VERSION ""

NS_ :

BS_:

BU_: PowertrainControlModule AtmosphericSensor SafetyRestraintSystem2 Aftertreatment_2_GasOutlet Aftertreatment_2_GasIntake DieselParticulateFilterControl Turbocharger SafetyRestraintSystem1 CabDisplay2 Aftertreatment_1_GasOutlet Aftertreatment_1_GasIntake OnBoardDataLogger OffBoardDiagnosticTool2 OffBoardDiagnosticTool1 FileServer ParkingBrakeController SeatController2 FanDriveController SteeringColumnUnit CommunicationUnitRadio CommunicationUnitSatellite CommunicationUnitCellular PropulsionBatteryCharger ChassisController2 ChassisController1 EngineValveControl AuxiliaryHeater2 AuxiliaryHeater1 ClutchUnit RampControl InformationSystem1 SuspensionSystemController2 OilSensor VehicleDynamicStability ExhaustEmissionController TransmissionDisplay2 TransmissionDisplay1 ClimateControl2 WaterPumpController RearAxleSteeringController LightingOperatorControl SeatController1 IgnitionController2 IgnitionController1 TirePressureController CabController2 CabController1 PneumaticSystemController SuspensionSystemController1 HydraulicPumpController EnduranceBrakingSystem RetarderExhaustEngine2 OnBoardDiagnosticUnit HeadwayController RetarderExhaustEngine1 CabDisplay1 ManagementComputer VirtualTerminal OffVehicleGateway PowerTakeOffFront HitchControl AuxiliaryValveControl BodyController TractorTrailerBridge1 StarterSystem ElectricalSystem VehicleSecurity VehicleNavigation AerodynamicControl ElectricalChargingSystem ClimateControl1 TripRecorder InstrumentCluster SuspensionDriveAxle2 SuspensionDriveAxle1 SuspensionSteerAxle SteeringController FuelSystem CruiseControl RetarderDriveline RetarderEngine BrakesDriveAxle2 BrakesDriveAxle1 BrakesSystemController BrakesSteerAxle AxleDrive2 AxleDrive1 AxleSteering PowerTakeOff ShiftConsoleSecondary ShiftConsolePrimary Transmission2 Transmission1 Engine2 Engine1

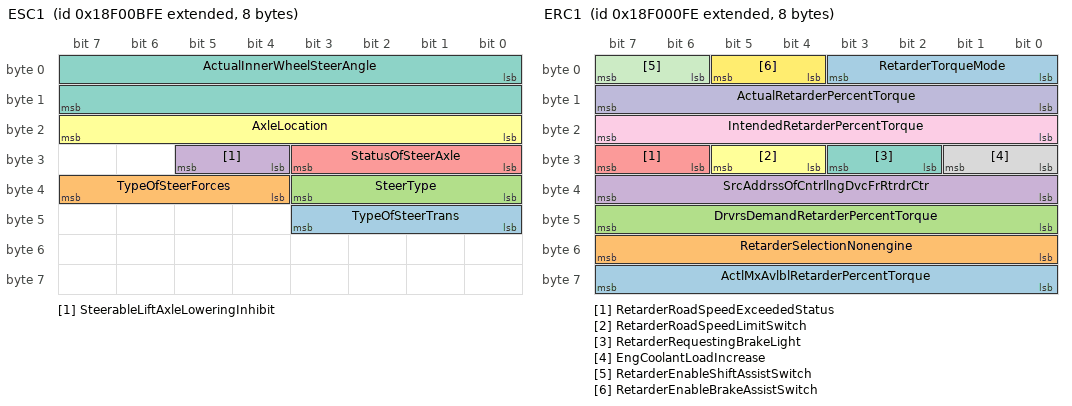
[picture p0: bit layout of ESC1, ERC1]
BO_ 2565868542 ESC1: 8 Vector__XXX
 SG_ TypeOfSteerTrans : 40|4@1+ (1,0) [0|15] "" Vector__XXX
 SG_ TypeOfSteerForces : 36|4@1+ (1,0) [0|15] "" Vector__XXX
 SG_ SteerType : 32|4@1+ (1,0) [0|15] "" Vector__XXX
 SG_ SteerableLiftAxleLoweringInhibit : 28|2@1+ (1,0) [0|3] "" Vector__XXX
 SG_ StatusOfSteerAxle : 24|4@1+ (1,0) [0|15] "" Vector__XXX
 SG_ AxleLocation : 16|8@1+ (1,0) [0|255] "" Vector__XXX
 SG_ ActualInnerWheelSteerAngle : 0|16@1+ (0.00390625,-125) [-125|125] "deg" Vector__XXX

BO_ 2633941758 ERC2: 8 Vector__XXX
 SG_ CrsCtrlRetarderActiveSpeedOffset : 8|16@1+ (0.00390625,-125) [0|125.996] "km/h" Vector__XXX
 SG_ TransOutputRetarder : 0|2@1+ (1,0) [0|3] "" Vector__XXX

BO_ 2565865726 ERC1: 8 Vector__XXX
 SG_ ActlMxAvlblRetarderPercentTorque : 56|8@1+ (1,-125) [-125|0] "%" Vector__XXX
 SG_ RetarderSelectionNonengine : 48|8@1+ (0.4,0) [0|100] "%" Vector__XXX
 SG_ DrvrsDemandRetarderPercentTorque : 40|8@1+ (1,-125) [-125|0] "%" Vector__XXX
 SG_ SrcAddrssOfCntrllngDvcFrRtrdrCtr : 32|8@1+ (1,0) [0|253] "" Vector__XXX
 SG_ RetarderRoadSpeedExceededStatus : 30|2@1+ (1,0) [0|3] "" Vector__XXX
 SG_ RetarderRoadSpeedLimitSwitch : 28|2@1+ (1,0) [0|3] "" Vector__XXX
 SG_ RetarderRequestingBrakeLight : 26|2@1+ (1,0) [0|3] "" Vector__XXX
 SG_ EngCoolantLoadIncrease : 24|2@1+ (1,0) [0|3] "" Vector__XXX
 SG_ IntendedRetarderPercentTorque : 16|8@1+ (1,-125) [-125|0] "%" Vector__XXX
 SG_ ActualRetarderPercentTorque : 8|8@1+ (1,-125) [-125|0] "%" Vector__XXX
 SG_ RetarderEnableShiftAssistSwitch : 6|2@1+ (1,0) [0|3] "" Vector__XXX
 SG_ RetarderEnableBrakeAssistSwitch : 4|2@1+ (1,0) [0|3] "" Vector__XXX
 SG_ RetarderTorqueMode : 0|4@1+ (1,0) [0|15] "" Vector__XXX

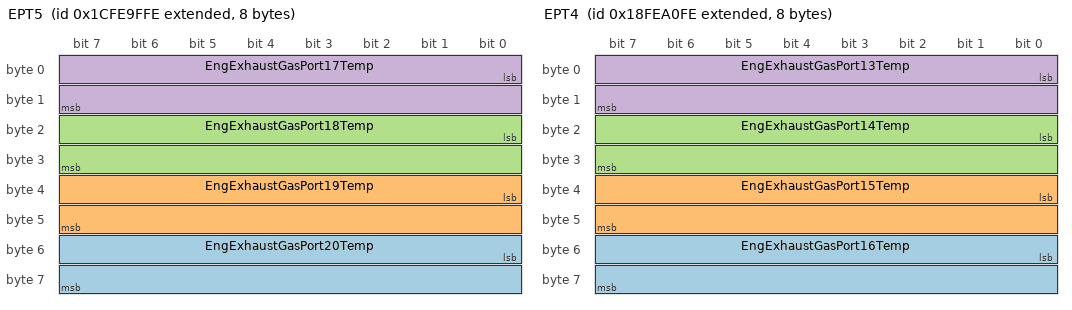
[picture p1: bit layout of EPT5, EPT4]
BO_ 2633932798 EPT5: 8 Vector__XXX
 SG_ EngExhaustGasPort20Temp : 48|16@1+ (0.03125,-273) [-273|1734.96875] "캜" Vector__XXX
 SG_ EngExhaustGasPort19Temp : 32|16@1+ (0.03125,-273) [-273|1734.96875] "캜" Vector__XXX
 SG_ EngExhaustGasPort18Temp : 16|16@1+ (0.03125,-273) [-273|1734.96875] "캜" Vector__XXX
 SG_ EngExhaustGasPort17Temp : 0|16@1+ (0.03125,-273) [-273|1734.96875] "캜" Vector__XXX

BO_ 2566824190 EPT4: 8 Vector__XXX
 SG_ EngExhaustGasPort16Temp : 48|16@1+ (0.03125,-273) [-273|1734.96875] "캜" Vector__XXX
 SG_ EngExhaustGasPort15Temp : 32|16@1+ (0.03125,-273) [-273|1734.96875] "캜" Vector__XXX
 SG_ EngExhaustGasPort14Temp : 16|16@1+ (0.03125,-273) [-273|1734.96875] "캜" Vector__XXX
 SG_ EngExhaustGasPort13Temp : 0|16@1+ (0.03125,-273) [-273|1734.96875] "캜" Vector__XXX

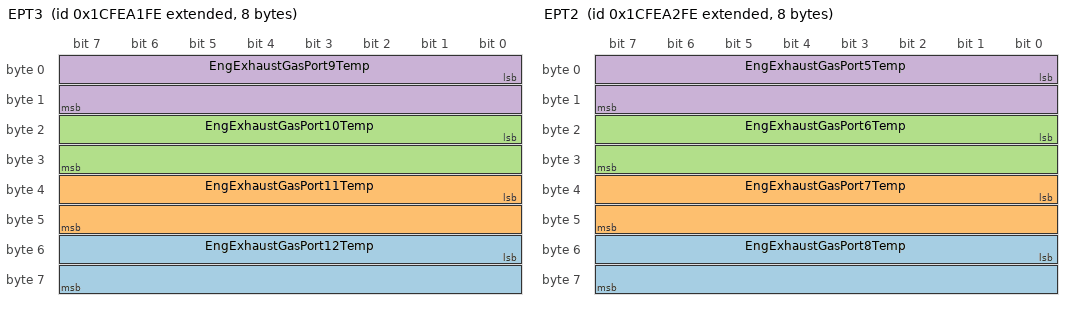
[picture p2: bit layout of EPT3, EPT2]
BO_ 2633933310 EPT3: 8 Vector__XXX
 SG_ EngExhaustGasPort12Temp : 48|16@1+ (0.03125,-273) [-273|1734.96875] "캜" Vector__XXX
 SG_ EngExhaustGasPort11Temp : 32|16@1+ (0.03125,-273) [-273|1734.96875] "캜" Vector__XXX
 SG_ EngExhaustGasPort10Temp : 16|16@1+ (0.03125,-273) [-273|1734.96875] "캜" Vector__XXX
 SG_ EngExhaustGasPort9Temp : 0|16@1+ (0.03125,-273) [-273|1734.96875] "캜" Vector__XXX

BO_ 2633933566 EPT2: 8 Vector__XXX
 SG_ EngExhaustGasPort8Temp : 48|16@1+ (0.03125,-273) [-273|1734.96875] "캜" Vector__XXX
 SG_ EngExhaustGasPort7Temp : 32|16@1+ (0.03125,-273) [-273|1734.96875] "캜" Vector__XXX
 SG_ EngExhaustGasPort6Temp : 16|16@1+ (0.03125,-273) [-273|1734.96875] "캜" Vector__XXX
 SG_ EngExhaustGasPort5Temp : 0|16@1+ (0.03125,-273) [-273|1734.96875] "캜" Vector__XXX

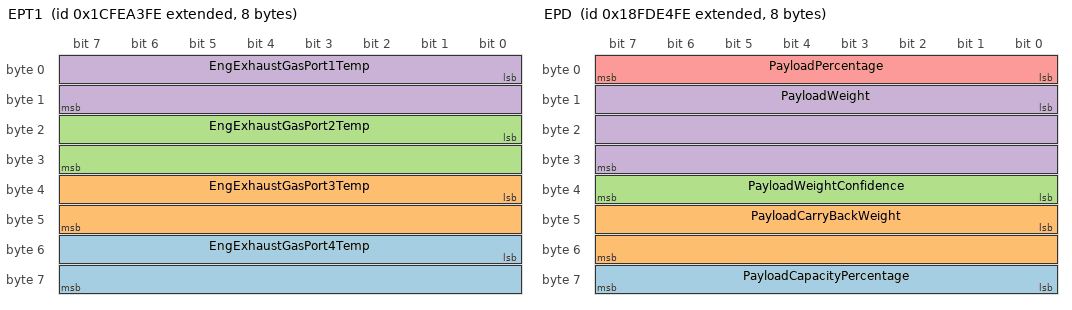
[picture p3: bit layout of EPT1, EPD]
BO_ 2633933822 EPT1: 8 Vector__XXX
 SG_ EngExhaustGasPort4Temp : 48|16@1+ (0.03125,-273) [-273|1734.96875] "캜" Vector__XXX
 SG_ EngExhaustGasPort3Temp : 32|16@1+ (0.03125,-273) [-273|1734.96875] "캜" Vector__XXX
 SG_ EngExhaustGasPort2Temp : 16|16@1+ (0.03125,-273) [-273|1734.96875] "캜" Vector__XXX
 SG_ EngExhaustGasPort1Temp : 0|16@1+ (0.03125,-273) [-273|1734.96875] "캜" Vector__XXX

BO_ 2566776062 EPD: 8 Vector__XXX
 SG_ PayloadCapacityPercentage : 56|8@1+ (1,0) [0|250] "%" Vector__XXX
 SG_ PayloadCarryBackWeight : 40|16@1+ (2,0) [0|128510] "kg" Vector__XXX
 SG_ PayloadWeightConfidence : 32|8@1+ (0.5,0) [0|100] "%" Vector__XXX
 SG_ PayloadWeight : 8|24@1+ (2,0) [0|32899070] "kg" Vector__XXX
 SG_ PayloadPercentage : 0|8@1+ (1,0) [0|250] "%" Vector__XXX

BO_ 2566771454 EP: 8 Vector__XXX
 SG_ DataMemoryUsage : 16|8@1+ (0.4,0) [0|100] "%" Vector__XXX
 SG_ KeepAliveBatteryConsumption : 0|16@1+ (1,0) [0|64255] "mAh" Vector__XXX

BO_ 2566775806 EOAC: 8 Vector__XXX
 SG_ TravelVelocityCtrlPos : 0|8@1+ (1,-125) [-125|125] "%" Vector__XXX

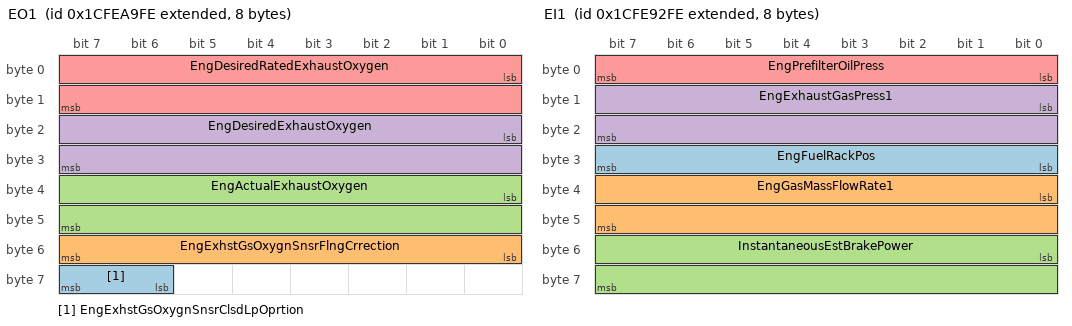
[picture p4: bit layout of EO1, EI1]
BO_ 2633935358 EO1: 8 Vector__XXX
 SG_ EngExhstGsOxygnSnsrClsdLpOprtion : 62|2@1+ (1,0) [0|3] "" Vector__XXX
 SG_ EngExhstGsOxygnSnsrFlngCrrection : 48|8@1+ (1,-125) [-125|125] "%" Vector__XXX
 SG_ EngActualExhaustOxygen : 32|16@1+ (0.0025,0) [0|160.6375] "%" Vector__XXX
 SG_ EngDesiredExhaustOxygen : 16|16@1+ (0.0025,0) [0|160.6375] "%" Vector__XXX
 SG_ EngDesiredRatedExhaustOxygen : 0|16@1+ (0.0025,0) [0|160.6375] "%" Vector__XXX

BO_ 2365447166 EJM3: 8 Vector__XXX
 SG_ Joystick3Button13PressedStatus : 62|2@1+ (1,0) [0|3] "" Vector__XXX
 SG_ Joystick3Button14PressedStatus : 60|2@1+ (1,0) [0|3] "" Vector__XXX
 SG_ Joystick3Button15PressedStatus : 58|2@1+ (1,0) [0|3] "" Vector__XXX
 SG_ Joystick3Button16PressedStatus : 56|2@1+ (1,0) [0|3] "" Vector__XXX
 SG_ Jystick3GripXAxisDetentPosStatus : 54|2@1+ (1,0) [0|3] "" Vector__XXX
 SG_ Jystick3GripYAxisDetentPosStatus : 52|2@1+ (1,0) [0|3] "" Vector__XXX
 SG_ Jystick3ThetaAxisDetentPosStatus : 50|2@1+ (1,0) [0|3] "" Vector__XXX
 SG_ Joystick3ThetaAxisPos : 38|10@1+ (0.1,0) [0|100] "%" Vector__XXX
 SG_ Jystck3ThtAxsClckwsPstvPosStatus : 36|2@1+ (1,0) [0|3] "" Vector__XXX
 SG_ Jystck3ThetaAxisNeutralPosStatus : 32|2@1+ (1,0) [0|3] "" Vector__XXX
 SG_ Joystick3GripYAxisPos : 22|10@1+ (0.1,0) [0|100] "%" Vector__XXX
 SG_ Jystck3GrpYAxsLvrFrwrdPstvPsStts : 20|2@1+ (1,0) [0|3] "" Vector__XXX
 SG_ Jystck3GrpYAxsLvrBckNgtvPsStatus : 18|2@1+ (1,0) [0|3] "" Vector__XXX
 SG_ Jystck3GripYAxisNeutralPosStatus : 16|2@1+ (1,0) [0|3] "" Vector__XXX
 SG_ Joystick3GripXAxisPos : 6|10@1+ (0.1,0) [0|100] "%" Vector__XXX
 SG_ Jystck3GrpXAxsLvrRghtPstvPsSttus : 4|2@1+ (1,0) [0|3] "" Vector__XXX
 SG_ Jystck3GrpXAxsLvrLftNgtvPsStatus : 2|2@1+ (1,0) [0|3] "" Vector__XXX
 SG_ Jystck3GripXAxisNeutralPosStatus : 0|2@1+ (1,0) [0|3] "" Vector__XXX
 SG_ Jystck3ThtAxsCntrClckwsNgtvPsStt : 34|2@1+ (1,0) [0|3] "" Vector__XXX

BO_ 2365446654 EJM2: 8 Vector__XXX
 SG_ Joystick2Button13PressedStatus : 62|2@1+ (1,0) [0|3] "" Vector__XXX
 SG_ Joystick2Button14PressedStatus : 60|2@1+ (1,0) [0|3] "" Vector__XXX
 SG_ Joystick2Button15PressedStatus : 58|2@1+ (1,0) [0|3] "" Vector__XXX
 SG_ Joystick2Button16PressedStatus : 56|2@1+ (1,0) [0|3] "" Vector__XXX
 SG_ Jystick2GripXAxisDetentPosStatus : 54|2@1+ (1,0) [0|3] "" Vector__XXX
 SG_ Jystick2GripYAxisDetentPosStatus : 52|2@1+ (1,0) [0|3] "" Vector__XXX
 SG_ Jystick2ThetaAxisDetentPosStatus : 50|2@1+ (1,0) [0|3] "" Vector__XXX
 SG_ Joystick2ThetaAxisPos : 38|10@1+ (0.1,0) [0|100] "%" Vector__XXX
 SG_ Jystck2ThtAxsClckwsPstvPosStatus : 36|2@1+ (1,0) [0|3] "" Vector__XXX
 SG_ Jystck2ThetaAxisNeutralPosStatus : 32|2@1+ (1,0) [0|3] "" Vector__XXX
 SG_ Joystick2GripYAxisPos : 22|10@1+ (0.1,0) [0|100] "%" Vector__XXX
 SG_ Jystck2GrpYAxsLvrFrwrdPstvPsStts : 20|2@1+ (1,0) [0|3] "" Vector__XXX
 SG_ Jystck2GrpYAxsLvrBckNgtvPsStatus : 18|2@1+ (1,0) [0|3] "" Vector__XXX
 SG_ Jystck2GripYAxisNeutralPosStatus : 16|2@1+ (1,0) [0|3] "" Vector__XXX
 SG_ Joystick2GripXAxisPos : 6|10@1+ (0.1,0) [0|100] "%" Vector__XXX
 SG_ Jystck2GrpXAxsLvrRghtPstvPsSttus : 4|2@1+ (1,0) [0|3] "" Vector__XXX
 SG_ Jystck2GrpXAxsLvrLftNgtvPsStatus : 2|2@1+ (1,0) [0|3] "" Vector__XXX
 SG_ Jystck2GripXAxisNeutralPosStatus : 0|2@1+ (1,0) [0|3] "" Vector__XXX
 SG_ Jystck2ThtAxsCntrClckwsNgtvPsStt : 34|2@1+ (1,0) [0|3] "" Vector__XXX

BO_ 2365446142 EJM1: 8 Vector__XXX
 SG_ Joystick1Button13PressedStatus : 62|2@1+ (1,0) [0|3] "" Vector__XXX
 SG_ Joystick1Button14PressedStatus : 60|2@1+ (1,0) [0|3] "" Vector__XXX
 SG_ Joystick1Button15PressedStatus : 58|2@1+ (1,0) [0|3] "" Vector__XXX
 SG_ Joystick1Button16PressedStatus : 56|2@1+ (1,0) [0|3] "" Vector__XXX
 SG_ Jystick1GripXAxisDetentPosStatus : 54|2@1+ (1,0) [0|3] "" Vector__XXX
 SG_ Jystick1GripYAxisDetentPosStatus : 52|2@1+ (1,0) [0|3] "" Vector__XXX
 SG_ Jystick1ThetaAxisDetentPosStatus : 50|2@1+ (1,0) [0|3] "" Vector__XXX
 SG_ Joystick1ThetaAxisPos : 38|10@1+ (0.1,0) [0|100] "%" Vector__XXX
 SG_ Jystck1ThtAxsClckwsPstvPosStatus : 36|2@1+ (1,0) [0|3] "" Vector__XXX
 SG_ Jystck1ThetaAxisNeutralPosStatus : 32|2@1+ (1,0) [0|3] "" Vector__XXX
 SG_ Joystick1GripYAxisPos : 22|10@1+ (0.1,0) [0|100] "%" Vector__XXX
 SG_ Jystck1GrpYAxsLvrFrwrdPstvPsStts : 20|2@1+ (1,0) [0|3] "" Vector__XXX
 SG_ Jystck1GrpYAxsLvrBckNgtvPsStatus : 18|2@1+ (1,0) [0|3] "" Vector__XXX
 SG_ Aftrtrtmnt1DslExhstFldPrprtsPrlm : 16|2@1+ (1,0) [0|3] "" Vector__XXX
 SG_ Joystick1GripXAxisPos : 6|10@1+ (0.1,0) [0|100] "%" Vector__XXX
 SG_ Jystck1GrpXAxsLvrRghtPstvPsSttus : 4|2@1+ (1,0) [0|3] "" Vector__XXX
 SG_ Jystck1GrpXAxsLvrLftNgtvPsStatus : 2|2@1+ (1,0) [0|3] "" Vector__XXX
 SG_ Jystck1GripXAxisNeutralPosStatus : 0|2@1+ (1,0) [0|3] "" Vector__XXX
 SG_ Jystck1ThtAxsCntrClckwsNgtvPsStt : 34|2@1+ (1,0) [0|3] "" Vector__XXX

BO_ 2633929470 EI1: 8 Vector__XXX
 SG_ EngFuelRackPos : 24|8@1+ (0.4,0) [0|100] "%" Vector__XXX
 SG_ EngGasMassFlowRate1 : 32|16@1+ (0.05,0) [0|3212.75] "kg/h" Vector__XXX
 SG_ InstantaneousEstBrakePower : 48|16@1+ (0.5,0) [0|32127.5] "kW" Vector__XXX
 SG_ EngExhaustGasPress1 : 8|16@1+ (0.0078125,-250) [-250|251.99] "kPa" Vector__XXX
 SG_ EngPrefilterOilPress : 0|8@1+ (4,0) [0|1000] "kPa" Vector__XXX

BO_ 2633937406 EH: 8 Vector__XXX
 SG_ TotalECURunTime : 32|32@1+ (0.05,0) [0|210554060.75] "h" Vector__XXX
 SG_ TotalECUDistance : 0|32@1+ (0.125,0) [0|526385151.875] "km" Vector__XXX

BO_ 2364541694 EGF1: 8 Vector__XXX
 SG_ EngExhstGsRcrcltion2MassFlowRate : 32|16@1+ (0.05,0) [0|3212.75] "kg/h" Vector__XXX
 SG_ EngIntakeAirMassFlowRate : 16|16@1+ (0.05,0) [0|3212.75] "kg/h" Vector__XXX
 SG_ EngExhstGsRcrcltion1MassFlowRate : 0|16@1+ (0.05,0) [0|3212.75] "kg/h" Vector__XXX

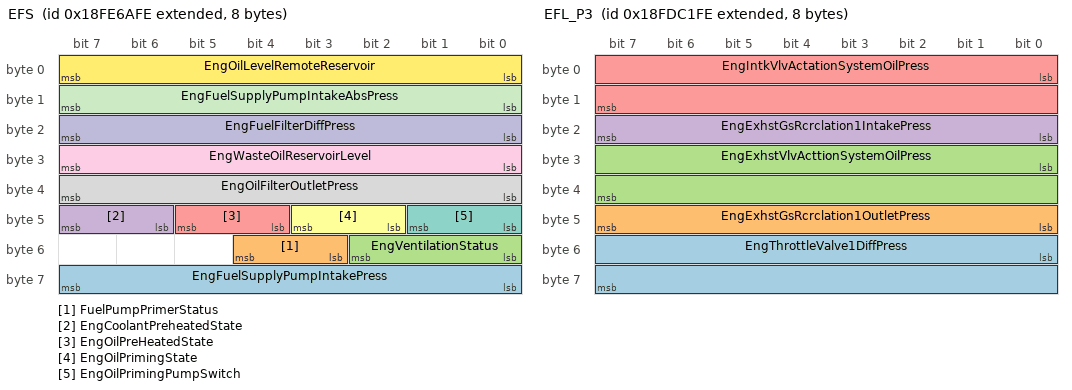
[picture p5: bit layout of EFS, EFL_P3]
BO_ 2566810366 EFS: 8 Vector__XXX
 SG_ EngFuelSupplyPumpIntakePress : 56|8@1+ (2,0) [0|500] "kPa" Vector__XXX
 SG_ FuelPumpPrimerStatus : 51|2@1+ (1,0) [0|3] "" Vector__XXX
 SG_ EngVentilationStatus : 48|3@1+ (1,0) [0|7] "" Vector__XXX
 SG_ EngCoolantPreheatedState : 46|2@1+ (1,0) [0|3] "" Vector__XXX
 SG_ EngOilPreHeatedState : 44|2@1+ (1,0) [0|3] "" Vector__XXX
 SG_ EngOilPrimingState : 42|2@1+ (1,0) [0|3] "" Vector__XXX
 SG_ EngOilPrimingPumpSwitch : 40|2@1+ (1,0) [0|3] "" Vector__XXX
 SG_ EngOilFilterOutletPress : 32|8@1+ (4,0) [0|1000] "kPa" Vector__XXX
 SG_ EngWasteOilReservoirLevel : 24|8@1+ (0.4,0) [0|100] "%" Vector__XXX
 SG_ EngFuelFilterDiffPress : 16|8@1+ (2,0) [0|500] "kPa" Vector__XXX
 SG_ EngFuelSupplyPumpIntakeAbsPress : 8|8@1+ (2,0) [0|500] "kPa" Vector__XXX
 SG_ EngOilLevelRemoteReservoir : 0|8@1+ (0.4,0) [0|100] "%" Vector__XXX

BO_ 2566767102 EFL_P3: 8 Vector__XXX
 SG_ EngThrottleValve1DiffPress : 48|16@1+ (0.1,0) [0|6425.5] "kPa" Vector__XXX
 SG_ EngExhstGsRcrclation1OutletPress : 40|8@1+ (2,0) [0|500] "kPa" Vector__XXX
 SG_ EngExhstVlvActtionSystemOilPress : 24|16@1+ (0.00390625,0) [0|250.996] "MPa" Vector__XXX
 SG_ EngExhstGsRcrclation1IntakePress : 16|8@1+ (2,0) [0|500] "kPa" Vector__XXX
 SG_ EngIntkVlvActationSystemOilPress : 0|16@1+ (0.00390625,0) [0|250.996] "MPa" Vector__XXX

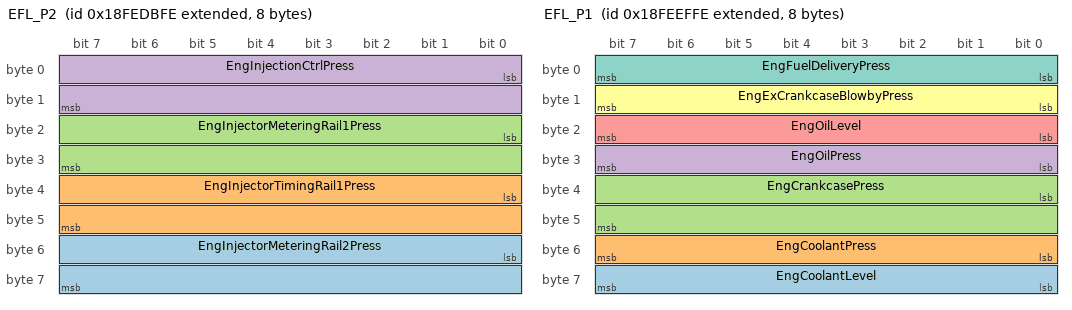
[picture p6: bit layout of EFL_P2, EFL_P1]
BO_ 2566839294 EFL_P2: 8 Vector__XXX
 SG_ EngInjectorMeteringRail2Press : 48|16@1+ (0.00390625,0) [0|250.996] "MPa" Vector__XXX
 SG_ EngInjectorTimingRail1Press : 32|16@1+ (0.00390625,0) [0|250.996] "MPa" Vector__XXX
 SG_ EngInjectorMeteringRail1Press : 16|16@1+ (0.00390625,0) [0|250.996] "MPa" Vector__XXX
 SG_ EngInjectionCtrlPress : 0|16@1+ (0.00390625,0) [0|250.996] "MPa" Vector__XXX

BO_ 2566844414 EFL_P1: 8 Vector__XXX
 SG_ EngCoolantLevel : 56|8@1+ (0.4,0) [0|100] "%" Vector__XXX
 SG_ EngCoolantPress : 48|8@1+ (2,0) [0|500] "kPa" Vector__XXX
 SG_ EngCrankcasePress : 32|16@1+ (0.0078125,-250) [-250|251.99] "kPa" Vector__XXX
 SG_ EngOilPress : 24|8@1+ (4,0) [0|1000] "kPa" Vector__XXX
 SG_ EngOilLevel : 16|8@1+ (0.4,0) [0|100] "%" Vector__XXX
 SG_ EngExCrankcaseBlowbyPress : 8|8@1+ (0.05,0) [0|12.5] "kPa" Vector__XXX
 SG_ EngFuelDeliveryPress : 0|8@1+ (4,0) [0|1000] "kPa" Vector__XXX

BO_ 2633929726 EES: 8 Vector__XXX
 SG_ SafetyWireStatus : 16|2@1+ (1,0) [0|3] "" Vector__XXX
 SG_ ElectricalLoad : 0|16@1+ (0.5,0) [0|32127.5] "kW" Vector__XXX

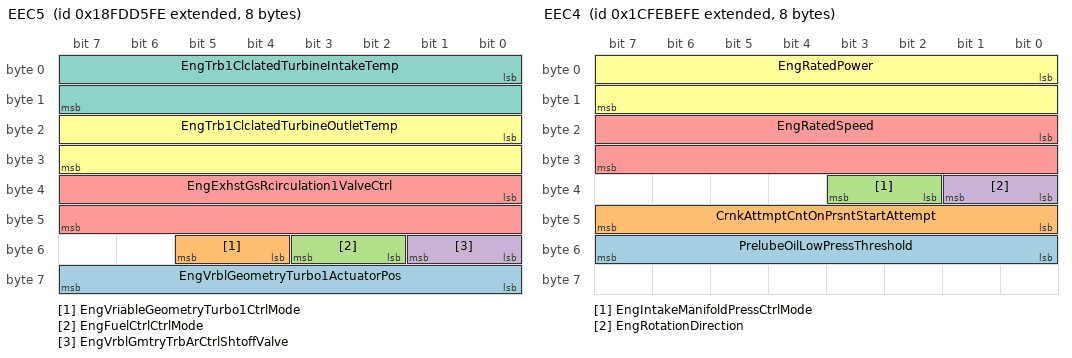
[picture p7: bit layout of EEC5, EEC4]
BO_ 2566772222 EEC5: 8 Vector__XXX
 SG_ EngVrblGeometryTurbo1ActuatorPos : 56|8@1+ (0.4,0) [0|100] "%" Vector__XXX
 SG_ EngVriableGeometryTurbo1CtrlMode : 52|2@1+ (1,0) [0|3] "" Vector__XXX
 SG_ EngFuelCtrlCtrlMode : 50|2@1+ (1,0) [0|3] "" Vector__XXX
 SG_ EngVrblGmtryTrbArCtrlShtoffValve : 48|2@1+ (1,0) [0|3] "" Vector__XXX
 SG_ EngExhstGsRcirculation1ValveCtrl : 32|16@1+ (0.0025,0) [0|100] "%" Vector__XXX
 SG_ EngTrb1ClclatedTurbineOutletTemp : 16|16@1+ (0.03125,-273) [-273|1734.96875] "캜" Vector__XXX
 SG_ EngTrb1ClclatedTurbineIntakeTemp : 0|16@1+ (0.03125,-273) [-273|1734.96875] "캜" Vector__XXX

BO_ 2633940734 EEC4: 8 Vector__XXX
 SG_ PrelubeOilLowPressThreshold : 48|8@1+ (4,0) [0|1000] "kPa" Vector__XXX
 SG_ CrnkAttmptCntOnPrsntStartAttempt : 40|8@1+ (1,0) [0|250] "" Vector__XXX
 SG_ EngIntakeManifoldPressCtrlMode : 34|2@1+ (1,0) [0|3] "" Vector__XXX
 SG_ EngRotationDirection : 32|2@1+ (1,0) [0|3] "" Vector__XXX
 SG_ EngRatedSpeed : 16|16@1+ (0.125,0) [0|8031.875] "rpm" Vector__XXX
 SG_ EngRatedPower : 0|16@1+ (0.5,0) [0|32127.5] "kW" Vector__XXX

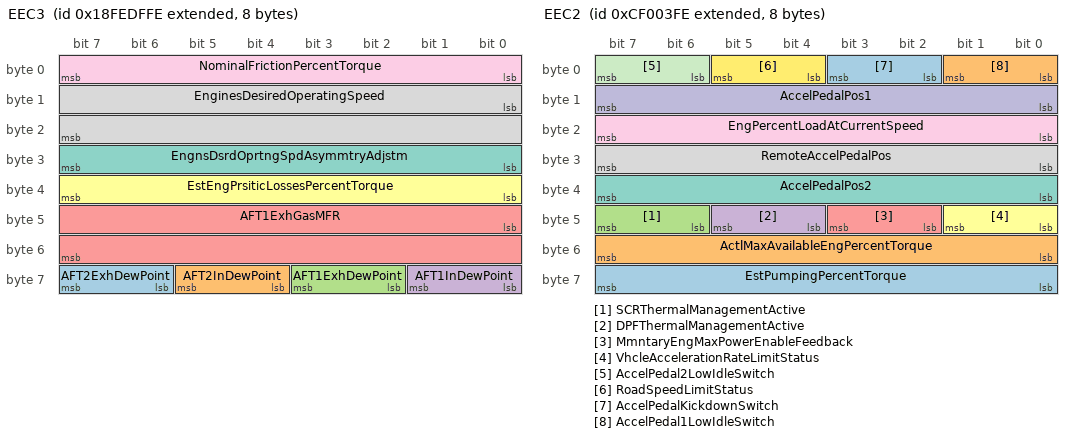
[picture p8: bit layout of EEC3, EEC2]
BO_ 2566840318 EEC3: 8 Vector__XXX
 SG_ AFT2ExhDewPoint : 62|2@1+ (1,0) [0|3] "" Vector__XXX
 SG_ AFT2InDewPoint : 60|2@1+ (1,0) [0|3] "" Vector__XXX
 SG_ AFT1ExhDewPoint : 58|2@1+ (1,0) [0|3] "" Vector__XXX
 SG_ AFT1InDewPoint : 56|2@1+ (1,0) [0|3] "" Vector__XXX
 SG_ AFT1ExhGasMFR : 40|16@1+ (0.2,0) [0|12851] "kg/h" Vector__XXX
 SG_ EstEngPrsiticLossesPercentTorque : 32|8@1+ (1,-125) [0|125] "%" Vector__XXX
 SG_ EngnsDsrdOprtngSpdAsymmtryAdjstm : 24|8@1+ (1,0) [0|250] "" Vector__XXX
 SG_ EnginesDesiredOperatingSpeed : 8|16@1+ (0.125,0) [0|8031.875] "rpm" Vector__XXX
 SG_ NominalFrictionPercentTorque : 0|8@1+ (1,-125) [-125|125] "%" Vector__XXX

BO_ 2364539902 EEC2: 8 Vector__XXX
 SG_ EstPumpingPercentTorque : 56|8@1+ (1,-125) [-125|125] "%" Vector__XXX
 SG_ ActlMaxAvailableEngPercentTorque : 48|8@1+ (0.4,0) [0|100] "%" Vector__XXX
 SG_ SCRThermalManagementActive : 46|2@1+ (1,0) [0|3] "" Vector__XXX
 SG_ DPFThermalManagementActive : 44|2@1+ (1,0) [0|3] "" Vector__XXX
 SG_ MmntaryEngMaxPowerEnableFeedback : 42|2@1+ (1,0) [0|3] "" Vector__XXX
 SG_ VhcleAccelerationRateLimitStatus : 40|2@1+ (1,0) [0|3] "" Vector__XXX
 SG_ AccelPedalPos2 : 32|8@1+ (0.4,0) [0|100] "%" Vector__XXX
 SG_ RemoteAccelPedalPos : 24|8@1+ (0.4,0) [0|100] "%" Vector__XXX
 SG_ EngPercentLoadAtCurrentSpeed : 16|8@1+ (1,0) [0|125] "%" Vector__XXX
 SG_ AccelPedalPos1 : 8|8@1+ (0.4,0) [0|100] "%" Vector__XXX
 SG_ AccelPedal2LowIdleSwitch : 6|2@1+ (1,0) [0|3] "" Vector__XXX
 SG_ RoadSpeedLimitStatus : 4|2@1+ (1,0) [0|3] "" Vector__XXX
 SG_ AccelPedalKickdownSwitch : 2|2@1+ (1,0) [0|3] "" Vector__XXX
 SG_ AccelPedal1LowIdleSwitch : 0|2@1+ (1,0) [0|3] "" Vector__XXX

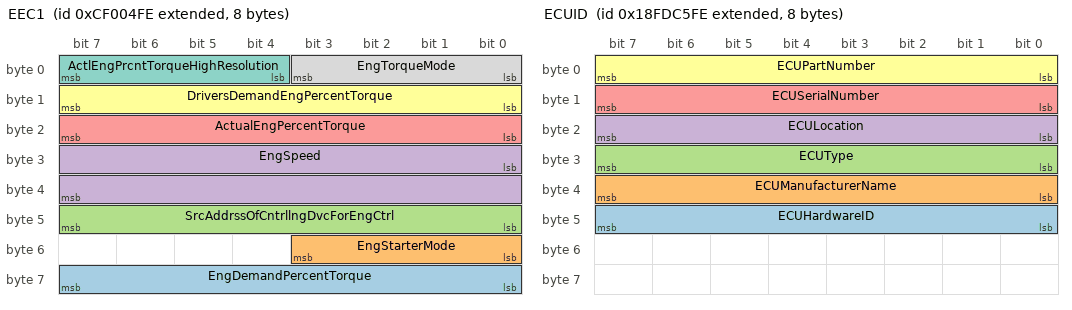
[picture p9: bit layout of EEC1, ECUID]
BO_ 2364540158 EEC1: 8 Vector__XXX
 SG_ EngDemandPercentTorque : 56|8@1+ (1,-125) [-125|125] "%" Vector__XXX
 SG_ EngStarterMode : 48|4@1+ (1,0) [0|15] "" Vector__XXX
 SG_ SrcAddrssOfCntrllngDvcForEngCtrl : 40|8@1+ (1,0) [0|253] "" Vector__XXX
 SG_ EngSpeed : 24|16@1+ (0.125,0) [0|8031.875] "rpm" Vector__XXX
 SG_ ActualEngPercentTorque : 16|8@1+ (1,-125) [0|125] "%" Vector__XXX
 SG_ DriversDemandEngPercentTorque : 8|8@1+ (1,-125) [0|125] "%" Vector__XXX
 SG_ ActlEngPrcntTorqueHighResolution : 4|4@1+ (0.125,0) [0|0.875] "%" Vector__XXX
 SG_ EngTorqueMode : 0|4@1+ (1,0) [0|15] "" Vector__XXX

BO_ 2566768126 ECUID: 8 Vector__XXX
 SG_ ECUHardwareID : 40|8@1+ (1,0) [0|255] "" Vector__XXX
 SG_ ECUManufacturerName : 32|8@1+ (1,0) [0|255] "" Vector__XXX
 SG_ ECUType : 24|8@1+ (1,0) [0|255] "" Vector__XXX
 SG_ ECULocation : 16|8@1+ (1,0) [0|255] "" Vector__XXX
 SG_ ECUSerialNumber : 8|8@1+ (1,0) [0|255] "" Vector__XXX
 SG_ ECUPartNumber : 0|8@1+ (1,0) [0|255] "" Vector__XXX

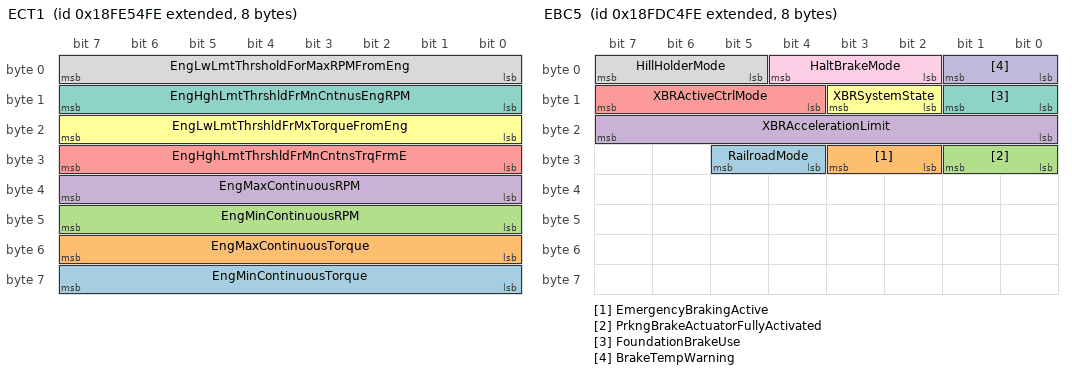
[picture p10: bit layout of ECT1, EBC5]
BO_ 2566804734 ECT1: 8 Vector__XXX
 SG_ EngMinContinuousTorque : 56|8@1+ (1,-125) [-125|125] "%" Vector__XXX
 SG_ EngMaxContinuousTorque : 48|8@1+ (1,-125) [-125|125] "%" Vector__XXX
 SG_ EngMinContinuousRPM : 40|8@1+ (32,0) [0|8000] "rpm" Vector__XXX
 SG_ EngMaxContinuousRPM : 32|8@1+ (32,0) [0|8000] "rpm" Vector__XXX
 SG_ EngHghLmtThrshldFrMnCntnsTrqFrmE : 24|8@1+ (1,-125) [-125|125] "%" Vector__XXX
 SG_ EngLwLmtThrshldFrMxTorqueFromEng : 16|8@1+ (1,-125) [-125|125] "%" Vector__XXX
 SG_ EngHghLmtThrshldFrMnCntnusEngRPM : 8|8@1+ (32,0) [0|8000] "rpm" Vector__XXX
 SG_ EngLwLmtThrsholdForMaxRPMFromEng : 0|8@1+ (32,0) [0|8000] "rpm" Vector__XXX

BO_ 2566841342 EC1: 40 Vector__XXX
 SG_ DefaultIdleTrqLmt : 312|8@1+ (1,-125) [0|125] "%" Vector__XXX
 SG_ SupportTSC1CtrlPurposeGroup4 : 304|8@1+ (1,0) [0|255] "" Vector__XXX
 SG_ SupportTSC1CtrlPurposeGroup3 : 296|8@1+ (1,0) [0|255] "" Vector__XXX
 SG_ SupportTSC1CtrlPurposeGroup2 : 288|8@1+ (1,0) [0|255] "" Vector__XXX
 SG_ SupportTSC1CtrlPurposeGroup1 : 280|8@1+ (1,0) [0|255] "" Vector__XXX
 SG_ SupportVariableRateTSC1Message : 272|8@1+ (1,0) [0|255] "" Vector__XXX
 SG_ EngDefaultTorqueLimit : 256|16@1+ (1,0) [0|64255] "Nm" Vector__XXX
 SG_ EngMomentOfInertia : 240|16@1+ (0.004,0) [0|257.02] "kg븁�" Vector__XXX
 SG_ EngExRngRqstdSpdCtrlRngUpprLimit : 224|16@1+ (0.125,0) [0|8031.875] "rpm" Vector__XXX
 SG_ EngRqstdTrqueCtrlRangeUpperLimit : 216|8@1+ (1,-125) [0|125] "%" Vector__XXX
 SG_ EngRqstdTrqueCtrlRangeLowerLimit : 208|8@1+ (1,-125) [0|125] "%" Vector__XXX
 SG_ EngRqstdSpeedCtrlRangeUpperLimit : 200|8@1+ (10,0) [0|2500] "rpm" Vector__XXX
 SG_ EngRqstdSpeedCtrlRangeLowerLimit : 192|8@1+ (10,0) [0|2500] "rpm" Vector__XXX
 SG_ EngMaxMomentaryOverrideTimeLimit : 184|8@1+ (0.1,0) [0|25] "s" Vector__XXX
 SG_ EngMxMmentaryOverrideSpeedPoint7 : 168|16@1+ (0.125,0) [0|8031.875] "rpm" Vector__XXX
 SG_ EngReferenceTorque : 152|16@1+ (1,0) [0|64255] "Nm" Vector__XXX
 SG_ EngGain : 136|16@1+ (0.00078125,0) [0|50.2] "%/rpm" Vector__XXX
 SG_ EngSpeedAtHighIdlePoint6 : 120|16@1+ (0.125,0) [0|8031.875] "rpm" Vector__XXX
 SG_ EngPercentTorqueAtPoint5 : 112|8@1+ (1,-125) [0|125] "%" Vector__XXX
 SG_ EngSpeedAtPoint5 : 96|16@1+ (0.125,0) [0|8031.875] "rpm" Vector__XXX
 SG_ EngPercentTorqueAtPoint4 : 88|8@1+ (1,-125) [0|125] "%" Vector__XXX
 SG_ EngSpeedAtPoint4 : 72|16@1+ (0.125,0) [0|8031.875] "rpm" Vector__XXX
 SG_ EngPercentTorqueAtPoint3 : 64|8@1+ (1,-125) [0|125] "%" Vector__XXX
 SG_ EngSpeedAtPoint3 : 48|16@1+ (0.125,0) [0|8031.875] "rpm" Vector__XXX
 SG_ EngPercentTorqueAtPoint2 : 40|8@1+ (1,-125) [0|125] "%" Vector__XXX
 SG_ EngSpeedAtPoint2 : 24|16@1+ (0.125,0) [0|8031.875] "rpm" Vector__XXX
 SG_ EngPercentTorqueAtIdlePoint1 : 16|8@1+ (1,-125) [0|125] "%" Vector__XXX
 SG_ EngSpeedAtIdlePoint1 : 0|16@1+ (0.125,0) [0|8031.875] "rpm" Vector__XXX

BO_ 2566767870 EBC5: 8 Vector__XXX
 SG_ RailroadMode : 28|2@1+ (1,0) [0|3] "" Vector__XXX
 SG_ EmergencyBrakingActive : 26|2@1+ (1,0) [0|3] "" Vector__XXX
 SG_ PrkngBrakeActuatorFullyActivated : 24|2@1+ (1,0) [0|3] "" Vector__XXX
 SG_ XBRAccelerationLimit : 16|8@1+ (0.1,-12.5) [-10|10] "m/s�" Vector__XXX
 SG_ XBRActiveCtrlMode : 12|4@1+ (1,0) [0|15] "" Vector__XXX
 SG_ XBRSystemState : 10|2@1+ (1,0) [0|3] "" Vector__XXX
 SG_ FoundationBrakeUse : 8|2@1+ (1,0) [0|3] "" Vector__XXX
 SG_ HillHolderMode : 5|3@1+ (1,0) [0|7] "" Vector__XXX
 SG_ HaltBrakeMode : 2|3@1+ (1,0) [0|7] "" Vector__XXX
 SG_ BrakeTempWarning : 0|2@1+ (1,0) [0|3] "" Vector__XXX

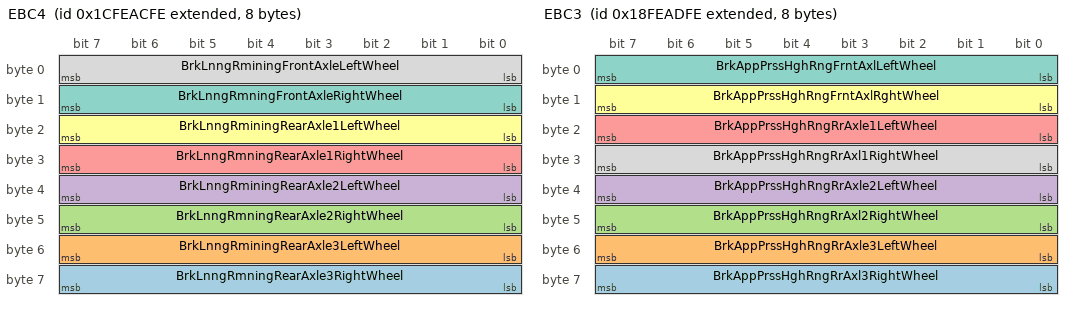
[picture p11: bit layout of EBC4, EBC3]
BO_ 2633936126 EBC4: 8 Vector__XXX
 SG_ BrkLnngRmningRearAxle3RightWheel : 56|8@1+ (0.4,0) [0|100] "%" Vector__XXX
 SG_ BrkLnngRminingRearAxle3LeftWheel : 48|8@1+ (0.4,0) [0|100] "%" Vector__XXX
 SG_ BrkLnngRmningRearAxle2RightWheel : 40|8@1+ (0.4,0) [0|100] "%" Vector__XXX
 SG_ BrkLnngRminingRearAxle2LeftWheel : 32|8@1+ (0.4,0) [0|100] "%" Vector__XXX
 SG_ BrkLnngRmningRearAxle1RightWheel : 24|8@1+ (0.4,0) [0|100] "%" Vector__XXX
 SG_ BrkLnngRminingRearAxle1LeftWheel : 16|8@1+ (0.4,0) [0|100] "%" Vector__XXX
 SG_ BrkLnngRmningFrontAxleRightWheel : 8|8@1+ (0.4,0) [0|100] "%" Vector__XXX
 SG_ BrkLnngRminingFrontAxleLeftWheel : 0|8@1+ (0.4,0) [0|100] "%" Vector__XXX

BO_ 2566827518 EBC3: 8 Vector__XXX
 SG_ BrkAppPrssHghRngRrAxl3RightWheel : 56|8@1+ (5,0) [0|1250] "kPa" Vector__XXX
 SG_ BrkAppPrssHghRngRrAxle3LeftWheel : 48|8@1+ (5,0) [0|1250] "kPa" Vector__XXX
 SG_ BrkAppPrssHghRngRrAxl2RightWheel : 40|8@1+ (5,0) [0|1250] "kPa" Vector__XXX
 SG_ BrkAppPrssHghRngRrAxle2LeftWheel : 32|8@1+ (5,0) [0|1250] "kPa" Vector__XXX
 SG_ BrkAppPrssHghRngRrAxle1LeftWheel : 16|8@1+ (5,0) [0|1250] "kPa" Vector__XXX
 SG_ BrkAppPrssHghRngFrntAxlRghtWheel : 8|8@1+ (5,0) [0|1250] "kPa" Vector__XXX
 SG_ BrkAppPrssHghRngFrntAxlLeftWheel : 0|8@1+ (5,0) [0|1250] "kPa" Vector__XXX
 SG_ BrkAppPrssHghRngRrAxl1RightWheel : 24|8@1+ (5,0) [0|1250] "kPa" Vector__XXX

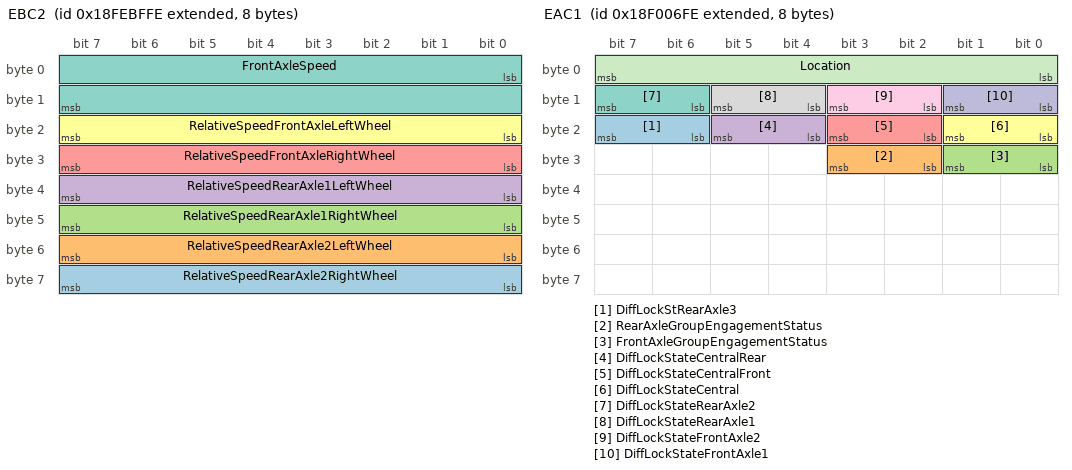
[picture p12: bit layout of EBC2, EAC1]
BO_ 2566832126 EBC2: 8 Vector__XXX
 SG_ RelativeSpeedRearAxle2RightWheel : 56|8@1+ (0.0625,-7.8125) [-7.8125|7.8125] "km/h" Vector__XXX
 SG_ RelativeSpeedRearAxle2LeftWheel : 48|8@1+ (0.0625,-7.8125) [-7.8125|7.8125] "km/h" Vector__XXX
 SG_ RelativeSpeedRearAxle1RightWheel : 40|8@1+ (0.0625,-7.8125) [-7.8125|7.8125] "km/h" Vector__XXX
 SG_ RelativeSpeedRearAxle1LeftWheel : 32|8@1+ (0.0625,-7.8125) [-7.8125|7.8125] "km/h" Vector__XXX
 SG_ RelativeSpeedFrontAxleRightWheel : 24|8@1+ (0.0625,-7.8125) [-7.8125|7.8125] "km/h" Vector__XXX
 SG_ RelativeSpeedFrontAxleLeftWheel : 16|8@1+ (0.0625,-7.8125) [-7.8125|7.8125] "km/h" Vector__XXX
 SG_ FrontAxleSpeed : 0|16@1+ (0.00390625,0) [0|250.996] "km/h" Vector__XXX

BO_ 2565865982 EBC1: 8 Vector__XXX
 SG_ RailroadModeSw : 56|2@1+ (1,0) [0|3] "" Vector__XXX
 SG_ TrctrMntdTrailerABSWarningSignal : 62|2@1+ (1,0) [0|3] "" Vector__XXX
 SG_ TrailerABSStatus : 60|2@1+ (1,0) [0|3] "" Vector__XXX
 SG_ HaltBrakeSwitch : 58|2@1+ (1,0) [0|3] "" Vector__XXX
 SG_ SrcAddrssOfCntrllngDvcFrBrkeCtrl : 48|8@1+ (1,0) [0|253] "" Vector__XXX
 SG_ ATC_ASRInformationSignal : 46|2@1+ (1,0) [0|3] "" Vector__XXX
 SG_ ABS_EBSAmberWarningSignal : 44|2@1+ (1,0) [0|3] "" Vector__XXX
 SG_ EBSRedWarningSignal : 42|2@1+ (1,0) [0|3] "" Vector__XXX
 SG_ ABSFullyOperational : 40|2@1+ (1,0) [0|3] "" Vector__XXX
 SG_ EngRetarderSelection : 32|8@1+ (0.4,0) [0|100] "%" Vector__XXX
 SG_ RemoteAccelEnableSwitch : 30|2@1+ (1,0) [0|3] "" Vector__XXX
 SG_ EngAuxShutdownSwitch : 28|2@1+ (1,0) [0|3] "" Vector__XXX
 SG_ EngDerateSwitch : 26|2@1+ (1,0) [0|3] "" Vector__XXX
 SG_ AccelInterlockSwitch : 24|2@1+ (1,0) [0|3] "" Vector__XXX
 SG_ TractionCtrlOverrideSwitch : 22|2@1+ (1,0) [0|3] "" Vector__XXX
 SG_ ASRHillHolderSwitch : 20|2@1+ (1,0) [0|3] "" Vector__XXX
 SG_ ASROffroadSwitch : 18|2@1+ (1,0) [0|3] "" Vector__XXX
 SG_ ABSOffroadSwitch : 16|2@1+ (1,0) [0|3] "" Vector__XXX
 SG_ BrakePedalPos : 8|8@1+ (0.4,0) [0|100] "%" Vector__XXX
 SG_ EBSBrakeSwitch : 6|2@1+ (1,0) [0|3] "" Vector__XXX
 SG_ AntiLockBrakingActive : 4|2@1+ (1,0) [0|3] "" Vector__XXX
 SG_ ASRBrakeCtrlActive : 2|2@1+ (1,0) [0|3] "" Vector__XXX
 SG_ ASREngCtrlActive : 0|2@1+ (1,0) [0|3] "" Vector__XXX

BO_ 2565867262 EAC1: 8 Vector__XXX
 SG_ DiffLockStRearAxle3 : 22|2@1+ (1,0) [0|3] "" Vector__XXX
 SG_ RearAxleGroupEngagementStatus : 26|2@1+ (1,0) [0|3] "" Vector__XXX
 SG_ FrontAxleGroupEngagementStatus : 24|2@1+ (1,0) [0|3] "" Vector__XXX
 SG_ DiffLockStateCentralRear : 20|2@1+ (1,0) [0|3] "" Vector__XXX
 SG_ DiffLockStateCentralFront : 18|2@1+ (1,0) [0|3] "" Vector__XXX
 SG_ DiffLockStateCentral : 16|2@1+ (1,0) [0|3] "" Vector__XXX
 SG_ DiffLockStateRearAxle2 : 14|2@1+ (1,0) [0|3] "" Vector__XXX
 SG_ DiffLockStateRearAxle1 : 12|2@1+ (1,0) [0|3] "" Vector__XXX
 SG_ DiffLockStateFrontAxle2 : 10|2@1+ (1,0) [0|3] "" Vector__XXX
 SG_ DiffLockStateFrontAxle1 : 8|2@1+ (1,0) [0|3] "" Vector__XXX
 SG_ Location : 0|8@1+ (1,0) [0|255] "" Vector__XXX

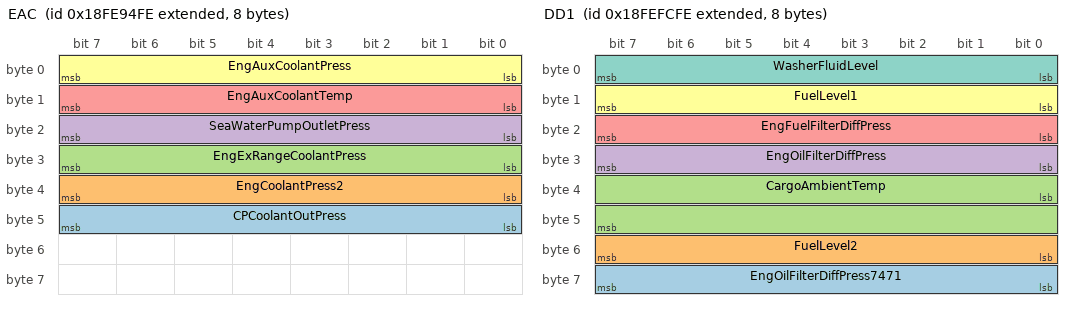
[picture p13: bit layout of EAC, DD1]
BO_ 2566821118 EAC: 8 Vector__XXX
 SG_ CPCoolantOutPress : 40|8@1+ (2,0) [0|500] "kPa" Vector__XXX
 SG_ EngCoolantPress2 : 32|8@1+ (4,0) [0|1000] "kPa" Vector__XXX
 SG_ EngExRangeCoolantPress : 24|8@1+ (4,0) [0|1000] "kPa" Vector__XXX
 SG_ SeaWaterPumpOutletPress : 16|8@1+ (2,0) [0|500] "kPa" Vector__XXX
 SG_ EngAuxCoolantTemp : 8|8@1+ (1,-40) [-40|210] "캜" Vector__XXX
 SG_ EngAuxCoolantPress : 0|8@1+ (4,0) [0|1000] "kPa" Vector__XXX

BO_ 2566810622 DI: 8 Vector__XXX
 SG_ Driver2Identification : 8|8@1+ (1,0) [0|255] "" Vector__XXX
 SG_ Driver1Identification : 0|8@1+ (1,0) [0|255] "" Vector__XXX

BO_ 2566847742 DD1: 8 Vector__XXX
 SG_ EngOilFilterDiffPress7471 : 56|8@1+ (5,0) [0|1250] "kPa" Vector__XXX
 SG_ FuelLevel2 : 48|8@1+ (0.4,0) [0|100] "%" Vector__XXX
 SG_ CargoAmbientTemp : 32|16@1+ (0.03125,-273) [-273|1734.96875] "캜" Vector__XXX
 SG_ EngOilFilterDiffPress : 24|8@1+ (0.5,0) [0|125] "kPa" Vector__XXX
 SG_ EngFuelFilterDiffPress : 16|8@1+ (2,0) [0|500] "kPa" Vector__XXX
 SG_ FuelLevel1 : 8|8@1+ (0.4,0) [0|100] "%" Vector__XXX
 SG_ WasherFluidLevel : 0|8@1+ (0.4,0) [0|100] "%" Vector__XXX

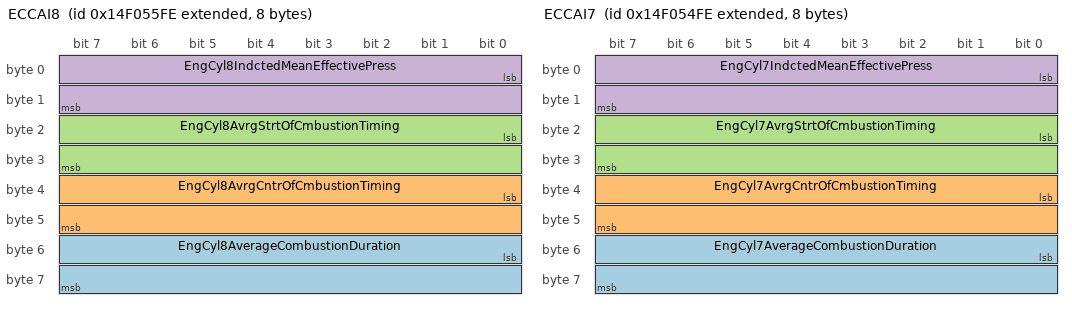
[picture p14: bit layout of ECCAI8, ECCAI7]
BO_ 2498778622 ECCAI8: 8 Vector__XXX
 SG_ EngCyl8AverageCombustionDuration : 48|16@1+ (0.0078125,0) [0|501.99] "deg" Vector__XXX
 SG_ EngCyl8AvrgCntrOfCmbustionTiming : 32|16@1+ (0.0078125,-250) [-250|250.992] "deg" Vector__XXX
 SG_ EngCyl8AvrgStrtOfCmbustionTiming : 16|16@1+ (0.0078125,-250) [-250|250.992] "deg" Vector__XXX
 SG_ EngCyl8IndctedMeanEffectivePress : 0|16@1+ (0.0001220703125,-1) [-1|6.84362793] "MPa" Vector__XXX

BO_ 2498778366 ECCAI7: 8 Vector__XXX
 SG_ EngCyl7AverageCombustionDuration : 48|16@1+ (0.0078125,0) [0|501.99] "deg" Vector__XXX
 SG_ EngCyl7AvrgCntrOfCmbustionTiming : 32|16@1+ (0.0078125,-250) [-250|250.992] "deg" Vector__XXX
 SG_ EngCyl7AvrgStrtOfCmbustionTiming : 16|16@1+ (0.0078125,-250) [-250|250.992] "deg" Vector__XXX
 SG_ EngCyl7IndctedMeanEffectivePress : 0|16@1+ (0.0001220703125,-1) [-1|6.84362793] "MPa" Vector__XXX

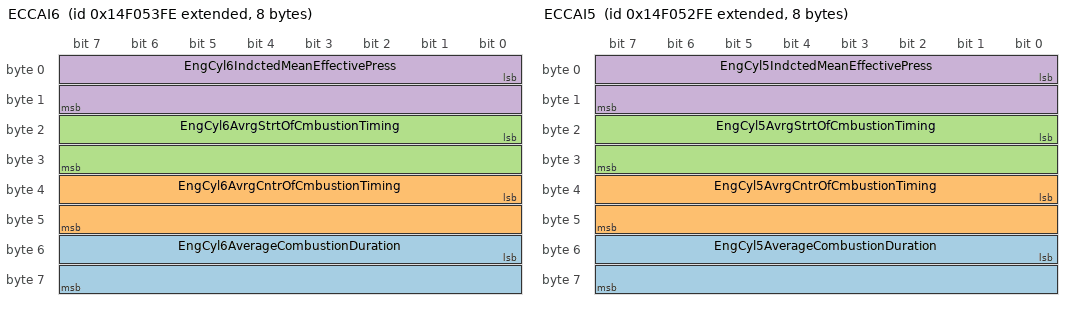
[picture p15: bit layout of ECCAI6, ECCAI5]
BO_ 2498778110 ECCAI6: 8 Vector__XXX
 SG_ EngCyl6AverageCombustionDuration : 48|16@1+ (0.0078125,0) [0|501.99] "deg" Vector__XXX
 SG_ EngCyl6AvrgCntrOfCmbustionTiming : 32|16@1+ (0.0078125,-250) [-250|250.992] "deg" Vector__XXX
 SG_ EngCyl6AvrgStrtOfCmbustionTiming : 16|16@1+ (0.0078125,-250) [-250|250.992] "deg" Vector__XXX
 SG_ EngCyl6IndctedMeanEffectivePress : 0|16@1+ (0.0001220703125,-1) [-1|6.84362793] "MPa" Vector__XXX

BO_ 2498777854 ECCAI5: 8 Vector__XXX
 SG_ EngCyl5AverageCombustionDuration : 48|16@1+ (0.0078125,0) [0|501.99] "deg" Vector__XXX
 SG_ EngCyl5AvrgCntrOfCmbustionTiming : 32|16@1+ (0.0078125,-250) [-250|250.992] "deg" Vector__XXX
 SG_ EngCyl5AvrgStrtOfCmbustionTiming : 16|16@1+ (0.0078125,-250) [-250|250.992] "deg" Vector__XXX
 SG_ EngCyl5IndctedMeanEffectivePress : 0|16@1+ (0.0001220703125,-1) [-1|6.84362793] "MPa" Vector__XXX

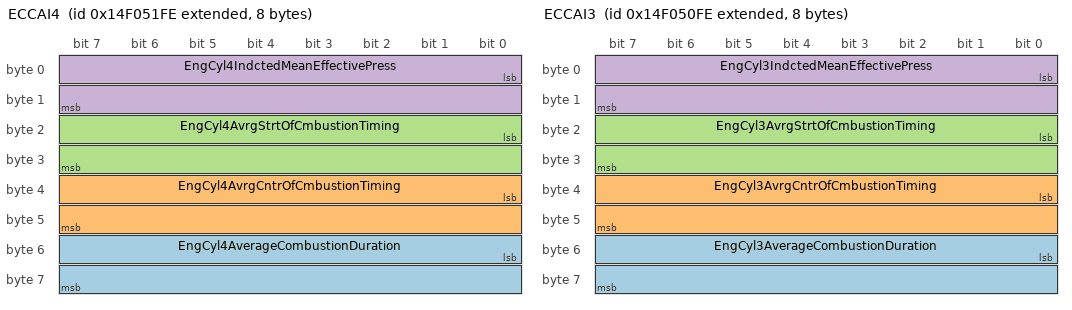
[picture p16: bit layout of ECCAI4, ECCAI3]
BO_ 2498777598 ECCAI4: 8 Vector__XXX
 SG_ EngCyl4AverageCombustionDuration : 48|16@1+ (0.0078125,0) [0|501.99] "deg" Vector__XXX
 SG_ EngCyl4AvrgCntrOfCmbustionTiming : 32|16@1+ (0.0078125,-250) [-250|250.992] "deg" Vector__XXX
 SG_ EngCyl4AvrgStrtOfCmbustionTiming : 16|16@1+ (0.0078125,-250) [-250|250.992] "deg" Vector__XXX
 SG_ EngCyl4IndctedMeanEffectivePress : 0|16@1+ (0.0001220703125,-1) [-1|6.84362793] "MPa" Vector__XXX

BO_ 2498777342 ECCAI3: 8 Vector__XXX
 SG_ EngCyl3AverageCombustionDuration : 48|16@1+ (0.0078125,0) [0|501.99] "deg" Vector__XXX
 SG_ EngCyl3AvrgCntrOfCmbustionTiming : 32|16@1+ (0.0078125,-250) [-250|250.992] "deg" Vector__XXX
 SG_ EngCyl3AvrgStrtOfCmbustionTiming : 16|16@1+ (0.0078125,-250) [-250|250.992] "deg" Vector__XXX
 SG_ EngCyl3IndctedMeanEffectivePress : 0|16@1+ (0.0001220703125,-1) [-1|6.84362793] "MPa" Vector__XXX

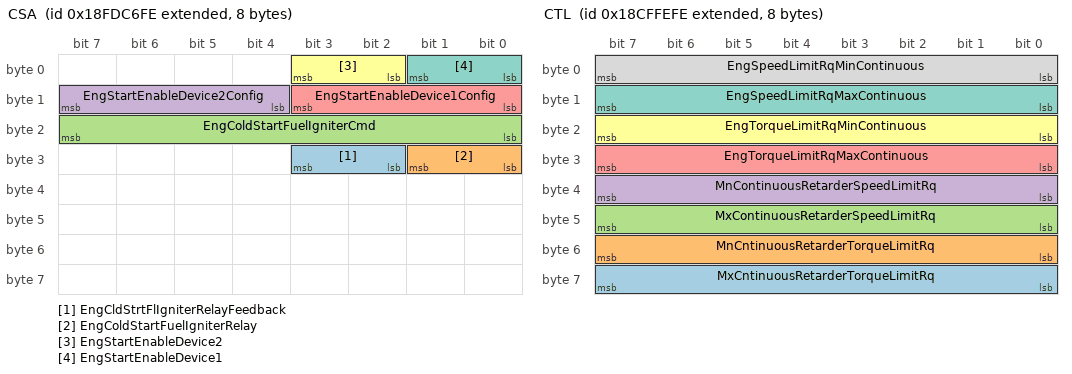
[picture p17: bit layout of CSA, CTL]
BO_ 2566768382 CSA: 8 Vector__XXX
 SG_ EngCldStrtFlIgniterRelayFeedback : 26|2@1+ (1,0) [0|3] "" Vector__XXX
 SG_ EngColdStartFuelIgniterRelay : 24|2@1+ (1,0) [0|3] "" Vector__XXX
 SG_ EngColdStartFuelIgniterCmd : 16|8@1+ (0.4,0) [0|100] "%" Vector__XXX
 SG_ EngStartEnableDevice2Config : 12|4@1+ (1,0) [0|15] "" Vector__XXX
 SG_ EngStartEnableDevice1Config : 8|4@1+ (1,0) [0|15] "" Vector__XXX
 SG_ EngStartEnableDevice2 : 2|2@1+ (1,0) [0|3] "" Vector__XXX
 SG_ EngStartEnableDevice1 : 0|2@1+ (1,0) [0|3] "" Vector__XXX

BO_ 2566811902 CVW: 8 Vector__XXX
 SG_ PoweredVehicleWeight : 0|16@1+ (10,0) [0|642550] "kg" Vector__XXX
 SG_ GrossCombinationVehicleWeight : 16|16@1+ (10,0) [0|642550] "kg" Vector__XXX

BO_ 2563768062 CTL: 8 Vector__XXX
 SG_ MxCntinuousRetarderTorqueLimitRq : 56|8@1+ (1,-125) [-125|0] "%" Vector__XXX
 SG_ MnCntinuousRetarderTorqueLimitRq : 48|8@1+ (1,-125) [-125|0] "%" Vector__XXX
 SG_ MxContinuousRetarderSpeedLimitRq : 40|8@1+ (32,0) [0|8000] "rpm" Vector__XXX
 SG_ MnContinuousRetarderSpeedLimitRq : 32|8@1+ (32,0) [0|8000] "rpm" Vector__XXX
 SG_ EngTorqueLimitRqMaxContinuous : 24|8@1+ (1,-125) [0|125] "%" Vector__XXX
 SG_ EngTorqueLimitRqMinContinuous : 16|8@1+ (1,-125) [0|125] "%" Vector__XXX
 SG_ EngSpeedLimitRqMaxContinuous : 8|8@1+ (32,0) [0|8000] "rpm" Vector__XXX
 SG_ EngSpeedLimitRqMinContinuous : 0|8@1+ (32,0) [0|8000] "rpm" Vector__XXX

BO_ 2633924862 CT6: 8 Vector__XXX
 SG_ EngAverageCombustionTime : 16|16@1+ (0.01,0) [0|642.55] "ms" Vector__XXX
 SG_ EngDesiredCombustionTime : 0|16@1+ (0.01,0) [0|642.55] "ms" Vector__XXX

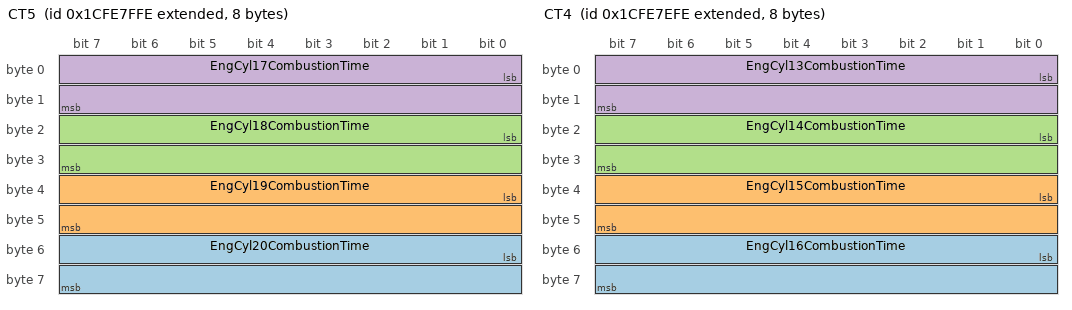
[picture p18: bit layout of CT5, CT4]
BO_ 2633924606 CT5: 8 Vector__XXX
 SG_ EngCyl20CombustionTime : 48|16@1+ (0.01,0) [0|642.55] "ms" Vector__XXX
 SG_ EngCyl19CombustionTime : 32|16@1+ (0.01,0) [0|642.55] "ms" Vector__XXX
 SG_ EngCyl18CombustionTime : 16|16@1+ (0.01,0) [0|642.55] "ms" Vector__XXX
 SG_ EngCyl17CombustionTime : 0|16@1+ (0.01,0) [0|642.55] "ms" Vector__XXX

BO_ 2633924350 CT4: 8 Vector__XXX
 SG_ EngCyl16CombustionTime : 48|16@1+ (0.01,0) [0|642.55] "ms" Vector__XXX
 SG_ EngCyl15CombustionTime : 32|16@1+ (0.01,0) [0|642.55] "ms" Vector__XXX
 SG_ EngCyl14CombustionTime : 16|16@1+ (0.01,0) [0|642.55] "ms" Vector__XXX
 SG_ EngCyl13CombustionTime : 0|16@1+ (0.01,0) [0|642.55] "ms" Vector__XXX

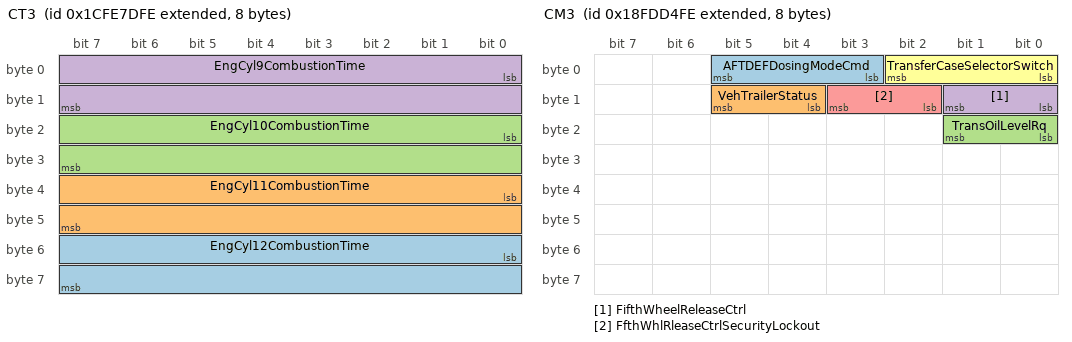
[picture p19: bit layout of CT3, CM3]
BO_ 2633924094 CT3: 8 Vector__XXX
 SG_ EngCyl12CombustionTime : 48|16@1+ (0.01,0) [0|642.55] "ms" Vector__XXX
 SG_ EngCyl11CombustionTime : 32|16@1+ (0.01,0) [0|642.55] "ms" Vector__XXX
 SG_ EngCyl10CombustionTime : 16|16@1+ (0.01,0) [0|642.55] "ms" Vector__XXX
 SG_ EngCyl9CombustionTime : 0|16@1+ (0.01,0) [0|642.55] "ms" Vector__XXX

BO_ 2633923838 CT2: 8 Vector__XXX
 SG_ EngCyl8CombustionTime : 48|16@1+ (0.01,0) [0|642.55] "ms" Vector__XXX
 SG_ EngCyl7CombustionTime : 32|16@1+ (0.01,0) [0|642.55] "ms" Vector__XXX
 SG_ EngCyl6CombustionTime : 16|16@1+ (0.01,0) [0|642.55] "ms" Vector__XXX
 SG_ EngCyl5CombustionTime : 0|16@1+ (0.01,0) [0|642.55] "ms" Vector__XXX

BO_ 2633923582 CT1: 8 Vector__XXX
 SG_ EngCyl4CombustionTime : 48|16@1+ (0.01,0) [0|642.55] "ms" Vector__XXX
 SG_ EngCyl3CombustionTime : 32|16@1+ (0.01,0) [0|642.55] "ms" Vector__XXX
 SG_ EngCyl2CombustionTime : 16|16@1+ (0.01,0) [0|642.55] "ms" Vector__XXX
 SG_ EngCyl1CombustionTime : 0|16@1+ (0.01,0) [0|642.55] "ms" Vector__XXX

BO_ 2633878014 CMI: 8 Vector__XXX
 SG_ TotalCountOfConfigChangesMade : 0|16@1+ (1,0) [0|64255] "" Vector__XXX

BO_ 2566771966 CM3: 8 Vector__XXX
 SG_ AFTDEFDosingModeCmd : 3|3@1+ (1,0) [0|7] "" Vector__XXX
 SG_ VehTrailerStatus : 12|2@1+ (1,0) [0|3] "" Vector__XXX
 SG_ TransOilLevelRq : 16|2@1+ (1,0) [0|3] "" Vector__XXX
 SG_ FifthWheelReleaseCtrl : 8|2@1+ (1,0) [0|3] "" Vector__XXX
 SG_ FfthWhlRleaseCtrlSecurityLockout : 10|2@1+ (1,0) [0|3] "" Vector__XXX
 SG_ TransferCaseSelectorSwitch : 0|3@1+ (1,0) [0|7] "" Vector__XXX

CM_ BO_ 2565868542 "Electronic Steering Control
PGN which indicates the actual angle and the status of a steerable axle";
CM_ SG_ 2565868542 TypeOfSteerTrans "Type of Steering Transmission (Ref. ECE Regulation 79 paragraph 2.6)
0000             Purely mechanical steering transmission
0001             Purely hydraulic steering transmission
0010             Purely electric steering transmission
0011 ...";
CM_ SG_ 2565868542 TypeOfSteerForces "Type of Steering Forces (Ref. ECE Regulation 79 paragraph 2.5)
0000             Manual steering equipment
0001             Power assisted steering equipment
0010             Full power steering equipment
0011             Self tracking steering ...";
CM_ SG_ 2565868542 SteerType "Indicates the different types of steering systems (ref. ECE Regulation 79 paragraph 2.5)
0000             Main steering system
0001             Auxiliary steering equipment
0010-1110   Reserved for Assignment by SAE
1111             Not ...";
CM_ SG_ 2565868542 SteerableLiftAxleLoweringInhibit "A signal which indicates if lowering of lifted axle is allowed or inhibited.

00      Lowering allowed
01      Lowering inhibited
10      Reserved
11      Not available";
CM_ SG_ 2565868542 StatusOfSteerAxle "A signal which indicates different states of the steering axle
0000               Axle steering not active (adhesion steering)
0001               Axle steering active
0010               Axle centered
0011               Axle centered, because of ...";
CM_ SG_ 2565868542 AxleLocation "To identify to which of several similar devices (such as tires or fuel tanks) the information applies.
The low order 4 bits represent a position number, counting left to right when facing in the direction of normal vehicle travel (forward).
The ...";
CM_ SG_ 2565868542 ActualInnerWheelSteerAngle "Signal which indicates the actual inner wheel steering angle.  The steering angle is the angle of wheel turn relative to the vehicle x-axis (yaw angle of inner wheel). See Figure SPN2927_A for explanation of positive and negative angles.  This ...";
CM_ BO_ 2633941758 "Electronic Retarder Controller 2
This message will be transmitted by several types of retarding devices such as engine compression release brakes, exhaust system restriction brakes, and driveline retarders using hydraulic, electric, or mechanical ...";
CM_ SG_ 2633941758 CrsCtrlRetarderActiveSpeedOffset "The additional speed above the operator selected cruise control set speed at which the retarder will activate when cruise control is active.";
CM_ SG_ 2633941758 TransOutputRetarder "Identifies the status of the transmission output retarder.

00 - Off
01 - On
10 - Error
11 - Not available";
CM_ BO_ 2565865726 "Electronic Retarder Controller 1
NOTE- This message will be transmitted by several types of retarding devices such as engine compression release brakes, exhaust system restriction brakes, and driveline retarders using hydraulic, electric, or ...";
CM_ SG_ 2565865726 ActlMxAvlblRetarderPercentTorque "This is the maximum amount of torque that the retarder can immediately deliver.   It is the same as the maximum torque shown in the Retarder뭩 Configuration message, but allows for a much faster rate of change than could be communicated by reissuing ...";
CM_ SG_ 2565865726 RetarderSelectionNonengine "The 밨etarder Selection, non-engine� is the position of the driver뭩 selector for retarders that are not part of the engine system, expressed as percent and determined by the ratio of current position to the maximum possible position. The physical ...";
CM_ SG_ 2565865726 DrvrsDemandRetarderPercentTorque "The Drivers demand retarder - percent torque is the maximum torque selected by the driver when one or more modes  are selected by the driver, such as hand lever, switch, constant torque, constant velocity, etc.";
CM_ SG_ 2565865726 SrcAddrssOfCntrllngDvcFrRtrdrCtr "The source address of the SAE J1939 device currently controlling the retarder.  It is used to expand the torque mode parameter (see SPN 899) in cases where control is in response to an ECU that is not listed in Table SPN899_A.  Its value may be the ...";
CM_ SG_ 2565865726 RetarderRoadSpeedExceededStatus "Retarder Road Speed Exceeded Status:

00   Road speed is below threshold 
01   Road speed is above threshold and retarder is allowed to be activated
10   Reserved
11   Don't care/Take no action";
CM_ SG_ 2565865726 RetarderRoadSpeedLimitSwitch "Retarder road speed limit switch states:
00   Road speed limiting by retarder is disabled
01   Road speed limiting by retarder is enabled. When the speed limit is not set by a network device, the road speed that the retarder will limit to may be ...";
CM_ SG_ 2565865726 RetarderRequestingBrakeLight "Indicates that whether the retarder is requesting that the brake lights are illuminated.
00 - Retarder is not requesting that the brake lights are illuminated
01 - Retarder is requesting that the brake lights are illuminated
10 - Reserved
11 - ...";
CM_ SG_ 2565865726 EngCoolantLoadIncrease "Status of an event, external to the engine, that may increase the nominal temperature of the engine coolant liquid.

00 - No coolant load increase
01 - Coolant load increase possible
10 - Error
11 - Not available";
CM_ SG_ 2565865726 IntendedRetarderPercentTorque "Braking torque of retarder that the retarder is currently trying to achieve.  This value takes into account all static limitations, but not the limitations due to the dynamic behavior of the retarder.  This value, if unchanged over a certain time, ...";
CM_ SG_ 2565865726 ActualRetarderPercentTorque "Actual braking torque of the retarder as a percent of retarder configuration reference torque SPN 556.

Note:  Refer to section 5.2.1 in SAE J1939-71.";
CM_ SG_ 2565865726 RetarderEnableShiftAssistSwitch "Switch signal which indicates whether the operator wishes the retarder to be enabled for transmission shift assist.  The retarder does not check this switch, nor does the enabling of this switch engage the retarder.  When this switch is 밻nabled,� ...";
CM_ SG_ 2565865726 RetarderEnableBrakeAssistSwitch "Switch signal which indicates whether the operator wishes the retarder to be enabled for vehicle braking assist. The retarder does not check this switch, nor does the enabling of this switch engage the retarder. When this switch is 밻nabled,� the ...";
CM_ SG_ 2565865726 RetarderTorqueMode "State signal which indicates which retarder torque mode is currently generating, limiting, or controlling the torque.  Note that the modes are not in prioritized order. Not all modes may be relevant for a given device.  Some devices may not ...";
CM_ BO_ 2633932798 "Exhaust Port Temperature 5";
CM_ SG_ 2633932798 EngExhaustGasPort20Temp "Temperature at the cylinder exhaust port of the engine.";
CM_ SG_ 2633932798 EngExhaustGasPort19Temp "Temperature at the cylinder exhaust port of the engine.";
CM_ SG_ 2633932798 EngExhaustGasPort18Temp "Temperature at the cylinder exhaust port of the engine.";
CM_ SG_ 2633932798 EngExhaustGasPort17Temp "Temperature at the cylinder exhaust port of the engine.";
CM_ BO_ 2566824190 "Exhaust Port Temperature 4";
CM_ SG_ 2566824190 EngExhaustGasPort16Temp "Temperature at the cylinder exhaust port of the engine.";
CM_ SG_ 2566824190 EngExhaustGasPort15Temp "Temperature at the cylinder exhaust port of the engine.";
CM_ SG_ 2566824190 EngExhaustGasPort14Temp "Temperature at the cylinder exhaust port of the engine.";
CM_ SG_ 2566824190 EngExhaustGasPort13Temp "Temperature at the cylinder exhaust port of the engine.";
CM_ BO_ 2633933310 "Exhaust Port Temperature 3";
CM_ SG_ 2633933310 EngExhaustGasPort12Temp "Temperature at the cylinder exhaust port of the engine.";
CM_ SG_ 2633933310 EngExhaustGasPort11Temp "Temperature at the cylinder exhaust port of the engine.";
CM_ SG_ 2633933310 EngExhaustGasPort10Temp "Temperature at the cylinder exhaust port of the engine.";
CM_ SG_ 2633933310 EngExhaustGasPort9Temp "Temperature at the cylinder exhaust port of the engine.";
CM_ BO_ 2633933566 "Exhaust Port Temperature 2";
CM_ SG_ 2633933566 EngExhaustGasPort8Temp "Temperature at the cylinder exhaust port of the engine.";
CM_ SG_ 2633933566 EngExhaustGasPort7Temp "Temperature at the cylinder exhaust port of the engine.";
CM_ SG_ 2633933566 EngExhaustGasPort6Temp "Temperature at the cylinder exhaust port of the engine.";
CM_ SG_ 2633933566 EngExhaustGasPort5Temp "Temperature at the cylinder exhaust port of the engine.";
CM_ BO_ 2633933822 "Exhaust Port Temperature 1";
CM_ SG_ 2633933822 EngExhaustGasPort4Temp "Temperature at the cylinder exhaust port of the engine.";
CM_ SG_ 2633933822 EngExhaustGasPort3Temp "Temperature at the cylinder exhaust port of the engine.";
CM_ SG_ 2633933822 EngExhaustGasPort2Temp "Temperature at the cylinder exhaust port of the engine.";
CM_ SG_ 2633933822 EngExhaustGasPort1Temp "Temperature at the cylinder exhaust port of the engine.";
CM_ BO_ 2566776062 "Equipment Performance Data
Parameters related to the performance characteristics of equipment";
CM_ SG_ 2566776062 PayloadCapacityPercentage "The current equipment payload plus the weight of any after-factory modifications reported as a percentage of the equipment's maximum payload capacity. The equipment's maximum payload capacity is the maximum capacity of the equipment before the added ...";
CM_ SG_ 2566776062 PayloadCarryBackWeight "The payload weight left on the machine after the last payload dump event.";
CM_ SG_ 2566776062 PayloadWeightConfidence "The level of confidence of the real time payload weight measurement (SPN 6851). Higher confidence values indicate greater probability the real time payload weight is the actual weight and providing feedback on the potential for improving system ...";
CM_ SG_ 2566776062 PayloadWeight "The current payload weight carried by the machine.";
CM_ SG_ 2566776062 PayloadPercentage "The current payload of the equipment, reported as a percentage of the equipment's rated payload limit.";
CM_ BO_ 2566771454 "ECU Performance
Message used to transfer ECU performance parameters.";
CM_ SG_ 2566771454 DataMemoryUsage "The used storage capacity of the data buffer memory internal to an ECU, such as a data logger.";
CM_ SG_ 2566771454 KeepAliveBatteryConsumption "The capacity consumed from the direct battery connection since the key was last turned off.  This value is maintained and does not accumulate while the key switch is on.  The value is reset to 0 when the key switch is turned to the off position.";
CM_ BO_ 2566775806 "Equipment Operation and Control
Parameters related to the operation and controls for equipment";
CM_ SG_ 2566775806 TravelVelocityCtrlPos "The position of the travel velocity control component reported as a percentage of the control's full displacement in each direction respectively.  Positive position values indicate forward travel direction;  negative position values indicate ...";
CM_ BO_ 2633935358 "Exhaust Oxygen 1";
CM_ SG_ 2633935358 EngExhstGsOxygnSnsrClsdLpOprtion "Indicates whether the engine is using the exhaust oxygen sensor to control the air/fuel ratio.
00 Engine not using the exhaust oxygen sensor (open loop)
01 Engine using the exhaust oxygen sensor for a closed loop operation
10 Reserved
11 Don't ...";
CM_ SG_ 2633935358 EngExhstGsOxygnSnsrFlngCrrection "The amount of fueling change required by the system based on the measured exhaust oxygen value compared to the maximum fueling change permitted by the system, expressed as percentages.";
CM_ SG_ 2633935358 EngActualExhaustOxygen "The actual amount of oxygen in the exhaust represented as a percentage by volume with respect to the total volume of exhaust gases leaving the engine.";
CM_ SG_ 2633935358 EngDesiredExhaustOxygen "The desired amount of oxygen in the exhaust represented as a percentage by volume with respect to the total volume of exhaust gases leaving the engine.";
CM_ SG_ 2633935358 EngDesiredRatedExhaustOxygen "The desired amount of oxygen in the exhaust at rated conditions represented as a percentage by volume with respect to the total volume of exhaust gases leaving the engine.";
CM_ BO_ 2365447166 "Extended Joystick Message 3
Used to transfer information about the measured status of three additional axes of a joystick and switches of the joystick grip or handle.  The joystick axial motion information is available in the Basic Joystick ...";
CM_ SG_ 2365447166 Joystick3Button13PressedStatus "Reports when the joystick button has been pressed.

00 Button not pressed
01 Button pressed
10 Error Indicator
11 Not Available";
CM_ SG_ 2365447166 Joystick3Button14PressedStatus "Reports when the joystick button has been pressed.

00 Button not pressed
01 Button pressed
10 Error Indicator
11 Not Available";
CM_ SG_ 2365447166 Joystick3Button15PressedStatus "Reports when the joystick button has been pressed.

00 Button not pressed
01 Button pressed
10 Error Indicator
11 Not Available";
CM_ SG_ 2365447166 Joystick3Button16PressedStatus "Reports when the joystick button has been pressed.

00 Button not pressed
01 Button pressed
10 Error Indicator
11 Not Available";
CM_ SG_ 2365447166 Jystick3GripXAxisDetentPosStatus "Reports when the current joystick grip position is in the detent position for that axis of travel.

00 Not in the Detent Position
01 In the Detent Position
10 Error Indicator
11 Not Available";
CM_ SG_ 2365447166 Jystick3GripYAxisDetentPosStatus "Reports when the current joystick grip position is in the detent position for that axis of travel.

00 Not in the Detent Position
01 In the Detent Position
10 Error Indicator
11 Not Available";
CM_ SG_ 2365447166 Jystick3ThetaAxisDetentPosStatus "Reports when the current joystick position is in the detent position for that axis of travel.

00 Not in the Detent Position
01 In the Detent Position
10 Error Indicator
11 Not Available";
CM_ SG_ 2365447166 Joystick3ThetaAxisPos "The position of the joystick in the relative motion of travel from the neutral position.  Position value of 0 is Neutral and position value 1000 (100%) is the end of linear zone.  Value of 1022 indicates an error has occurred.";
CM_ SG_ 2365447166 Jystck3ThtAxsClckwsPstvPosStatus "Reports when the current joystick position is on the positive travel side (forward, right, clockwise, up) relative to the neutral position for that axis of travel.
00 Not on Positive side of Neutral
01 On positive side of Neutral
10 Error ...";
CM_ SG_ 2365447166 Jystck3ThetaAxisNeutralPosStatus "Reports when the current joystick position is in the neutral position for that axis of travel.  The neutral position measurement must be determined from some mechanism other than the axis position measurement device.
00 Not in Neutral Position
01 ...";
CM_ SG_ 2365447166 Joystick3GripYAxisPos "The position of the joystick grip in the relative motion of travel from the neutral position.  Position value of 0 is Neutral and position value 1000 (100%) is the end of linear zone.  Value of 1022 indicates an error has occurred.";
CM_ SG_ 2365447166 Jystck3GrpYAxsLvrFrwrdPstvPsStts "Reports when the current joystick grip position is on the positive travel side (forward, right, clockwise, up) relative to the neutral position for that axis of travel.
00 Not on Positive side of Neutral
01 On positive side of Neutral
10 Error ...";
CM_ SG_ 2365447166 Jystck3GrpYAxsLvrBckNgtvPsStatus "Reports when the current joystick grip position is on the negative travel side (back, left, counterclockwise, down) relative to the neutral position for that axis of travel.
00 Not on negative side of Neutral
01 On negative side of Neutral
10 ...";
CM_ SG_ 2365447166 Jystck3GripYAxisNeutralPosStatus "Reports when the current joystick grip position is in the neutral position for that axis of travel.  The neutral position measurement must be determined from some mechanism other than the axis position measurement device.
00 Not in Neutral Position
 ...";
CM_ SG_ 2365447166 Joystick3GripXAxisPos "The position of the joystick grip in the relative motion of travel from the neutral position.  Position value of 0 is Neutral and position value 1000 (100%) is the end of linear zone.  Value of 1022 indicates an error has occurred.";
CM_ SG_ 2365447166 Jystck3GrpXAxsLvrRghtPstvPsSttus "Reports when the current joystick grip position is on the positive travel side (forward, right, clockwise, up) relative to the neutral position for that axis of travel.
00 Not on Positive side of Neutral
01 On positive side of Neutral
10 Error ...";
CM_ SG_ 2365447166 Jystck3GrpXAxsLvrLftNgtvPsStatus "Reports when the current joystick grip position is on the negative travel side (back, left, counterclockwise, down) relative to the neutral position for that axis of travel.
00 Not on negative side of Neutral
01 On negative side of Neutral
10 ...";
CM_ SG_ 2365447166 Jystck3GripXAxisNeutralPosStatus "Reports when the current joystick grip position is in the neutral position for that axis of travel.  The neutral position measurement must be determined from some mechanism other than the axis position measurement device.
00 Not on negative side of ...";
CM_ SG_ 2365447166 Jystck3ThtAxsCntrClckwsNgtvPsStt "Reports when the current joystick position is on the negative travel side (back, left, counterclockwise, down) relative to the neutral position for that axis of travel.
00 Not on negative side of Neutral
01 On negative side of Neutral
10 Error ...";
CM_ BO_ 2365446654 "Extended Joystick Message 2
Used to transfer information about the measured status of three additional axes of a joystick and switches of the joystick grip or handle.  The joystick axial motion information is available in the Basic Joystick ...";
CM_ SG_ 2365446654 Joystick2Button13PressedStatus "Reports when the joystick button has been pressed.

00 Button not pressed
01 Button pressed
10 Error Indicator
11 Not Available";
CM_ SG_ 2365446654 Joystick2Button14PressedStatus "Reports when the joystick button has been pressed.

00 Button not pressed
01 Button pressed
10 Error Indicator
11 Not Available";
CM_ SG_ 2365446654 Joystick2Button15PressedStatus "Reports when the joystick button has been pressed.

00 Button not pressed
01 Button pressed
10 Error Indicator
11 Not Available";
CM_ SG_ 2365446654 Joystick2Button16PressedStatus "Reports when the joystick button has been pressed.

00 Button not pressed
01 Button pressed
10 Error Indicator
11 Not Available";
CM_ SG_ 2365446654 Jystick2GripXAxisDetentPosStatus "Reports when the current joystick grip position is in the detent position for that axis of travel.

00 Not in the Detent Position
01 In the Detent Position
10 Error Indicator
11 Not Available";
CM_ SG_ 2365446654 Jystick2GripYAxisDetentPosStatus "Reports when the current joystick grip position is in the detent position for that axis of travel.

00 Not in the Detent Position
01 In the Detent Position
10 Error Indicator
11 Not Available";
CM_ SG_ 2365446654 Jystick2ThetaAxisDetentPosStatus "Reports when the current joystick position is in the detent position for that axis of travel.

00 Not in the Detent Position
01 In the Detent Position
10 Error Indicator
11 Not Available";
CM_ SG_ 2365446654 Joystick2ThetaAxisPos "The position of the joystick in the relative motion of travel from the neutral position.  Position value of 0 is Neutral and position value 1000 (100%) is the end of linear zone.  Value of 1022 indicates an error has occurred.";
CM_ SG_ 2365446654 Jystck2ThtAxsClckwsPstvPosStatus "Reports when the current joystick position is on the positive travel side (forward, right, clockwise, up) relative to the neutral position for that axis of travel.
00 Not on Positive side of Neutral
01 On positive side of Neutral
10 Error ...";
CM_ SG_ 2365446654 Jystck2ThetaAxisNeutralPosStatus "Reports when the current joystick position is in the neutral position for that axis of travel.  The neutral position measurement must be determined from some mechanism other than the axis position measurement device.
00 Not in Neutral Position
01 ...";
CM_ SG_ 2365446654 Joystick2GripYAxisPos "The position of the joystick grip in the relative motion of travel from the neutral position.  Position value of 0 is Neutral and position value 1000 (100%) is the end of linear zone.  Value of 1022 indicates an error has occurred.";
CM_ SG_ 2365446654 Jystck2GrpYAxsLvrFrwrdPstvPsStts "Reports when the current joystick grip position is on the positive travel side (forward, right, clockwise, up) relative to the neutral position for that axis of travel.
00 Not on Positive side of Neutral
01 On positive side of Neutral
10 Error ...";
CM_ SG_ 2365446654 Jystck2GrpYAxsLvrBckNgtvPsStatus "Reports when the current joystick grip position is on the negative travel side (back, left, counterclockwise, down) relative to the neutral position for that axis of travel.
00 Not on negative side of Neutral
01 On negative side of Neutral
10 ...";
CM_ SG_ 2365446654 Jystck2GripYAxisNeutralPosStatus "Reports when the current joystick grip position is in the neutral position for that axis of travel.  The neutral position measurement must be determined from some mechanism other than the axis position measurement device.
00 Not in Neutral Position
 ...";
CM_ SG_ 2365446654 Joystick2GripXAxisPos "The position of the joystick grip in the relative motion of travel from the neutral position.  Position value of 0 is Neutral and position value 1000 (100%) is the end of linear zone.  Value of 1022 indicates an error has occurred.";
CM_ SG_ 2365446654 Jystck2GrpXAxsLvrRghtPstvPsSttus "Reports when the current joystick grip position is on the positive travel side (forward, right, clockwise, up) relative to the neutral position for that axis of travel.
00 Not on Positive side of Neutral
01 On positive side of Neutral
10 Error ...";
CM_ SG_ 2365446654 Jystck2GrpXAxsLvrLftNgtvPsStatus "Reports when the current joystick grip position is on the negative travel side (back, left, counterclockwise, down) relative to the neutral position for that axis of travel.
00 Not on negative side of Neutral
01 On negative side of Neutral
10 ...";
CM_ SG_ 2365446654 Jystck2GripXAxisNeutralPosStatus "Reports when the current joystick grip position is in the neutral position for that axis of travel.  The neutral position measurement must be determined from some mechanism other than the axis position measurement device.
00 Not on negative side of ...";
CM_ SG_ 2365446654 Jystck2ThtAxsCntrClckwsNgtvPsStt "Reports when the current joystick position is on the negative travel side (back, left, counterclockwise, down) relative to the neutral position for that axis of travel.
00 Not on negative side of Neutral
01 On negative side of Neutral
10 Error ...";
CM_ BO_ 2365446142 "Extended Joystick Message 1
Used to transfer information about the measured status of three additional axes of a joystick and switches of the joystick grip or handle.  The joystick axial motion information is available in the Basic Joystick ...";
CM_ SG_ 2365446142 Joystick1Button13PressedStatus "Reports when the joystick button has been pressed.

00 Button not pressed
01 Button pressed
10 Error Indicator
11 Not Available";
CM_ SG_ 2365446142 Joystick1Button14PressedStatus "Reports when the joystick button has been pressed.

00 Button not pressed
01 Button pressed
10 Error Indicator
11 Not Available";
CM_ SG_ 2365446142 Joystick1Button15PressedStatus "Reports when the joystick button has been pressed.

00 Button not pressed
01 Button pressed
10 Error Indicator
11 Not Available";
CM_ SG_ 2365446142 Joystick1Button16PressedStatus "Reports when the joystick button has been pressed.

00 Button not pressed
01 Button pressed
10 Error Indicator
11 Not Available";
CM_ SG_ 2365446142 Jystick1GripXAxisDetentPosStatus "Reports when the current joystick grip position is in the detent position for that axis of travel.

00 Not in the Detent Position
01 In the Detent Position
10 Error Indicator
11 Not Available";
CM_ SG_ 2365446142 Jystick1GripYAxisDetentPosStatus "Reports when the current joystick grip position is in the detent position for that axis of travel.

00 Not in the Detent Position
01 In the Detent Position
10 Error Indicator
11 Not Available";
CM_ SG_ 2365446142 Jystick1ThetaAxisDetentPosStatus "Reports when the current joystick position is in the detent position for that axis of travel.

00 Not in the Detent Position
01 In the Detent Position
10 Error Indicator
11 Not Available";
CM_ SG_ 2365446142 Joystick1ThetaAxisPos "The position of the joystick in the relative motion of travel from the neutral position.  Position value of 0 is Neutral and position value 1000 (100%) is the end of linear zone.  Value of 1022 indicates an error has occurred.";
CM_ SG_ 2365446142 Jystck1ThtAxsClckwsPstvPosStatus "Reports when the current joystick position is on the positive travel side (forward, right, clockwise, up) relative to the neutral position for that axis of travel.
00 Not on Positive side of Neutral
01 On positive side of Neutral
10 Error ...";
CM_ SG_ 2365446142 Jystck1ThetaAxisNeutralPosStatus "Reports when the current joystick position is in the neutral position for that axis of travel.  The neutral position measurement must be determined from some mechanism other than the axis position measurement device.
00 Not in Neutral Position
01 ...";
CM_ SG_ 2365446142 Joystick1GripYAxisPos "The position of the joystick grip in the relative motion of travel from the neutral position.  Position value of 0 is Neutral and position value 1000 (100%) is the end of linear zone.  Value of 1022 indicates an error has occurred.";
CM_ SG_ 2365446142 Jystck1GrpYAxsLvrFrwrdPstvPsStts "Reports when the current joystick grip position is on the positive travel side (forward, right, clockwise, up) relative to the neutral position for that axis of travel.
00 Not on Positive side of Neutral
01 On positive side of Neutral
10 Error ...";
CM_ SG_ 2365446142 Jystck1GrpYAxsLvrBckNgtvPsStatus "Reports when the current joystick grip position is on the negative travel side (back, left, counterclockwise, down) relative to the neutral position for that axis of travel.
00 Not on negative side of Neutral
01 On negative side of Neutral
10 ...";
CM_ SG_ 2365446142 Aftrtrtmnt1DslExhstFldPrprtsPrlm "Reports when the current joystick grip position is in the neutral position for that axis of travel.  The neutral position measurement must be determined from some mechanism other than the axis position measurement device.
00 Not in Neutral Position
 ...";
CM_ SG_ 2365446142 Joystick1GripXAxisPos "The position of the joystick grip in the relative motion of travel from the neutral position.  Position value of 0 is Neutral and position value 1000 (100%) is the end of linear zone.  Value of 1022 indicates an error has occurred.";
CM_ SG_ 2365446142 Jystck1GrpXAxsLvrRghtPstvPsSttus "Reports when the current joystick grip position is on the positive travel side (forward, right, clockwise, up) relative to the neutral position for that axis of travel.
00 Not on Positive side of Neutral
01 On positive side of Neutral
10 Error ...";
CM_ SG_ 2365446142 Jystck1GrpXAxsLvrLftNgtvPsStatus "Reports when the current joystick grip position is on the negative travel side (back, left, counterclockwise, down) relative to the neutral position for that axis of travel.
00 Not on negative side of Neutral
01 On negative side of Neutral
10 ...";
CM_ SG_ 2365446142 Jystck1GripXAxisNeutralPosStatus "Reports when the current joystick grip position is in the neutral position for that axis of travel.  The neutral position measurement must be determined from some mechanism other than the axis position measurement device.
00 Not in Neutral Position
 ...";
CM_ SG_ 2365446142 Jystck1ThtAxsCntrClckwsNgtvPsStt "Reports when the current joystick position is on the negative travel side (back, left, counterclockwise, down) relative to the neutral position for that axis of travel.
00 Not on negative side of Neutral
01 On negative side of Neutral
10 Error ...";
CM_ BO_ 2633929470 "Engine Information 1";
CM_ SG_ 2633929470 EngFuelRackPos "Measured position of the engine fuel rack.  A value of 0% rack represents no fueling and a value of 100% rack represents maximum fueling.";
CM_ SG_ 2633929470 EngGasMassFlowRate1 "Gas mass flow rate delivered to an engine through its first fuel control system.  See SPN 3467 for the second fuel control system.";
CM_ SG_ 2633929470 InstantaneousEstBrakePower "Estimate of the power developed by the engine.";
CM_ SG_ 2633929470 EngExhaustGasPress1 "Gage pressure of the exhaust gases as measured at the turbine intake of the turbocharger. This SPN to be used for inline engines or exhaust bank 1 of multiple bank engines.  See SPN 5749 for exhaust bank 2 and See SPN 6384 for alternate range and ...";
CM_ SG_ 2633929470 EngPrefilterOilPress "Gage pressure of the engine oil before the oil reaches the oil filter.   See SPN 7470 for alternate resolution.";
CM_ BO_ 2633937406 "ECU History";
CM_ SG_ 2633937406 TotalECURunTime "Total time accumulated over the life of the ECU, from ignition switch ON to ignition switch OFF.  When the ECU is replaced this value shall be reset.";
CM_ SG_ 2633937406 TotalECUDistance "Total distance accumulated over the life of the ECU.  When the ECU is replaced this value shall be reset.";
CM_ BO_ 2364541694 "Engine Gas Flow Rate
Flow rates of Air and mixed gasses into the engine cylinders.";
CM_ SG_ 2364541694 EngExhstGsRcrcltion2MassFlowRate "Flow rate of gas through the second EGR system. Flow rate of the exhaust gas being recirculated from the 2nd EGR system into combustion air.";
CM_ SG_ 2364541694 EngIntakeAirMassFlowRate "Mass flow rate of fresh air entering the engine air intake, before any EGR mixer, if used.  Flow rate of fresh air conducted to the engine cylinders to support combustion.";
CM_ SG_ 2364541694 EngExhstGsRcrcltion1MassFlowRate "Flow rate of gas through the EGR system. Flow rate of the exhaust gas being recirculated into the combustion air.";
CM_ BO_ 2566810366 "Engine Fuel/Lube Systems";
CM_ SG_ 2566810366 EngFuelSupplyPumpIntakePress "Gage pressure of fuel at the fuel supply pump intake.  See Figures SPN16_A & SPN16_B.

See also SPN 1381.";
CM_ SG_ 2566810366 FuelPumpPrimerStatus "Parameter used to transmit the actual status of the fuel priming system.  The fuel priming system is a system that purges air in the fuel lines and may assist fuel delivery to a second pump at lower speeds.
00 - Off
01 - On
10 - Error
11 - ...";
CM_ SG_ 2566810366 EngVentilationStatus "Engine ventilation control states.
000 = Sufficiently vented (all combustible gases have been evacuated from intake and exhaust systems)
001 = Ventilation needed (combustible gases may be present in intake and exhaust systems)
010 = Ventilation ...";
CM_ SG_ 2566810366 EngCoolantPreheatedState "Indicates whether the engine coolant is pre-heated sufficiently for starting purposes.
00 = Not sufficiently pre-heated
01 = Sufficiently pre-heated
10 = Unable to determine  engine coolant pre-heated sufficiently
11 = Not available or not ...";
CM_ SG_ 2566810366 EngOilPreHeatedState "Indicates whether the engine oil pre-heated sufficiently for starting purposes.

00 = Not sufficiently pre-heated
01 = Sufficiently pre-heated
10 = Unable to determine if engine oil is pre-heated sufficiently
11 = Not available or not installed";
CM_ SG_ 2566810366 EngOilPrimingState "Determination of whether or not the engine is (or has recently been) sufficiently lubricated for starting purposes.
00 = Not sufficiently lubricated
01 = Sufficiently lubricated
10 = Unable to determine if sufficiently lubricated
11 = Not ...";
CM_ SG_ 2566810366 EngOilPrimingPumpSwitch "Switch input for activating the engine oil priming pump.

00 = Off
01 = On
10 = Error
11 = Not available or not installed";
CM_ SG_ 2566810366 EngOilFilterOutletPress "Oil pressure (gage) measured just downstream of oil filter.Used in conjunction with SPN1208 (pre-filter oil pressure) to determine oil filter health.";
CM_ SG_ 2566810366 EngWasteOilReservoirLevel "Level of crankcase blowby emulsion collected by a container.  Normalized to percent, 0% represents completely empty and 100% represents completely full.";
CM_ SG_ 2566810366 EngFuelFilterDiffPress "Differential pressure measured across the fuel filter located between the fuel tank and the supply pump.  See Figures SPN16_A and SPN16_B.";
CM_ SG_ 2566810366 EngFuelSupplyPumpIntakeAbsPress "Absolute pressure of fuel at the fuel supply pump intake.  See Figures SPN16_A & SPN16_B.  See SPN 7472 for alternate resolution.";
CM_ SG_ 2566810366 EngOilLevelRemoteReservoir "Ratio of current volume of engine oil in a remote reservoir to the maximum required volume.  If a single switch (on/off) is used, 20% and 100% respectively will be used where 100% means no oil needs to be added and 20% means oil needs to be added ...";
CM_ BO_ 2566767102 "Engine Fluid Level/Pressure 3
3rd PGN which identifies parameters that are either measuring various pressures within the engine or identifying engine fluid levels";
CM_ SG_ 2566767102 EngThrottleValve1DiffPress "The differential pressure between the intake and outlet of the throttle valve 1 (SPN 51).  The differential pressure is measured from the intake with respect to the outlet of the throttle valve.";
CM_ SG_ 2566767102 EngExhstGsRcrclation1OutletPress "EGR outlet pressure is measured immediately after the EGR valve.";
CM_ SG_ 2566767102 EngExhstVlvActtionSystemOilPress "The absolute pressure of the oil in the hydraulic system that powers the engine exhaust valve actuation system";
CM_ SG_ 2566767102 EngExhstGsRcrclation1IntakePress "EGR intake gage pressure is measured after the EGR cooler and before the EGR valve.";
CM_ SG_ 2566767102 EngIntkVlvActationSystemOilPress "The gage pressure of the oil in the hydraulic system that powers the engine intake valve actuation system";
CM_ BO_ 2566839294 "Engine Fluid Level/Pressure 2
2nd PGN which identifies parameters that are either measuring various pressures within the engine or identifying engine fluid levels";
CM_ SG_ 2566839294 EngInjectorMeteringRail2Press "The gage pressure of fuel in the metering rail #2 as delivered from the supply pump to the injector metering intake.  See Figure SPN16_A for fuel system related parameters.  Although the figure does not show rail #2 it does show the relationship of ...";
CM_ SG_ 2566839294 EngInjectorTimingRail1Press "The gage pressure of fuel in the timing rail delivered from the supply pump to the injector timing intake.";
CM_ SG_ 2566839294 EngInjectorMeteringRail1Press "The gage pressure of fuel in the primary, or first, metering rail as delivered from the supply pump to the injector metering intake.";
CM_ SG_ 2566839294 EngInjectionCtrlPress "The gage pressure of the engine oil in the hydraulic accumulator that powers an intensifier used for fuel injection.";
CM_ BO_ 2566844414 "Engine Fluid Level/Pressure 1
PGN which identifies parameters that are either measuring various pressures within the engine or identifying engine fluid levels";
CM_ SG_ 2566844414 EngCoolantLevel "Ratio of volume of liquid found in engine cooling system to total cooling system volume.  Typical monitoring location is in the coolant expansion tank.";
CM_ SG_ 2566844414 EngCoolantPress "Gage pressure of liquid found in engine cooling system.

See SPN 20 for alternate range and resolution.";
CM_ SG_ 2566844414 EngCrankcasePress "First instance of the gage pressure inside engine crankcase.";
CM_ SG_ 2566844414 EngOilPress "Gage pressure of oil in engine lubrication system as provided by oil pump.  See SPN 7468 for alternate resolution.";
CM_ SG_ 2566844414 EngOilLevel "Ratio of current volume of engine sump oil to maximum required volume.";
CM_ SG_ 2566844414 EngExCrankcaseBlowbyPress "Differential crankcase blow-by pressure as measured through a tube with a venturi. 

(SPN 1264 is not to be used - obsolete)";
CM_ SG_ 2566844414 EngFuelDeliveryPress "Gage pressure of fuel in system as delivered from supply pump to the injection pump.  See SPN 7469 for alternate resolution.

See also SPN 5578 for Fuel Delivery Absolute Pressure.";
CM_ BO_ 2633929726 "Engine Electrical System/Module Information";
CM_ SG_ 2633929726 SafetyWireStatus "Status signal which indicates that the safety wire has been activated.  When the safety wire is activated, the engine will not operate.  This is used for maintenance purposes.
00 - Safety wire has not been activated
01 - Safety wire has been ...";
CM_ SG_ 2633929726 ElectricalLoad "Electrical power delivered by the engine to the electrical system connected to the generator.";
CM_ BO_ 2566772222 "Electronic Engine Controller 5
Engine related parameters";
CM_ SG_ 2566772222 EngVrblGeometryTurbo1ActuatorPos "Sensor that measures the position of the variable geometry turbocharger actuator.  A  position of 0% indicates the actuator is in the position creating the smallest geometry turbocharger. A position of 100% represents the largest geometry ...";
CM_ SG_ 2566772222 EngVriableGeometryTurbo1CtrlMode "Indicates if the variable geometry turbocharger control status is either open loop or closed loop.

00 open loop
01 closed loop
10 SAE reserved
11 not available";
CM_ SG_ 2566772222 EngFuelCtrlCtrlMode "Indicates whether the Engine Fuel Control System is in open loop or closed loop.

00     Open loop
01     Closed loop
10     SAE reserved
11     Not available";
CM_ SG_ 2566772222 EngVrblGmtryTrbArCtrlShtoffValve "Isolates vehicle brake air from the Variable Geometry Turbocharger (VGT) system when engine is not running.  This valve prevents vehicle air from bleeding off through the VGT Control Valve when engine is not in use.  Primary vehicle air system from ...";
CM_ SG_ 2566772222 EngExhstGsRcirculation1ValveCtrl "Desired percentage of maximum Exhaust Gas Recirculation (EGR) valve 1 opening.  0% means valve is closed. 100% means maximum valve opening (full gas flow).";
CM_ SG_ 2566772222 EngTrb1ClclatedTurbineOutletTemp "Calculated value of turbocharger compressor outlet air temperature.  Temperature of air exiting the turbocharger compressor and before entering charge air cooler.  The estimate is based on turbo speed and measured turbocharger compressor intake ...";
CM_ SG_ 2566772222 EngTrb1ClclatedTurbineIntakeTemp "Calculated value of turbine intake temperature based on engine operating conditions, such as intake manifold temperature, charge fuel ratio, injection timing, and engine speed.  Use SPN 1180 for actual measured intake temperature.";
CM_ BO_ 2633940734 "Electronic Engine Controller 4";
CM_ SG_ 2633940734 PrelubeOilLowPressThreshold "The minimum value that the engine oil pressure (SPN 100 and SPN 7468) must exceed in order to start the engine.

This parameter is intended for applications that have an external means of lubricating the engine before starting the engine.";
CM_ SG_ 2633940734 CrnkAttmptCntOnPrsntStartAttempt "Reports the number of cranking cycles undergone during the present start attempt.
Note:  This is intended to be used in conjunction with Maximum Crank Attempts per Start Attempt, in order to give a FMI 0 diagnostic on this parameter when the count ...";
CM_ SG_ 2633940734 EngIntakeManifoldPressCtrlMode "Indicates that the Boost Pressure Closed Loop Control status either open loop or closed loop.

00  Open loop 
01  Closed loop 
10  SAE reserved
11  Not available";
CM_ SG_ 2633940734 EngRotationDirection "Direction of engine rotation, as reported by the engine.  Direction convention as viewed by an observer standing at the rear of the engine, viewing the flywheel.
00 - CounterClockWise (CCW)
01 - ClockWise (CW)
10 - Unknown  (Rotation Direction ...";
CM_ SG_ 2633940734 EngRatedSpeed "The maximum governed rotational velocity of the engine crankshaft under full load conditions.  Note that the engine speed at point 2 (SPN 528) is equal to rated engine speed only in the case when the engine has not been derated.  Please also ...";
CM_ SG_ 2633940734 EngRatedPower "Net brake power that the engine will deliver continuously, specified for a given application at a rated speed.";
CM_ BO_ 2566840318 "Electronic Engine Controller 3";
CM_ SG_ 2566840318 AFT2ExhDewPoint "Indicates that the temperature on the exhaust side of the aftertreatment has exceeded the dew point, as estimated by the ECU in exhaust bank 2.

00 - Not exceeded the dew point
01 - Exceeded the dew point
10 - Error
11 - Not available";
CM_ SG_ 2566840318 AFT2InDewPoint "Indicates that the temperature on the intake side of the aftertreatment system has exceeded the dew point, as estimated by the ECU in exhaust bank 2.

00 - Not exceeded the dew point
01 - Exceeded the dew point
10 - Error
11 - Not available";
CM_ SG_ 2566840318 AFT1ExhDewPoint "Indicates that the temperature on the exhaust side of the aftertreatment has exceeded the dew point, as estimated by the ECU in exhaust bank 1.

00 - Not exceeded the dew point
01 - Exceeded the dew point
10 - Error
11 - Not available";
CM_ SG_ 2566840318 AFT1InDewPoint "Indicates that the temperature on the intake side of the aftertreatment system has exceeded the dew point, as estimated by the ECU in exhaust bank 1.

00 - Not exceeded the dew point
01 - Exceeded the dew point
10 - Error
11 - Not available";
CM_ SG_ 2566840318 AFT1ExhGasMFR "Measured/calculated exhaust gas mass upstream of the aftertreatment쟳ystem in exhaust bank 1 and 2.";
CM_ SG_ 2566840318 EstEngPrsiticLossesPercentTorque "The calculated torque that indicates the estimated amount of torque loss due to engine parasitics, such as cooling fan, air compressor, air conditioning, etc. It is expressed as a percent of Engine Reference Torque.
If there are multiple devices on ...";
CM_ SG_ 2566840318 EngnsDsrdOprtngSpdAsymmtryAdjstm "This byte is utilized in transmission gear selection routines and indicates the engine's preference of lower versus higher engine speeds should its desired speed not be achievable.  This is a scaled ratio such that 125 represents an equal preference ...";
CM_ SG_ 2566840318 EnginesDesiredOperatingSpeed "An indication by the engine of the optimal operating speed of the engine for the current existing conditions.  These conditions may include the torque generated to accommodate powertrain demands from the operator (via the accelerator pedal), cruise ...";
CM_ SG_ 2566840318 NominalFrictionPercentTorque "The calculated torque that indicates the amount of torque required by the basic engine itself added by the loss torque of accessories.  It contains the frictional and thermodynamic loss of the engine itself, pumping torque loss (SPN 5398), and the ...";
CM_ BO_ 2364539902 "Electronic Engine Controller 2
Identifies electronic engine control related parameters.";
CM_ SG_ 2364539902 EstPumpingPercentTorque "The calculated torque that indicates the estimated amount of torque loss due to the engine air handling system. The value transmitted in this parameter is included in SPN 514 (Nominal Friction - Percent Torque).  The data is transmitted as a percent ...";
CM_ SG_ 2364539902 ActlMaxAvailableEngPercentTorque "This is the maximum amount of torque that the engine can immediately deliver as a percentage of the reference engine torque (SPN 544).  The Actual Maximum Available Engine - Percent Torque shall take into consideration all engine torque derates ...";
CM_ SG_ 2364539902 SCRThermalManagementActive "Indicates that the exhaust temperatures have been elevated for regeneration of the SCR aftertreatment system or in preparation of regeneration of the SCR aftertreatment system.
00 - SCR Thermal Management is not active
01 - SCR Thermal Management ...";
CM_ SG_ 2364539902 DPFThermalManagementActive "Indicates that the exhaust temperatures have been elevated for regeneration of the diesel particulate filter aftertreatment system or in preparation of regeneration of the diesel particulate aftertreatment system.
00 - DPF Thermal Management is not ...";
CM_ SG_ 2364539902 MmntaryEngMaxPowerEnableFeedback "Momentarily requesting Engine Maximum Power Enable - feature support feedback

00 disabled
01 supported 
10 reserved
11 don't care";
CM_ SG_ 2364539902 VhcleAccelerationRateLimitStatus "Status (active or not active) of the system used to limit maximum forward vehicle acceleration.
00     Limit not active
01     Limit active
10     Reserved
11     Not available
NOTE:  The effects of emission control limits, such as engine ...";
CM_ SG_ 2364539902 AccelPedalPos2 "The ratio of actual position of the second analog engine speed/torque request input device (such as an accelerator pedal or throttle lever) to the maximum position of the input device.  This parameter is intended for secondary accelerator control in ...";
CM_ SG_ 2364539902 RemoteAccelPedalPos "The ratio of actual position of the remote analog engine speed/torque request input device (such as an accelerator pedal or throttle lever) to the maximum position of the input device.
For example, in on-highway vehicles this could be an ...";
CM_ SG_ 2364539902 EngPercentLoadAtCurrentSpeed "The ratio of actual engine percent torque (indicated) to maximum indicated torque available at the current engine speed, clipped to zero torque during engine braking.";
CM_ SG_ 2364539902 AccelPedalPos1 "The ratio of actual position of the analog engine speed/torque request input device (such as an accelerator pedal or throttle lever) to the maximum position of the input device.  This parameter is intended for the primary accelerator control in an ...";
CM_ SG_ 2364539902 AccelPedal2LowIdleSwitch "Switch signal which indicates the state of the accelerator pedal 2 low idle switch.  The low idle switch is defined in SAE J1843.
00    Accelerator pedal 2 not in low idle condition
01    Accelerator pedal 2 in low idle condition
10    Error
11 ...";
CM_ SG_ 2364539902 RoadSpeedLimitStatus "Status (active or not active) of the system used to limit maximum vehicle velocity.
00 - Active
01 - Not Active
10 - Error
11 - Not available
NOTE - While somewhat inconsistent with other J1939 status parameters, the states defining 00 = active ...";
CM_ SG_ 2364539902 AccelPedalKickdownSwitch "Switch signal which indicates whether the accelerator pedal kickdown switch is opened or closed.  The kickdown switch is defined in SAE J1843.

00 - Kickdown passive
01 - Kickdown active
10 - Error
11 - Not available";
CM_ SG_ 2364539902 AccelPedal1LowIdleSwitch "Switch signal which indicates the state of the accelerator pedal 1 low idle switch.  The low idle switch is defined in SAE Recommended Practice J1843.
00 - Accelerator pedal 1 not in low idle condition
01 - Accelerator pedal 1 in low idle ...";
CM_ BO_ 2364540158 "Electronic Engine Controller 1
Engine related parameters";
CM_ SG_ 2364540158 EngDemandPercentTorque "The requested torque output of the engine by all dynamic internal inputs, including smoke control, noise control and low and high speed governing.";
CM_ SG_ 2364540158 EngStarterMode "There are several phases in a starting action and different reasons why a start cannot take place.
0000b - start not requested
0001b - starter active but not engaged
0010b - starter active and engaged
0011b - start finished; starter not active ...";
CM_ SG_ 2364540158 SrcAddrssOfCntrllngDvcForEngCtrl "The source address of the SAE J1939 device currently controlling the engine.  It is used to expand the torque mode parameter (see SPN 899) in cases where control is in response to an ECU that is not listed in Table SPN899_A.  Its value may be the ...";
CM_ SG_ 2364540158 EngSpeed "Actual engine speed which is calculated over a minimum crankshaft angle of 720 degrees divided by the number of cylinders.";
CM_ SG_ 2364540158 ActualEngPercentTorque "The calculated output torque of the engine.  The data is transmitted in indicated torque as a percent of reference engine torque (see the engine configuration message, PGN 65251).  The engine percent torque value will not be less than zero and it ...";
CM_ SG_ 2364540158 DriversDemandEngPercentTorque "The requested torque output of the engine by the driver. It is based on input from the following requestors external to the powertrain: operator (via the accelerator pedal), cruise control and/or road speed limit governor. Dynamic commands from ...";
CM_ SG_ 2364540158 ActlEngPrcntTorqueHighResolution "This parameter displays an additional torque in percent of the reference engine torque.
When the MSB is set to 1, this parameter is not available.  When the MSB is set to 0, bits 1 to 3 indicate the desired torque with resolution of 0.125%/bit  ...";
CM_ SG_ 2364540158 EngTorqueMode "State signal which indicates which engine torque mode is currently generating, limiting, or controlling the torque.  Note that the modes are not in prioritized order. Not all modes may be relevant for a given device.  Some devices may not implement ...";
CM_ BO_ 2566768126 "ECU Identification Information
Message for reporting identification and information about the physical ECU and its hardware, such as the ECU's part number, serial number, build date, etc.  Information about the software within the ECU should be ...";
CM_ SG_ 2566768126 ECUHardwareID "The ECU Hardware ID provides information to identify a specific ECU hardware version.
As an example, on a CAN network, this parameter can be used to uniquely identify the hardware version that is relevant for the interface of the ECU to the CAN ...";
CM_ SG_ 2566768126 ECUManufacturerName "The name of the manufacturer of the physical ECU.

This name may be different than the manufacturer identified by the Manufacturer Code (SPN 2838) and listed in table B10 of J1939.";
CM_ SG_ 2566768126 ECUType "The type of ECU.  One example of a use of the ECU type could be for classifying ECU capabilities, such as I/O.";
CM_ SG_ 2566768126 ECULocation "The location of the ECU within a network.";
CM_ SG_ 2566768126 ECUSerialNumber "The serial number of the physical ECU.";
CM_ SG_ 2566768126 ECUPartNumber "The part number of the physical ECU.";
CM_ BO_ 2566804734 "Engine Continuous Torque & Speed Limit";
CM_ SG_ 2566804734 EngMinContinuousTorque "Applied limit for minimum continuous engine torque";
CM_ SG_ 2566804734 EngMaxContinuousTorque "Applied limit for maximum continuous engine torque.";
CM_ SG_ 2566804734 EngMinContinuousRPM "Applied limit for minimum continuous engine RPM";
CM_ SG_ 2566804734 EngMaxContinuousRPM "Applied limit for maximum continuous engine RPM";
CM_ SG_ 2566804734 EngHghLmtThrshldFrMnCntnsTrqFrmE "Maximum allowable value for minimum continuous torque from engine";
CM_ SG_ 2566804734 EngLwLmtThrshldFrMxTorqueFromEng "Minimum allowable value for maximum continuous torque from engine";
CM_ SG_ 2566804734 EngHghLmtThrshldFrMnCntnusEngRPM "Maximum allowable value for minimum continuous RPM from engine";
CM_ SG_ 2566804734 EngLwLmtThrsholdForMaxRPMFromEng "Minimum allowable value for maximum continuous RPM from engine";
CM_ BO_ 2566841342 "Engine Configuration 1
This map describes the stationary behavior of the engine and the speed dependent available indicated torque.  This map should reflect the effect of changes due to barometric pressure, engine temperature, and any other ...";
CM_ SG_ 2566841342 DefaultIdleTrqLmt "Companion parameter to 밫ransmission Communications Failure Idle Torque Limit� (SPN 7827).  This 밻cho� parameter provides confirmation to the transmission that the engine has received and will invoke the requested SPN 7827 밫ransmission ...";
CM_ SG_ 2566841342 SupportTSC1CtrlPurposeGroup4 "This parameter indicates which TSC1 control purposes are supported in group 4 of 4. One bit is used to convey the support of each Control Purpose. A value of 0 equals supported and a value of 1 equals not supported. This bit logic is used to allow ...";
CM_ SG_ 2566841342 SupportTSC1CtrlPurposeGroup3 "This parameter indicates which TSC1 control purposes are supported in group 3 of 4. One bit is used to convey the support of each Control Purpose. A value of 0 equals supported and a value of 1 equals not supported. This bit logic is used to allow ...";
CM_ SG_ 2566841342 SupportTSC1CtrlPurposeGroup2 "This parameter indicates which TSC1 control purposes are supported in group 2 of 4. One bit is used to convey the support of each Control Purpose. A value of 0 equals supported and a value of 1 equals not supported. This bit logic is used to allow ...";
CM_ SG_ 2566841342 SupportTSC1CtrlPurposeGroup1 "This parameter indicates which TSC1 control purposes are supported in group 1 of 4. One bit is used to convey the support of each Control Purpose. A value of 0 equals supported and a value of 1 equals not supported. This bit logic is used to allow ...";
CM_ SG_ 2566841342 SupportVariableRateTSC1Message "This parameter indicates which TSC1 transmission rates are supported by the engine ECU in addition to the required 10ms transmission rate for temporary powertrain control purposes.
Bit Position      Transmission Rate
1                      1000 ms ...";
CM_ SG_ 2566841342 EngDefaultTorqueLimit "Companion parameter to Transmission Torque Limit (SPN 1845).  This 밻cho� parameter provides confirmation to the transmission that the engine has received and will invoke the requested Transmission Torque Limit in the event that J1939 communication ...";
CM_ SG_ 2566841342 EngMomentOfInertia "Moment of inertia for the engine, including items driven full-time by the engine such as fuel, oil and cooling pumps.  The inertia from the following items are not included: flywheel, alternator, compressor, fan, and other engine-driven accessories.";
CM_ SG_ 2566841342 EngExRngRqstdSpdCtrlRngUpprLimit "The maximum engine speed regardless of load that the engine will allow when operating in a speed control/limit mode, excluding any maximum momentary engine override speed, if supported.
When the limit is higher than 2500 RPM the 'Requested Speed ...";
CM_ SG_ 2566841342 EngRqstdTrqueCtrlRangeUpperLimit "The maximum engine torque that the engine will allow when operating in a torque control/limit mode.";
CM_ SG_ 2566841342 EngRqstdTrqueCtrlRangeLowerLimit "The minimum engine torque that the engine will allow when operating in a torque control/limit mode.";
CM_ SG_ 2566841342 EngRqstdSpeedCtrlRangeUpperLimit "The maximum engine speed regardless of load that the engine will allow when operating in a speed control/limit mode, excluding any maximum momentary engine override speed, if supported.";
CM_ SG_ 2566841342 EngRqstdSpeedCtrlRangeLowerLimit "The minimum engine speed that the engine will allow when operating in a speed control/limit mode.";
CM_ SG_ 2566841342 EngMaxMomentaryOverrideTimeLimit "The maximum time limit allowed to override the engine's high idle speed.";
CM_ SG_ 2566841342 EngMxMmentaryOverrideSpeedPoint7 "The maximum engine speed above high idle allowed by the engine control during a momentary high idle override.  This duration of the override is limited by the maximum momentary override time limit, SPN 534.";
CM_ SG_ 2566841342 EngReferenceTorque "This parameter is the 100% reference value for all defined indicated engine torque parameters.  It is only defined once and doesn't change if a different engine torque map becomes valid.";
CM_ SG_ 2566841342 EngGain "The endspeed governor is defined as a linear line with the following equations (Capital letters mean physical values, small letters mean normalized values).  Refer to Figures PGN65251_A and PGN65251_B.
The gain KP/kp is defined as a positive value ...";
CM_ SG_ 2566841342 EngSpeedAtHighIdlePoint6 "Engine speed of high idle (point 6) of the engine torque map (see PGN 65251 and supporting document).  In engine configuration mode 3 (see Figure PGN65251_C), point 6 is not defined by the engine torque map but by the governor characteristic and the ...";
CM_ SG_ 2566841342 EngPercentTorqueAtPoint5 "The torque limit that indicates the available engine torque which can be provided by the engine at point 3, 4, and 5 of the engine map (see PGN 65251 and supporting documents).  It is required that one of these points indicate the peak torque point ...";
CM_ SG_ 2566841342 EngSpeedAtPoint5 "Engine speed of point 3, 4, and 5 of the engine torque map (see PGN 65251 and supporting document).  It is recommended that one of these points indicate the peak torque point for the current engine torque map.  Points 3, 4, and 5 are optional and ...";
CM_ SG_ 2566841342 EngPercentTorqueAtPoint4 "The torque limit that indicates the available engine torque which can be provided by the engine at point 3, 4, and 5 of the engine map (see PGN 65251 and supporting documents).  It is required that one of these points indicate the peak torque point ...";
CM_ SG_ 2566841342 EngSpeedAtPoint4 "Engine speed of point 3, 4, and 5 of the engine torque map (see PGN 65251 and supporting document).  It is recommended that one of these points indicate the peak torque point for the current engine torque map.  Points 3, 4, and 5 are optional and ...";
CM_ SG_ 2566841342 EngPercentTorqueAtPoint3 "The torque limit that indicates the available engine torque which can be provided by the engine at point 3, 4, and 5 of the engine map (see PGN 65251 and supporting documents)..  It is required that one of these points indicate the peak torque point ...";
CM_ SG_ 2566841342 EngSpeedAtPoint3 "Engine speed of point 3, 4, and 5 of the engine torque map (see PGN 65251 and supporting document).  It is recommended that one of these points indicate the peak torque point for the current engine torque map.  Points 3, 4, and 5 are optional and ...";
CM_ SG_ 2566841342 EngPercentTorqueAtPoint2 "The torque limit that indicates the available engine torque which can be provided by the engine at point 2 of the engine map (see PGN 65251 and supporting documents).  In engine configuration mode 1 and 3 (see Table PGN65251_A see PGN 65251), point ...";
CM_ SG_ 2566841342 EngSpeedAtPoint2 "Engine speed of point 2 of the engine torque map (see PGN 65251 and supporting document).  In engine configuration mode 1 and 3, point 2 is defined as the kick-in point from which torque is reduced to zero.  In mode 2 (see Table PGN65251_A), there ...";
CM_ SG_ 2566841342 EngPercentTorqueAtIdlePoint1 "The torque limit that indicates the available engine torque which can be provided by the engine at idle speed.  This parameter may be influenced by engine temperature (after power up) and other stationary changes (calibration offsets, sensor ...";
CM_ SG_ 2566841342 EngSpeedAtIdlePoint1 "Stationary low idle speed of engine which includes influences due to engine temperature (after power up) and other stationary changes (calibration offsets, sensor failures, etc).  This parameter is point 1 of the engine configuration map (see PGN ...";
CM_ BO_ 2566767870 "Electronic Brake Controller 5
Used for information on brake control.";
CM_ SG_ 2566767870 RailroadMode "Signal which indicates the current state of the Railroad Mode / Function.
00 - Inactive (Driving mode: Steer Axle on ground)
01 - Active (Railroad mode: Steer Axle lifted off ground)
10 - Error
11 - Not available
Note: This status signal may be ...";
CM_ SG_ 2566767870 EmergencyBrakingActive "Signal which indicates an emergency braking situation (ref. ECE Regulation 13 paragraph 5.2.1.31) with high  deceleration values.  This signal can be used to activate the hazard lights (ref ECE Regulation 48 paragraph 6.23) to
indicate other road ...";
CM_ SG_ 2566767870 PrkngBrakeActuatorFullyActivated "Signal which indicates when the parking brake actuator is fully activated.  (see also SPN 70 and 619).

00 - Parking Brake Actuator not fully activated
01 - Parking Brake Actuator fully activated
10 - Error
11 - Not available";
CM_ SG_ 2566767870 XBRAccelerationLimit "The brake system may temporarily or generally limit the maximum brake performance available for external systems. A temporary limit may be nessary due to high brake temperature; a general limit may be defined by the vehicle manufacturer, e.g. a ...";
CM_ SG_ 2566767870 XBRActiveCtrlMode "This parameter indicates which XBR Control Mode is executed by the brake system.
0000                No brake demand being executed (default mode)
0001                Driver's brake demand being executed, no external brake demand
0010 ...";
CM_ SG_ 2566767870 XBRSystemState "This parameter indicates which external brake control is allowed.
00 - Any external brake demand will be accepted (brake system fully operational)
01 - Only external brake demand of highest XBR Priority (00) will be accepted  (e.g. because the ...";
CM_ SG_ 2566767870 FoundationBrakeUse "This parameter indicates if the brake system presently uses the foundation brakes.

00   Foundation brakes not in use
01   Foundation brakes in use
10   Reserved
11   Not available";
CM_ SG_ 2566767870 HillHolderMode "Signal which indicates the current mode of the hill holder function.
000            Inactive
001            Active
010            Active, but will change to inactive in a short time.  (This mode may be used to warn the driver)
011 ...";
CM_ SG_ 2566767870 HaltBrakeMode "Signal which indicates the current mode of the halt brake function.
000            Inactive
001            Active
010            Active, but not functioning properly.  (This mode may be used to warn the driver)
011 - 101  Not defined
110 ...";
CM_ SG_ 2566767870 BrakeTempWarning "This parameter indicates if the temperature in the service brakes exceeds a certain value. It can be used for a warning information for the driver. The temperature warning value is vehicle manufacturer specific.
00 Not Active
01 Active
10 ...";
CM_ BO_ 2633936126 "Wheel Brake Lining Remaining Information";
CM_ SG_ 2633936126 BrkLnngRmningRearAxle3RightWheel "The percentage of brake lining which can still be measured for the right wheel on the rear axle #3.  100% represents new brake linings, 0% represents totally worn brake linings.";
CM_ SG_ 2633936126 BrkLnngRminingRearAxle3LeftWheel "The percentage of brake lining which can still be measured for the left wheel on the rear axle #3.  100% represents new brake linings, 0% represents totally worn brake linings.";
CM_ SG_ 2633936126 BrkLnngRmningRearAxle2RightWheel "The percentage of brake lining which can still be measured for the right wheel on the rear axle #2.  100% represents new brake linings, 0% represents totally worn brake linings.";
CM_ SG_ 2633936126 BrkLnngRminingRearAxle2LeftWheel "The percentage of brake lining which can still be measured for the left wheel on the rear axle #2.  100% represents new brake linings, 0% represents totally worn brake linings.";
CM_ SG_ 2633936126 BrkLnngRmningRearAxle1RightWheel "The percentage of brake lining which can still be measured for the right wheel on the rear axle #1.  100% represents new brake linings, 0% represents totally worn brake linings.";
CM_ SG_ 2633936126 BrkLnngRminingRearAxle1LeftWheel "The percentage of brake lining which can still be measured for the left wheel on the rear axle #1.  100% represents new brake linings, 0% represents totally worn brake linings.";
CM_ SG_ 2633936126 BrkLnngRmningFrontAxleRightWheel "The percentage of brake lining which can still be measured for the right wheel on the front axle.  100% represents new brake linings, 0% represents totally worn brake linings.";
CM_ SG_ 2633936126 BrkLnngRminingFrontAxleLeftWheel "The percentage of brake lining which can still be measured for the left wheel on the front axle.  100% represents new brake linings, 0% represents totally worn brake linings.";
CM_ BO_ 2566827518 "Wheel Application Pressure High Range Information";
CM_ SG_ 2566827518 BrkAppPrssHghRngRrAxl3RightWheel "The brake application pressure for the right wheel on the rear axle #3.";
CM_ SG_ 2566827518 BrkAppPrssHghRngRrAxle3LeftWheel "The brake application pressure for the left wheel on the rear axle #3.";
CM_ SG_ 2566827518 BrkAppPrssHghRngRrAxl2RightWheel "The brake application pressure for the right wheel on the rear axle #2.";
CM_ SG_ 2566827518 BrkAppPrssHghRngRrAxle2LeftWheel "The brake application pressure for the left wheel on the rear axle #2.";
CM_ SG_ 2566827518 BrkAppPrssHghRngRrAxle1LeftWheel "The brake application pressure for the left wheel on the rear axle #1.";
CM_ SG_ 2566827518 BrkAppPrssHghRngFrntAxlRghtWheel "The brake application pressure for the right wheel on the front axle.";
CM_ SG_ 2566827518 BrkAppPrssHghRngFrntAxlLeftWheel "The brake application pressure for the left wheel on the front axle.";
CM_ SG_ 2566827518 BrkAppPrssHghRngRrAxl1RightWheel "The brake application pressure for the right wheel on the rear axle #1.";
CM_ BO_ 2566832126 "Wheel Speed Information";
CM_ SG_ 2566832126 RelativeSpeedRearAxle2RightWheel "The speed of the rear axle #2, right wheel relative to the front axle speed, SPN 904.";
CM_ SG_ 2566832126 RelativeSpeedRearAxle2LeftWheel "The speed of the rear axle #2, left wheel relative to the front axle speed, SPN 904.";
CM_ SG_ 2566832126 RelativeSpeedRearAxle1RightWheel "The speed of the rear axle #1, right wheel relative to the front axle speed, SPN 904.";
CM_ SG_ 2566832126 RelativeSpeedRearAxle1LeftWheel "The speed of the rear axle #1, left wheel relative to the front axle speed, SPN 904.";
CM_ SG_ 2566832126 RelativeSpeedFrontAxleRightWheel "The speed of the front axle, right wheel relative to the front axle speed, SPN 904.";
CM_ SG_ 2566832126 RelativeSpeedFrontAxleLeftWheel "The speed of the front axle, left wheel relative to the front axle speed, SPN 904.";
CM_ SG_ 2566832126 FrontAxleSpeed "The average speed of the two front wheels.";
CM_ BO_ 2565865982 "Electronic Brake Controller 1
Used for brake control information";
CM_ SG_ 2565865982 RailroadModeSw "Switch signal which indicates the position of the Railroad mode switch.
00 - Railroad mode switch passive (City/Highway mode)
01 - Railroad mode switch active (Railroad mode)
10 - Error
11 - Not available
Note:  This switch signal to be used to ...";
CM_ SG_ 2565865982 TrctrMntdTrailerABSWarningSignal "This parameter commands the tractor-mounted trailer ABS optical warning signal.

00 Off
01 On 
10 Reserved
11 Take no action";
CM_ SG_ 2565865982 TrailerABSStatus "State signal which indicates that ABS in the trailer is actively controlling the brakes.  A message is sent to the tractor from the trailer (i.e. by PLC). The receiving device in the tractor transfers this information to the J1939 network.  At the ...";
CM_ SG_ 2565865982 HaltBrakeSwitch "Switch signal which indicates the position of the halt brake switch.

00    Halt brake switch passive
01    Halt brake switch active
10    Error
11    Not available";
CM_ SG_ 2565865982 SrcAddrssOfCntrllngDvcFrBrkeCtrl "The source address of the SAE J1939 device currently controlling the brake system. Its value may be the source address of the ECU transmitting the message (which means that no external SAE J1939 message is providing the active command) or the source ...";
CM_ SG_ 2565865982 ATC_ASRInformationSignal "This parameter commands the ATC/ASR driver information signal, for example a dash lamp.

00 Off
01 On 
10 Reserved
11 Take no action";
CM_ SG_ 2565865982 ABS_EBSAmberWarningSignal "This parameter commands the ABS/EBS amber/yellow optical warning signal

00 Off
01 On
10 Reserved
11 Take no action";
CM_ SG_ 2565865982 EBSRedWarningSignal "This parameter commands the EBS red optical warning signal

00 Off
01 On
10 Reserved
11 Take no action";
CM_ SG_ 2565865982 ABSFullyOperational "Signal which indicates whether an ABS system is fully operational or whether its functionality is reduced by a defect or by an intended action (e.g., by activation of an ABS-off-road switch or during special diagnostic procedures).  There are cases ...";
CM_ SG_ 2565865982 EngRetarderSelection "The position of the operator controlled selector, expressed as a percentage and determined by the ratio of the current position of the selector to its maximum possible position. Zero percent means no braking torque is requested by the operator from ...";
CM_ SG_ 2565865982 RemoteAccelEnableSwitch "Switch signal which indicates that the remote accelerator has been enabled and controls the engine.
00 - Off
01 - On
10 - Error
11 - Not available
NOTE뾗he accelerator interlock switch (see SPN 972) must be disabled in order for the remote ...";
CM_ SG_ 2565865982 EngAuxShutdownSwitch "Switch signal which requests that all engine fueling stop.

00 - Off
01 - On
10 - Error
11 - Not available";
CM_ SG_ 2565865982 EngDerateSwitch "Switch signal used to activate the torque limiting feature of the engine.  The specific nature of torque limiting should be verified with the manufacturer.

00 - Off
01 - On
10 - Error
11 - Not available";
CM_ SG_ 2565865982 AccelInterlockSwitch "Switch signal used to disable the accelerator and remote accelerator inputs, causing the engine to return to idle.

00 - Off
01 - On
10 - Error
11 - Not available";
CM_ SG_ 2565865982 TractionCtrlOverrideSwitch "Switch signal which indicates the position of the traction control override switch.  The traction control override signal disables the automatic traction control function allowing the wheels to spin.
00 - Off
01 - On
10 - Error
11 - Not ...";
CM_ SG_ 2565865982 ASRHillHolderSwitch "Switch signal which indicates the position of the ASR 밾ill holder� switch.

00 - ASR 밾ill holder� switch passive
01 - ASR 밾ill holder� switch active
10 - Error
11 - Not available";
CM_ SG_ 2565865982 ASROffroadSwitch "Switch signal which indicates the position of the ASR off-road switch.

00 - ASR off-road switch passive
01 - ASR off-road switch active
10 - Error
11 - Not available";
CM_ SG_ 2565865982 ABSOffroadSwitch "Switch signal which indicates the position of the ABS off-road switch.

00 - ABS off-road switch passive
01 - ABS off-road switch active
10 - Error
11 - Not available";
CM_ SG_ 2565865982 BrakePedalPos "Ratio of brake pedal position to maximum pedal position.  Used for electric brake applications. 0% means no braking. Also when there are two brake pedals on the machine (Left Brake Pedal Position SPN 3033 and Right Brake Pedal Position SPN 3032) the ...";
CM_ SG_ 2565865982 EBSBrakeSwitch "Switch signal which indicates that the brake pedal is being pressed.  The EBS brake switch is independent of the brake light switch and has no provisions for external connections.
00 - Brake pedal is not being pressed
01 - Brake pedal is being ...";
CM_ SG_ 2565865982 AntiLockBrakingActive "State signal which indicates that the ABS is active.  The signal is set active when wheel brake pressure actually starts to be modulated by ABS and is reset to passive when all wheels are in a stable condition for a certain time.  The signal can ...";
CM_ SG_ 2565865982 ASRBrakeCtrlActive "State signal which indicates that ASR brake control is active. Active means that ASR actually controls wheel brake pressure at one or more wheels of the driven axle(s).
00 - ASR brake control passive but installed
01 - ASR brake control active
10 ...";
CM_ SG_ 2565865982 ASREngCtrlActive "State signal which indicates that ASR engine control has been commanded to be active. Active means that ASR actually tries to control the engine. This state signal is independent of other control commands to the engine (e.g., from the transmission) ...";
CM_ BO_ 2565867262 "Electronic Axle Controller 1
NOTE - Request has to be responded to with as many messages as necessary to transmit all available information.";
CM_ SG_ 2565867262 DiffLockStRearAxle3 "State used which indicates the condition of the rear axle 3 differential lock. The differential locks are located as defined in figure SPN 564_A.

00 - Differential lock disengaged
01 - Differential lock engaged
10 - Error
11 - Not available";
CM_ SG_ 2565867262 RearAxleGroupEngagementStatus "Rear axle group engagement status

00 rear axle group disengaged 
01 rear axle group engaged
10 error
11 not available";
CM_ SG_ 2565867262 FrontAxleGroupEngagementStatus "Front axle group engagement status 

00 front axle group disengaged 
01 front axle group engaged
10 error
11 not available";
CM_ SG_ 2565867262 DiffLockStateCentralRear "State used which indicates the condition of the central rear differential lock.  The differential locks are located as defined in figure SPN564_A.

00 Differential lock disengaged
01 Differential lock engaged
10 Error
11 Not available";
CM_ SG_ 2565867262 DiffLockStateCentralFront "State used which indicates the condition of the central front differential lock.  The differential locks are located as defined in figure SPN564_A.

00 Differential lock disengaged
01 Differential lock engaged
10 Error
11 Not available";
CM_ SG_ 2565867262 DiffLockStateCentral "State used which indicates the condition of the central differential lock.  The differential locks are located as defined in attached figure SPN564_A.

00 Differential lock disengaged
01 Differential lock engaged
10 Error
11 Not available";
CM_ SG_ 2565867262 DiffLockStateRearAxle2 "State used which indicates the condition of the rear axle 2 differential lock.  The differential locks are located as defined in figure SPN 564_A.

00 Differential lock disengaged
01 Differential lock engaged
10 Error
11 Not available";
CM_ SG_ 2565867262 DiffLockStateRearAxle1 "State used which indicates the condition of the rear axle 1 differential lock.  The differential locks are located as defined in figure SPN 564_A.

00 Differential lock disengaged
01 Differential lock engaged
10 Error
11 Not available";
CM_ SG_ 2565867262 DiffLockStateFrontAxle2 "State used which indicates the condition of the front axle 2 differential lock. The differential locks are located as defined in figure SPN 564_A.

00 Differential lock disengaged
01 Differential lock engaged
10 Error
11 Not available";
CM_ SG_ 2565867262 DiffLockStateFrontAxle1 "State used which indicates the condition of the front axle 1 differential lock.  The differential locks are located as defined in figure SPN564_A.

00 Differential lock disengaged
01 Differential lock engaged
10 Error
11 Not available";
CM_ SG_ 2565867262 Location "To identify to which of several similar devices (such as tires or fuel tanks) the information applies.
The low order 4 bits represent a position number, counting left to right when facing in the direction of normal vehicle travel (forward).
The ...";
CM_ BO_ 2566821118 "Engine Auxiliary Coolant";
CM_ SG_ 2566821118 CPCoolantOutPress "Engine coolant pressure at the coolant pump outlet.";
CM_ SG_ 2566821118 EngCoolantPress2 "Gage pressure of liquid found in engine coolant system - second instance.

See also SPN 5708 for alternate range and resolution.";
CM_ SG_ 2566821118 EngExRangeCoolantPress "Gage pressure of liquid found in engine cooling system.

See also SPN 109 for alternate range and resolution.";
CM_ SG_ 2566821118 SeaWaterPumpOutletPress "Gauge pressure of liquid found at outlet of sea water pump in sea water cooling system.";
CM_ SG_ 2566821118 EngAuxCoolantTemp "Temperature of coolant found in the intercooler which is located after the turbocharger.";
CM_ SG_ 2566821118 EngAuxCoolantPress "Gage pressure of coolant found in the intercooler which is located after the turbocharger.";
CM_ BO_ 2566810622 "Driver's Identification
Field:
a Driver 1 Identification
Delimiter (ASCII �*�)
b Driver 2 Identification
Delimiter (ASCII �*�)
NOTE - If only driver card 1 is present, only the parameter driver 1 identification and two delimiters shall be ...";
CM_ SG_ 2566810622 Driver2Identification "Used to obtain the driver identity.";
CM_ SG_ 2566810622 Driver1Identification "Used to obtain the driver identity.";
CM_ BO_ 2566847742 "Dash Display 1";
CM_ SG_ 2566847742 EngOilFilterDiffPress7471 "Change in engine oil pressure, measured across the filter, due to the filter and any accumulation of solid or semisolid material on or in the filter. See SPN 99 for alternate resolution.";
CM_ SG_ 2566847742 FuelLevel2 "Ratio of volume of fuel to the total volume of fuel in the second or right-side storage container.  When Fuel Level 2 is not used, Fuel Level 1 (SPN 96) represents the total fuel in all fuel storage containers.";
CM_ SG_ 2566847742 CargoAmbientTemp "Temperature of air inside vehicle container used to accommodate cargo.";
CM_ SG_ 2566847742 EngOilFilterDiffPress "Change in engine oil pressure, measured across the filter, due to the filter and any accumulation of solid or semisolid material on or in the filter.  See SPN 7471 for alternate resolution.";
CM_ SG_ 2566847742 EngFuelFilterDiffPress "Change in fuel delivery pressure, measured across the filter, due to accumulation of solid or semisolid matter on the filter element.";
CM_ SG_ 2566847742 FuelLevel1 "Ratio of volume of fuel to the total volume of fuel storage container.
When Fuel Level 2 (SPN 38) is not used, Fuel Level 1 represents the total fuel in all fuel storage containers.  When Fuel Level 2 is used, Fuel Level 1 represents the fuel level ...";
CM_ SG_ 2566847742 WasherFluidLevel "Ratio of volume of liquid to total container volume of fluid reservoir in windshield wash system.";
CM_ BO_ 2498778622 "Engine Cylinder 8 Combustion Average Information
Used to transmit the average of combustion parameters of Engine Cylinder 8.
This PGN is transmitted at a defined ratio of the engine speed. The transmission rate is dependent on
SPN 6394 - Number ...";
CM_ SG_ 2498778622 EngCyl8AverageCombustionDuration "Average duration of combustion calculated over defined number of combustion cycles for engine cylinder 8 with reference to the crank angle.  Combustion duration is the difference between end of combustion and start of combustion expressed, in this ...";
CM_ SG_ 2498778622 EngCyl8AvrgCntrOfCmbustionTiming "Average timing calculated over defined number of combustion cycles for the center of combustion in engine cylinder 8 with reference to the crank angle.  Center of Combustion is used to indicate the combustion efficiency.  When the combustion happens ...";
CM_ SG_ 2498778622 EngCyl8AvrgStrtOfCmbustionTiming "Average start of combustion timing calculated over defined number of combustion cycles for engine cylinder 8 with reference to the crank angle.  When the combustion happens after the TDC (Top Dead Center) of this cylinder, the timing is referred in ...";
CM_ SG_ 2498778622 EngCyl8IndctedMeanEffectivePress "Average cylinder pressure calculated over defined number of combustion cycles for engine cylinder 8.  Negative range is to cover thermodynamic behavior during misfire.";
CM_ BO_ 2498778366 "Engine Cylinder 7 Combustion Average Information
Used to transmit the average of combustion parameters of Engine Cylinder 7.
This PGN is transmitted at a defined ratio of the engine speed. The transmission rate is dependent on
SPN 6394 - Number ...";
CM_ SG_ 2498778366 EngCyl7AverageCombustionDuration "Average duration of combustion calculated over defined number of combustion cycles for engine cylinder 7 with reference to the crank angle.  Combustion duration is the difference between end of combustion and start of combustion expressed, in this ...";
CM_ SG_ 2498778366 EngCyl7AvrgCntrOfCmbustionTiming "Average timing calculated over defined number of combustion cycles for the center of combustion in engine cylinder 7 with reference to the crank angle.  Center of Combustion is used to indicate the combustion efficiency.  When the combustion happens ...";
CM_ SG_ 2498778366 EngCyl7AvrgStrtOfCmbustionTiming "Average start of combustion timing calculated over defined number of combustion cycles for engine cylinder 7 with reference to the crank angle.  When the combustion happens after the TDC (Top Dead Center) of this cylinder, the timing is referred in ...";
CM_ SG_ 2498778366 EngCyl7IndctedMeanEffectivePress "Average cylinder pressure calculated over defined number of combustion cycles for engine cylinder 7.  Negative range is to cover thermodynamic behavior during misfire.";
CM_ BO_ 2498778110 "Engine Cylinder 6 Combustion Average Information
Used to transmit the average of combustion parameters of Engine Cylinder 6.
This PGN is transmitted at a defined ratio of the engine speed. The transmission rate is dependent on
SPN 6394 - Number ...";
CM_ SG_ 2498778110 EngCyl6AverageCombustionDuration "Average duration of combustion calculated over defined number of combustion cycles for engine cylinder 6 with reference to the crank angle.  Combustion duration is the difference between end of combustion and start of combustion expressed, in this ...";
CM_ SG_ 2498778110 EngCyl6AvrgCntrOfCmbustionTiming "Average timing calculated over defined number of combustion cycles for the center of combustion in engine cylinder 6 with reference to the crank angle.  Center of Combustion is used to indicate the combustion efficiency.  When the combustion happens ...";
CM_ SG_ 2498778110 EngCyl6AvrgStrtOfCmbustionTiming "Average start of combustion timing calculated over defined number of combustion cycles for engine cylinder 6 with reference to the crank angle.  When the combustion happens after the TDC (Top Dead Center) of this cylinder, the timing is referred in ...";
CM_ SG_ 2498778110 EngCyl6IndctedMeanEffectivePress "Average cylinder pressure calculated over defined number of combustion cycles for engine cylinder 6.  Negative range is to cover thermodynamic behavior during misfire.";
CM_ BO_ 2498777854 "Engine Cylinder 5 Combustion Average Information
Used to transmit the average of combustion parameters of Engine Cylinder 5.
This PGN is transmitted at a defined ratio of the engine speed. The transmission rate is dependent on
SPN 6394 - Number ...";
CM_ SG_ 2498777854 EngCyl5AverageCombustionDuration "Average duration of combustion calculated over defined number of combustion cycles for engine cylinder 5 with reference to the crank angle.  Combustion duration is the difference between end of combustion and start of combustion expressed, in this ...";
CM_ SG_ 2498777854 EngCyl5AvrgCntrOfCmbustionTiming "Average timing calculated over defined number of combustion cycles for the center of combustion in engine cylinder 5 with reference to the crank angle.  Center of Combustion is used to indicate the combustion efficiency.  When the combustion happens ...";
CM_ SG_ 2498777854 EngCyl5AvrgStrtOfCmbustionTiming "Average start of combustion timing calculated over defined number of combustion cycles for engine cylinder 5 with reference to the crank angle.  When the combustion happens after the TDC (Top Dead Center) of this cylinder, the timing is referred in ...";
CM_ SG_ 2498777854 EngCyl5IndctedMeanEffectivePress "Average cylinder pressure calculated over defined number of combustion cycles for engine cylinder 5.  Negative range is to cover thermodynamic behavior during misfire.";
CM_ BO_ 2498777598 "Engine Cylinder 4 Combustion Average Information
Used to transmit the average of combustion parameters of Engine Cylinder 4.
This PGN is transmitted at a defined ratio of the engine speed. The transmission rate is dependent on
SPN 6394 - Number ...";
CM_ SG_ 2498777598 EngCyl4AverageCombustionDuration "Average duration of combustion calculated over defined number of combustion cycles for engine cylinder 4 with reference to the crank angle.  Combustion duration is the difference between end of combustion and start of combustion expressed, in this ...";
CM_ SG_ 2498777598 EngCyl4AvrgCntrOfCmbustionTiming "Average timing calculated over defined number of combustion cycles for the center of combustion in engine cylinder 4 with reference to the crank angle.  Center of Combustion is used to indicate the combustion efficiency.  When the combustion happens ...";
CM_ SG_ 2498777598 EngCyl4AvrgStrtOfCmbustionTiming "Average start of combustion timing calculated over defined number of combustion cycles for engine cylinder 4 with reference to the crank angle.  When the combustion happens after the TDC (Top Dead Center) of this cylinder, the timing is referred in ...";
CM_ SG_ 2498777598 EngCyl4IndctedMeanEffectivePress "Average cylinder pressure calculated over defined number of combustion cycles for engine cylinder 4.  Negative range is to cover thermodynamic behavior during misfire.";
CM_ BO_ 2498777342 "Engine Cylinder 3 Combustion Average Information
Used to transmit the average of combustion parameters of Engine Cylinder 3.
This PGN is transmitted at a defined ratio of the engine speed. The transmission rate is dependent on
SPN 6394 - Number ...";
CM_ SG_ 2498777342 EngCyl3AverageCombustionDuration "Average duration of combustion calculated over defined number of combustion cycles for engine cylinder 3 with reference to the crank angle.  Combustion duration is the difference between end of combustion and start of combustion expressed, in this ...";
CM_ SG_ 2498777342 EngCyl3AvrgCntrOfCmbustionTiming "Average timing calculated over defined number of combustion cycles for the center of combustion in engine cylinder 3 with reference to the crank angle.  Center of Combustion is used to indicate the combustion efficiency.  When the combustion happens ...";
CM_ SG_ 2498777342 EngCyl3AvrgStrtOfCmbustionTiming "Average start of combustion timing calculated over defined number of combustion cycles for engine cylinder 3 with reference to the crank angle.  When the combustion happens after the TDC (Top Dead Center) of this cylinder, the timing is referred in ...";
CM_ SG_ 2498777342 EngCyl3IndctedMeanEffectivePress "Average cylinder pressure calculated over defined number of combustion cycles for engine cylinder 3.  Negative range is to cover thermodynamic behavior during misfire.";
CM_ BO_ 2566768382 "Cold Start Aids
Cold start aid information and settings.";
CM_ SG_ 2566768382 EngCldStrtFlIgniterRelayFeedback "Feedback state of the engine cold start fuel igniter relay which indicates the status of the relay output.

00  Off
01  On
10  Error
11  Not available";
CM_ SG_ 2566768382 EngColdStartFuelIgniterRelay "The engine cold start fuel igniter relay control command.  This command controls the relay, not the igniter.

00  Off
01  On
10  Reserved
11  Don't care/take no action";
CM_ SG_ 2566768382 EngColdStartFuelIgniterCmd "The engine cold start fuel igniter control command, normalized to %, where 0% represents fully off and 100% represents fully on.";
CM_ SG_ 2566768382 EngStartEnableDevice2Config "The start enable device installed for start enable device 2.
0000 - no start enable device 2 installed
0001 - glow plugs installed
0010 - fuelled start installed
0011 - ether injection installed
0100 - electric intake air heater installed
0101 ...";
CM_ SG_ 2566768382 EngStartEnableDevice1Config "The start enable device installed for start enable device 1.
0000 - no start enable device 1 installed
0001 - glow plugs installed
0010 - fuelled start installed
0011 - ether injection installed
0100 - electric intake air heater installed
0101 ...";
CM_ SG_ 2566768382 EngStartEnableDevice2 "Devices that assist an engine in starting, e.g. intake heaters, ether, or an alternate/secondary starting aid.  May be of the same type or different than Start Enable Device 1 (SPN 626). Parameter indicating whether the start enable device 2 is ON ...";
CM_ SG_ 2566768382 EngStartEnableDevice1 "Devices that assist an Engine in starting, e.g. intake heaters and ether.  Primary starting aid.
Parameter indicating whether the start enable device 1 is ON or OFF

00 - start enable OFF
01 - start enable ON
10 - reserved
11 - not available";
CM_ BO_ 2566811902 "Combination Vehicle Weight";
CM_ SG_ 2566811902 PoweredVehicleWeight "Total mass imposed by the tires of the powered vehicle on the road surface.  Does not include the trailer.";
CM_ SG_ 2566811902 GrossCombinationVehicleWeight "The total weight of the truck and all attached trailers.";
CM_ BO_ 2563768062 "Continuous Torque & Speed Limit Request";
CM_ SG_ 2563768062 MxCntinuousRetarderTorqueLimitRq "Requested maximum continuous retarder torque (operating range: -125 to 0%)";
CM_ SG_ 2563768062 MnCntinuousRetarderTorqueLimitRq "Requested minimum continuous retarder torque (operating range: -125 to 0%)";
CM_ SG_ 2563768062 MxContinuousRetarderSpeedLimitRq "Requested maximum continuous retarder speed";
CM_ SG_ 2563768062 MnContinuousRetarderSpeedLimitRq "Requested minimum continuous retarder speed";
CM_ SG_ 2563768062 EngTorqueLimitRqMaxContinuous "Requested maximum continuous engine torque (operating range: 0 to 125%)";
CM_ SG_ 2563768062 EngTorqueLimitRqMinContinuous "Requested minimum continuous engine torque (operating range: 0 to 125%)";
CM_ SG_ 2563768062 EngSpeedLimitRqMaxContinuous "Requested maximum continuous engine speed";
CM_ SG_ 2563768062 EngSpeedLimitRqMinContinuous "Requested minimum continuous engine speed";
CM_ BO_ 2633924862 "Combustion Time 6";
CM_ SG_ 2633924862 EngAverageCombustionTime "The average combustion time of all cylinders of an engine.";
CM_ SG_ 2633924862 EngDesiredCombustionTime "The desired combustion time based upon engine load and speed lookup maps.";
CM_ BO_ 2633924606 "Combustion Time 5";
CM_ SG_ 2633924606 EngCyl20CombustionTime "The amount of time from when the ignition of the fuel is initiated to when the fuel is completely ignited (i.e., the flame front has propagated across the cylinder).";
CM_ SG_ 2633924606 EngCyl19CombustionTime "The amount of time from when the ignition of the fuel is initiated to when the fuel is completely ignited (i.e., the flame front has propagated across the cylinder).";
CM_ SG_ 2633924606 EngCyl18CombustionTime "The amount of time from when the ignition of the fuel is initiated to when the fuel is completely ignited (i.e., the flame front has propagated across the cylinder).";
CM_ SG_ 2633924606 EngCyl17CombustionTime "The amount of time from when the ignition of the fuel is initiated to when the fuel is completely ignited (i.e., the flame front has propagated across the cylinder).";
CM_ BO_ 2633924350 "Combustion Time 4";
CM_ SG_ 2633924350 EngCyl16CombustionTime "The amount of time from when the ignition of the fuel is initiated to when the fuel is completely ignited (i.e., the flame front has propagated across the cylinder).";
CM_ SG_ 2633924350 EngCyl15CombustionTime "The amount of time from when the ignition of the fuel is initiated to when the fuel is completely ignited (i.e., the flame front has propagated across the cylinder).";
CM_ SG_ 2633924350 EngCyl14CombustionTime "The amount of time from when the ignition of the fuel is initiated to when the fuel is completely ignited (i.e., the flame front has propagated across the cylinder).";
CM_ SG_ 2633924350 EngCyl13CombustionTime "The amount of time from when the ignition of the fuel is initiated to when the fuel is completely ignited (i.e., the flame front has propagated across the cylinder).";
CM_ BO_ 2633924094 "Combustion Time 3";
CM_ SG_ 2633924094 EngCyl12CombustionTime "The amount of time from when the ignition of the fuel is initiated to when the fuel is completely ignited (i.e., the flame front has propagated across the cylinder).";
CM_ SG_ 2633924094 EngCyl11CombustionTime "The amount of time from when the ignition of the fuel is initiated to when the fuel is completely ignited (i.e., the flame front has propagated across the cylinder).";
CM_ SG_ 2633924094 EngCyl10CombustionTime "The amount of time from when the ignition of the fuel is initiated to when the fuel is completely ignited (i.e., the flame front has propagated across the cylinder).";
CM_ SG_ 2633924094 EngCyl9CombustionTime "The amount of time from when the ignition of the fuel is initiated to when the fuel is completely ignited (i.e., the flame front has propagated across the cylinder).";
CM_ BO_ 2633923838 "Combustion Time 2";
CM_ SG_ 2633923838 EngCyl8CombustionTime "The amount of time from when the ignition of the fuel is initiated to when the fuel is completely ignited (i.e., the flame front has propagated across the cylinder).";
CM_ SG_ 2633923838 EngCyl7CombustionTime "The amount of time from when the ignition of the fuel is initiated to when the fuel is completely ignited (i.e., the flame front has propagated across the cylinder).";
CM_ SG_ 2633923838 EngCyl6CombustionTime "The amount of time from when the ignition of the fuel is initiated to when the fuel is completely ignited (i.e., the flame front has propagated across the cylinder).";
CM_ SG_ 2633923838 EngCyl5CombustionTime "The amount of time from when the ignition of the fuel is initiated to when the fuel is completely ignited (i.e., the flame front has propagated across the cylinder).";
CM_ BO_ 2633923582 "Combustion Time 1";
CM_ SG_ 2633923582 EngCyl4CombustionTime "The amount of time from when the ignition of the fuel is initiated to when the fuel is completely ignited (i.e., the flame front has propagated across the cylinder).";
CM_ SG_ 2633923582 EngCyl3CombustionTime "The amount of time from when the ignition of the fuel is initiated to when the fuel is completely ignited (i.e., the flame front has propagated across the cylinder).";
CM_ SG_ 2633923582 EngCyl2CombustionTime "The amount of time from when the ignition of the fuel is initiated to when the fuel is completely ignited (i.e., the flame front has propagated across the cylinder).";
CM_ SG_ 2633923582 EngCyl1CombustionTime "The amount of time from when the ignition of the fuel is initiated to when the fuel is completely ignited (i.e., the flame front has propagated across the cylinder).";
CM_ BO_ 2633878014 "Electronic Control Module Information
Information relating to electronic control modules";
CM_ SG_ 2633878014 TotalCountOfConfigChangesMade "Total number of times changes have been made to any of the configurable parameters.";
CM_ BO_ 2566771966 "Cab Message 3
Provides information from Cab mounted operator inputs.";
CM_ SG_ 2566771966 AFTDEFDosingModeCmd "Request the aftertreatment system to run in standard or reduced mode.
Standard indicates that the system will dose at higher capacity where the reduced mode will dose at a lower capacity.  (e.g., IMO 3 to IMO 2 in Marine Applications)
000 = ...";
CM_ SG_ 2566771966 VehTrailerStatus "Indicates a trailer is connected to the towing mechanism.  This is not intended to indicate that the trailer is latched.

00 - Trailer is not detected
01 - Trailer is detected
10 - Error
11 - Not available";
CM_ SG_ 2566771966 TransOilLevelRq "Conveys operator or vehicle system desire for a transmission oil level reading to be taken. 

00 - No transmission oil level reading desired
01 - Transmission oil level reading desired
10 - Reserved
11 - Don't care / take no action";
CM_ SG_ 2566771966 FifthWheelReleaseCtrl "Operator input used to release the fifth wheel. Fifth Wheel Release Control Security Lockout and other conditions must be properly enabled before this will function.
00   Coupler Locked
01   Coupler Unlocked, trailer can be unhitched or hitched
 ...";
CM_ SG_ 2566771966 FfthWhlRleaseCtrlSecurityLockout "Operator's fifth wheel release control interlock. This operator input must be enabled prior to activating the fifth wheel release control (SPN 3314).
00    Fifth wheel release Disabled
01    Fifth wheel release Enabled
10    Error
11    Not ...";
CM_ SG_ 2566771966 TransferCaseSelectorSwitch "Operator switch to select the condition of the transfer case.  States 000 and 001 should be used if the transfer case only functions to switch between 2-wheel and 4-wheel drive.  If the transfer case includes a High / Low Range function, states 011 ...";
BA_DEF_ SG_  "SigType" ENUM  "Default","Range","RangeSigned","ASCII","Discrete","Control","ReferencePGN","DTC","StringDelimiter","StringLength","StringLengthControl","MessageCounter","MessageChecksum";
BA_DEF_ SG_  "GenSigStartValue" INT 0 2147483647;
BA_DEF_ SG_  "GenSigSendType" ENUM  "Cyclic","OnWrite","OnWriteWithRepetition","OnChange","OnChangeWithRepetition","IfActive","IfActiveWithRepetition","NoSigSendType";
BA_DEF_ SG_  "GenSigILSupport" ENUM  "No","Yes";
BA_DEF_ SG_  "GenSigEVName" STRING ;
BA_DEF_ SG_  "SPN" INT 0 524287;
BA_DEF_ BO_  "TpJ1939VarDlc" ENUM  "No","Yes";
BA_DEF_ BO_  "GenMsgStartDelayTime" INT 0 100000;
BA_DEF_ BO_  "GenMsgILSupport" ENUM  "No","Yes";
BA_DEF_ BO_  "GenMsgDelayTime" INT 0 1000;
BA_DEF_ BO_  "GenMsgRequestable" INT 0 1;
BA_DEF_ BO_  "GenMsgSendType" ENUM  "cyclic","NotUsed","NotUsed","NotUsed","NotUsed","NotUsed","NotUsed","IfActive","noMsgSendType";
BA_DEF_ BO_  "VFrameFormat" ENUM  "StandardCAN","ExtendedCAN","reserved","J1939PG";
BA_DEF_ BO_  "GenMsgCycleTime" INT 0 3600000;
BA_DEF_ SG_  "SystemSignalLongSymbol" STRING ;
BA_DEF_DEF_  "SigType" "Default";
BA_DEF_DEF_  "GenSigStartValue" 0;
BA_DEF_DEF_  "GenSigSendType" "NoSigSendType";
BA_DEF_DEF_  "GenSigILSupport" "Yes";
BA_DEF_DEF_  "GenSigEVName" "Env@Nodename_@Signame";
BA_DEF_DEF_  "SPN" 0;
BA_DEF_DEF_  "TpJ1939VarDlc" "No";
BA_DEF_DEF_  "GenMsgStartDelayTime" 0;
BA_DEF_DEF_  "GenMsgILSupport" "Yes";
BA_DEF_DEF_  "GenMsgDelayTime" 0;
BA_DEF_DEF_  "GenMsgRequestable" 1;
BA_DEF_DEF_  "GenMsgSendType" "noMsgSendType";
BA_DEF_DEF_  "VFrameFormat" "J1939PG";
BA_DEF_DEF_  "GenMsgCycleTime" 0;
BA_DEF_DEF_  "SystemSignalLongSymbol" "";
BA_ "GenMsgCycleTime" BO_ 2565868542 20;
BA_ "GenMsgSendType" BO_ 2565868542 0;
BA_ "GenMsgCycleTime" BO_ 2633941758 1000;
BA_ "GenMsgSendType" BO_ 2633941758 0;
BA_ "GenMsgDelayTime" BO_ 2633941758 100;
BA_ "GenMsgCycleTime" BO_ 2565865726 100;
BA_ "GenMsgSendType" BO_ 2565865726 0;
BA_ "GenMsgCycleTime" BO_ 2633932798 1000;
BA_ "GenMsgSendType" BO_ 2633932798 0;
BA_ "GenMsgCycleTime" BO_ 2566824190 1000;
BA_ "GenMsgSendType" BO_ 2566824190 0;
BA_ "GenMsgCycleTime" BO_ 2633933310 1000;
BA_ "GenMsgSendType" BO_ 2633933310 0;
BA_ "GenMsgCycleTime" BO_ 2633933566 1000;
BA_ "GenMsgSendType" BO_ 2633933566 0;
BA_ "GenMsgCycleTime" BO_ 2633933822 1000;
BA_ "GenMsgSendType" BO_ 2633933822 0;
BA_ "GenMsgCycleTime" BO_ 2566776062 500;
BA_ "GenMsgSendType" BO_ 2566776062 0;
BA_ "GenMsgCycleTime" BO_ 2566775806 250;
BA_ "GenMsgSendType" BO_ 2566775806 0;
BA_ "GenMsgCycleTime" BO_ 2365447166 100;
BA_ "GenMsgSendType" BO_ 2365447166 0;
BA_ "GenMsgDelayTime" BO_ 2365447166 20;
BA_ "GenMsgCycleTime" BO_ 2365446654 100;
BA_ "GenMsgSendType" BO_ 2365446654 0;
BA_ "GenMsgDelayTime" BO_ 2365446654 20;
BA_ "GenMsgCycleTime" BO_ 2365446142 100;
BA_ "GenMsgSendType" BO_ 2365446142 0;
BA_ "GenMsgDelayTime" BO_ 2365446142 20;
BA_ "GenMsgCycleTime" BO_ 2633929470 100;
BA_ "GenMsgSendType" BO_ 2633929470 0;
BA_ "GenMsgCycleTime" BO_ 2364541694 50;
BA_ "GenMsgSendType" BO_ 2364541694 0;
BA_ "GenMsgCycleTime" BO_ 2566810366 5000;
BA_ "GenMsgSendType" BO_ 2566810366 0;
BA_ "GenMsgCycleTime" BO_ 2566767102 500;
BA_ "GenMsgSendType" BO_ 2566767102 0;
BA_ "GenMsgCycleTime" BO_ 2566839294 5000;
BA_ "GenMsgSendType" BO_ 2566839294 0;
BA_ "GenMsgCycleTime" BO_ 2566844414 5000;
BA_ "GenMsgSendType" BO_ 2566844414 0;
BA_ "GenMsgCycleTime" BO_ 2633929726 100;
BA_ "GenMsgSendType" BO_ 2633929726 0;
BA_ "GenMsgCycleTime" BO_ 2566840318 250;
BA_ "GenMsgSendType" BO_ 2566840318 0;
BA_ "GenMsgCycleTime" BO_ 2364539902 50;
BA_ "GenMsgSendType" BO_ 2364539902 0;
BA_ "GenMsgCycleTime" BO_ 2364540158 50;
BA_ "GenMsgSendType" BO_ 2364540158 0;
BA_ "TpJ1939VarDlc" BO_ 2566768126 1;
BA_ "GenMsgCycleTime" BO_ 2566804734 5000;
BA_ "GenMsgSendType" BO_ 2566804734 0;
BA_ "GenMsgCycleTime" BO_ 2566841342 5000;
BA_ "GenMsgSendType" BO_ 2566841342 0;
BA_ "GenMsgDelayTime" BO_ 2566841342 500;
BA_ "GenMsgCycleTime" BO_ 2566767870 100;
BA_ "GenMsgSendType" BO_ 2566767870 0;
BA_ "GenMsgCycleTime" BO_ 2566827518 100;
BA_ "GenMsgSendType" BO_ 2566827518 0;
BA_ "GenMsgCycleTime" BO_ 2566832126 100;
BA_ "GenMsgSendType" BO_ 2566832126 0;
BA_ "GenMsgCycleTime" BO_ 2565865982 100;
BA_ "GenMsgSendType" BO_ 2565865982 0;
BA_ "GenMsgCycleTime" BO_ 2565867262 500;
BA_ "GenMsgSendType" BO_ 2565867262 0;
BA_ "GenMsgCycleTime" BO_ 2566821118 5000;
BA_ "GenMsgSendType" BO_ 2566821118 0;
BA_ "TpJ1939VarDlc" BO_ 2566810622 1;
BA_ "GenMsgCycleTime" BO_ 2566847742 1000;
BA_ "GenMsgSendType" BO_ 2566847742 0;
BA_ "GenMsgCycleTime" BO_ 2563768062 5000;
BA_ "GenMsgSendType" BO_ 2563768062 0;
BA_ "GenMsgCycleTime" BO_ 2566771966 10000;
BA_ "GenMsgSendType" BO_ 2566771966 0;
BA_ "GenMsgDelayTime" BO_ 2566771966 100;
BA_ "SPN" SG_ 2565868542 TypeOfSteerTrans 2926;
BA_ "SPN" SG_ 2565868542 TypeOfSteerForces 2925;
BA_ "SPN" SG_ 2565868542 SteerType 2924;
BA_ "SPN" SG_ 2565868542 SteerableLiftAxleLoweringInhibit 2922;
BA_ "SigType" SG_ 2565868542 SteerableLiftAxleLoweringInhibit 5;
BA_ "SPN" SG_ 2565868542 StatusOfSteerAxle 2923;
BA_ "SPN" SG_ 2565868542 AxleLocation 2928;
BA_ "SPN" SG_ 2565868542 ActualInnerWheelSteerAngle 2927;
BA_ "SigType" SG_ 2565868542 ActualInnerWheelSteerAngle 1;
BA_ "SPN" SG_ 2633941758 CrsCtrlRetarderActiveSpeedOffset 7496;
BA_ "GenSigStartValue" SG_ 2633941758 CrsCtrlRetarderActiveSpeedOffset 32000;
BA_ "SigType" SG_ 2633941758 CrsCtrlRetarderActiveSpeedOffset 1;
BA_ "SPN" SG_ 2633941758 TransOutputRetarder 748;
BA_ "SigType" SG_ 2633941758 TransOutputRetarder 5;
BA_ "SPN" SG_ 2565865726 ActlMxAvlblRetarderPercentTorque 1717;
BA_ "SigType" SG_ 2565865726 ActlMxAvlblRetarderPercentTorque 1;
BA_ "SPN" SG_ 2565865726 RetarderSelectionNonengine 1716;
BA_ "SigType" SG_ 2565865726 RetarderSelectionNonengine 1;
BA_ "SPN" SG_ 2565865726 DrvrsDemandRetarderPercentTorque 1715;
BA_ "SigType" SG_ 2565865726 DrvrsDemandRetarderPercentTorque 1;
BA_ "SPN" SG_ 2565865726 SrcAddrssOfCntrllngDvcFrRtrdrCtr 1480;
BA_ "SPN" SG_ 2565865726 RetarderRoadSpeedExceededStatus 4234;
BA_ "SigType" SG_ 2565865726 RetarderRoadSpeedExceededStatus 5;
BA_ "SPN" SG_ 2565865726 RetarderRoadSpeedLimitSwitch 4233;
BA_ "SigType" SG_ 2565865726 RetarderRoadSpeedLimitSwitch 4;
BA_ "SPN" SG_ 2565865726 RetarderRequestingBrakeLight 1667;
BA_ "SigType" SG_ 2565865726 RetarderRequestingBrakeLight 5;
BA_ "SPN" SG_ 2565865726 EngCoolantLoadIncrease 1082;
BA_ "SigType" SG_ 2565865726 EngCoolantLoadIncrease 5;
BA_ "SPN" SG_ 2565865726 IntendedRetarderPercentTorque 1085;
BA_ "SigType" SG_ 2565865726 IntendedRetarderPercentTorque 1;
BA_ "SPN" SG_ 2565865726 ActualRetarderPercentTorque 520;
BA_ "SigType" SG_ 2565865726 ActualRetarderPercentTorque 1;
BA_ "SPN" SG_ 2565865726 RetarderEnableShiftAssistSwitch 572;
BA_ "SigType" SG_ 2565865726 RetarderEnableShiftAssistSwitch 4;
BA_ "SPN" SG_ 2565865726 RetarderEnableBrakeAssistSwitch 571;
BA_ "SigType" SG_ 2565865726 RetarderEnableBrakeAssistSwitch 4;
BA_ "SPN" SG_ 2565865726 RetarderTorqueMode 900;
BA_ "SPN" SG_ 2633932798 EngExhaustGasPort20Temp 1156;
BA_ "SigType" SG_ 2633932798 EngExhaustGasPort20Temp 1;
BA_ "SPN" SG_ 2633932798 EngExhaustGasPort19Temp 1155;
BA_ "SigType" SG_ 2633932798 EngExhaustGasPort19Temp 1;
BA_ "SPN" SG_ 2633932798 EngExhaustGasPort18Temp 1154;
BA_ "SigType" SG_ 2633932798 EngExhaustGasPort18Temp 1;
BA_ "SPN" SG_ 2633932798 EngExhaustGasPort17Temp 1153;
BA_ "SigType" SG_ 2633932798 EngExhaustGasPort17Temp 1;
BA_ "SPN" SG_ 2566824190 EngExhaustGasPort16Temp 1152;
BA_ "SigType" SG_ 2566824190 EngExhaustGasPort16Temp 1;
BA_ "SPN" SG_ 2566824190 EngExhaustGasPort15Temp 1151;
BA_ "SigType" SG_ 2566824190 EngExhaustGasPort15Temp 1;
BA_ "SPN" SG_ 2566824190 EngExhaustGasPort14Temp 1150;
BA_ "SigType" SG_ 2566824190 EngExhaustGasPort14Temp 1;
BA_ "SPN" SG_ 2566824190 EngExhaustGasPort13Temp 1149;
BA_ "SigType" SG_ 2566824190 EngExhaustGasPort13Temp 1;
BA_ "SPN" SG_ 2633933310 EngExhaustGasPort12Temp 1148;
BA_ "SigType" SG_ 2633933310 EngExhaustGasPort12Temp 1;
BA_ "SPN" SG_ 2633933310 EngExhaustGasPort11Temp 1147;
BA_ "SigType" SG_ 2633933310 EngExhaustGasPort11Temp 1;
BA_ "SPN" SG_ 2633933310 EngExhaustGasPort10Temp 1146;
BA_ "SigType" SG_ 2633933310 EngExhaustGasPort10Temp 1;
BA_ "SPN" SG_ 2633933310 EngExhaustGasPort9Temp 1145;
BA_ "SigType" SG_ 2633933310 EngExhaustGasPort9Temp 1;
BA_ "SPN" SG_ 2633933566 EngExhaustGasPort8Temp 1144;
BA_ "SigType" SG_ 2633933566 EngExhaustGasPort8Temp 1;
BA_ "SPN" SG_ 2633933566 EngExhaustGasPort7Temp 1143;
BA_ "SigType" SG_ 2633933566 EngExhaustGasPort7Temp 1;
BA_ "SPN" SG_ 2633933566 EngExhaustGasPort6Temp 1142;
BA_ "SigType" SG_ 2633933566 EngExhaustGasPort6Temp 1;
BA_ "SPN" SG_ 2633933566 EngExhaustGasPort5Temp 1141;
BA_ "SigType" SG_ 2633933566 EngExhaustGasPort5Temp 1;
BA_ "SPN" SG_ 2633933822 EngExhaustGasPort4Temp 1140;
BA_ "SigType" SG_ 2633933822 EngExhaustGasPort4Temp 1;
BA_ "SPN" SG_ 2633933822 EngExhaustGasPort3Temp 1139;
BA_ "SigType" SG_ 2633933822 EngExhaustGasPort3Temp 1;
BA_ "SPN" SG_ 2633933822 EngExhaustGasPort2Temp 1138;
BA_ "SigType" SG_ 2633933822 EngExhaustGasPort2Temp 1;
BA_ "SPN" SG_ 2633933822 EngExhaustGasPort1Temp 1137;
BA_ "SigType" SG_ 2633933822 EngExhaustGasPort1Temp 1;
BA_ "SPN" SG_ 2566776062 PayloadCapacityPercentage 6854;
BA_ "SigType" SG_ 2566776062 PayloadCapacityPercentage 1;
BA_ "SPN" SG_ 2566776062 PayloadCarryBackWeight 6853;
BA_ "SigType" SG_ 2566776062 PayloadCarryBackWeight 1;
BA_ "SPN" SG_ 2566776062 PayloadWeightConfidence 6852;
BA_ "SigType" SG_ 2566776062 PayloadWeightConfidence 1;
BA_ "SPN" SG_ 2566776062 PayloadWeight 6851;
BA_ "SPN" SG_ 2566776062 PayloadPercentage 2600;
BA_ "SigType" SG_ 2566776062 PayloadPercentage 1;
BA_ "SPN" SG_ 2566771454 DataMemoryUsage 2802;
BA_ "SigType" SG_ 2566771454 DataMemoryUsage 1;
BA_ "SPN" SG_ 2566771454 KeepAliveBatteryConsumption 2803;
BA_ "SigType" SG_ 2566771454 KeepAliveBatteryConsumption 1;
BA_ "SPN" SG_ 2566775806 TravelVelocityCtrlPos 2601;
BA_ "SigType" SG_ 2566775806 TravelVelocityCtrlPos 1;
BA_ "SPN" SG_ 2633935358 EngExhstGsOxygnSnsrClsdLpOprtion 1696;
BA_ "SigType" SG_ 2633935358 EngExhstGsOxygnSnsrClsdLpOprtion 5;
BA_ "SPN" SG_ 2633935358 EngExhstGsOxygnSnsrFlngCrrection 1695;
BA_ "SigType" SG_ 2633935358 EngExhstGsOxygnSnsrFlngCrrection 1;
BA_ "SPN" SG_ 2633935358 EngActualExhaustOxygen 1119;
BA_ "SigType" SG_ 2633935358 EngActualExhaustOxygen 1;
BA_ "SPN" SG_ 2633935358 EngDesiredExhaustOxygen 1118;
BA_ "SigType" SG_ 2633935358 EngDesiredExhaustOxygen 1;
BA_ "SPN" SG_ 2633935358 EngDesiredRatedExhaustOxygen 1117;
BA_ "SigType" SG_ 2633935358 EngDesiredRatedExhaustOxygen 1;
BA_ "SPN" SG_ 2365447166 Joystick3Button13PressedStatus 6739;
BA_ "SigType" SG_ 2365447166 Joystick3Button13PressedStatus 4;
BA_ "SPN" SG_ 2365447166 Joystick3Button14PressedStatus 6740;
BA_ "SigType" SG_ 2365447166 Joystick3Button14PressedStatus 4;
BA_ "SPN" SG_ 2365447166 Joystick3Button15PressedStatus 6741;
BA_ "SigType" SG_ 2365447166 Joystick3Button15PressedStatus 4;
BA_ "SPN" SG_ 2365447166 Joystick3Button16PressedStatus 6742;
BA_ "SigType" SG_ 2365447166 Joystick3Button16PressedStatus 4;
BA_ "SPN" SG_ 2365447166 Jystick3GripXAxisDetentPosStatus 2756;
BA_ "SigType" SG_ 2365447166 Jystick3GripXAxisDetentPosStatus 4;
BA_ "SPN" SG_ 2365447166 Jystick3GripYAxisDetentPosStatus 2757;
BA_ "SigType" SG_ 2365447166 Jystick3GripYAxisDetentPosStatus 4;
BA_ "SPN" SG_ 2365447166 Jystick3ThetaAxisDetentPosStatus 2758;
BA_ "SigType" SG_ 2365447166 Jystick3ThetaAxisDetentPosStatus 4;
BA_ "SPN" SG_ 2365447166 Joystick3ThetaAxisPos 2738;
BA_ "SPN" SG_ 2365447166 Jystck3ThtAxsClckwsPstvPosStatus 2743;
BA_ "SigType" SG_ 2365447166 Jystck3ThtAxsClckwsPstvPosStatus 4;
BA_ "SPN" SG_ 2365447166 Jystck3ThetaAxisNeutralPosStatus 2753;
BA_ "SigType" SG_ 2365447166 Jystck3ThetaAxisNeutralPosStatus 4;
BA_ "SPN" SG_ 2365447166 Joystick3GripYAxisPos 2737;
BA_ "SPN" SG_ 2365447166 Jystck3GrpYAxsLvrFrwrdPstvPsStts 2742;
BA_ "SigType" SG_ 2365447166 Jystck3GrpYAxsLvrFrwrdPstvPsStts 4;
BA_ "SPN" SG_ 2365447166 Jystck3GrpYAxsLvrBckNgtvPsStatus 2747;
BA_ "SigType" SG_ 2365447166 Jystck3GrpYAxsLvrBckNgtvPsStatus 4;
BA_ "SPN" SG_ 2365447166 Jystck3GripYAxisNeutralPosStatus 2752;
BA_ "SigType" SG_ 2365447166 Jystck3GripYAxisNeutralPosStatus 4;
BA_ "SPN" SG_ 2365447166 Joystick3GripXAxisPos 2736;
BA_ "SPN" SG_ 2365447166 Jystck3GrpXAxsLvrRghtPstvPsSttus 2741;
BA_ "SigType" SG_ 2365447166 Jystck3GrpXAxsLvrRghtPstvPsSttus 4;
BA_ "SPN" SG_ 2365447166 Jystck3GrpXAxsLvrLftNgtvPsStatus 2746;
BA_ "SigType" SG_ 2365447166 Jystck3GrpXAxsLvrLftNgtvPsStatus 4;
BA_ "SPN" SG_ 2365447166 Jystck3GripXAxisNeutralPosStatus 2751;
BA_ "SigType" SG_ 2365447166 Jystck3GripXAxisNeutralPosStatus 4;
BA_ "SPN" SG_ 2365447166 Jystck3ThtAxsCntrClckwsNgtvPsStt 2748;
BA_ "SigType" SG_ 2365447166 Jystck3ThtAxsCntrClckwsNgtvPsStt 4;
BA_ "SPN" SG_ 2365446654 Joystick2Button13PressedStatus 6735;
BA_ "SigType" SG_ 2365446654 Joystick2Button13PressedStatus 4;
BA_ "SPN" SG_ 2365446654 Joystick2Button14PressedStatus 6736;
BA_ "SigType" SG_ 2365446654 Joystick2Button14PressedStatus 4;
BA_ "SPN" SG_ 2365446654 Joystick2Button15PressedStatus 6737;
BA_ "SigType" SG_ 2365446654 Joystick2Button15PressedStatus 4;
BA_ "SPN" SG_ 2365446654 Joystick2Button16PressedStatus 6738;
BA_ "SigType" SG_ 2365446654 Joystick2Button16PressedStatus 4;
BA_ "SPN" SG_ 2365446654 Jystick2GripXAxisDetentPosStatus 2719;
BA_ "SigType" SG_ 2365446654 Jystick2GripXAxisDetentPosStatus 4;
BA_ "SPN" SG_ 2365446654 Jystick2GripYAxisDetentPosStatus 2720;
BA_ "SigType" SG_ 2365446654 Jystick2GripYAxisDetentPosStatus 4;
BA_ "SPN" SG_ 2365446654 Jystick2ThetaAxisDetentPosStatus 2721;
BA_ "SigType" SG_ 2365446654 Jystick2ThetaAxisDetentPosStatus 4;
BA_ "SPN" SG_ 2365446654 Joystick2ThetaAxisPos 2701;
BA_ "SPN" SG_ 2365446654 Jystck2ThtAxsClckwsPstvPosStatus 2706;
BA_ "SigType" SG_ 2365446654 Jystck2ThtAxsClckwsPstvPosStatus 4;
BA_ "SPN" SG_ 2365446654 Jystck2ThetaAxisNeutralPosStatus 2716;
BA_ "SigType" SG_ 2365446654 Jystck2ThetaAxisNeutralPosStatus 4;
BA_ "SPN" SG_ 2365446654 Joystick2GripYAxisPos 2700;
BA_ "SPN" SG_ 2365446654 Jystck2GrpYAxsLvrFrwrdPstvPsStts 2705;
BA_ "SigType" SG_ 2365446654 Jystck2GrpYAxsLvrFrwrdPstvPsStts 4;
BA_ "SPN" SG_ 2365446654 Jystck2GrpYAxsLvrBckNgtvPsStatus 2710;
BA_ "SigType" SG_ 2365446654 Jystck2GrpYAxsLvrBckNgtvPsStatus 4;
BA_ "SPN" SG_ 2365446654 Jystck2GripYAxisNeutralPosStatus 2715;
BA_ "SigType" SG_ 2365446654 Jystck2GripYAxisNeutralPosStatus 4;
BA_ "SPN" SG_ 2365446654 Joystick2GripXAxisPos 2699;
BA_ "SPN" SG_ 2365446654 Jystck2GrpXAxsLvrRghtPstvPsSttus 2704;
BA_ "SigType" SG_ 2365446654 Jystck2GrpXAxsLvrRghtPstvPsSttus 4;
BA_ "SPN" SG_ 2365446654 Jystck2GrpXAxsLvrLftNgtvPsStatus 2709;
BA_ "SigType" SG_ 2365446654 Jystck2GrpXAxsLvrLftNgtvPsStatus 4;
BA_ "SPN" SG_ 2365446654 Jystck2GripXAxisNeutralPosStatus 2714;
BA_ "SigType" SG_ 2365446654 Jystck2GripXAxisNeutralPosStatus 4;
BA_ "SPN" SG_ 2365446654 Jystck2ThtAxsCntrClckwsNgtvPsStt 2711;
BA_ "SigType" SG_ 2365446654 Jystck2ThtAxsCntrClckwsNgtvPsStt 4;
BA_ "SPN" SG_ 2365446142 Joystick1Button13PressedStatus 6731;
BA_ "SigType" SG_ 2365446142 Joystick1Button13PressedStatus 4;
BA_ "SPN" SG_ 2365446142 Joystick1Button14PressedStatus 6732;
BA_ "SigType" SG_ 2365446142 Joystick1Button14PressedStatus 4;
BA_ "SPN" SG_ 2365446142 Joystick1Button15PressedStatus 6733;
BA_ "SigType" SG_ 2365446142 Joystick1Button15PressedStatus 4;
BA_ "SPN" SG_ 2365446142 Joystick1Button16PressedStatus 6734;
BA_ "SigType" SG_ 2365446142 Joystick1Button16PressedStatus 4;
BA_ "SPN" SG_ 2365446142 Jystick1GripXAxisDetentPosStatus 2682;
BA_ "SigType" SG_ 2365446142 Jystick1GripXAxisDetentPosStatus 4;
BA_ "SPN" SG_ 2365446142 Jystick1GripYAxisDetentPosStatus 2683;
BA_ "SigType" SG_ 2365446142 Jystick1GripYAxisDetentPosStatus 4;
BA_ "SPN" SG_ 2365446142 Jystick1ThetaAxisDetentPosStatus 2684;
BA_ "SigType" SG_ 2365446142 Jystick1ThetaAxisDetentPosStatus 4;
BA_ "SPN" SG_ 2365446142 Joystick1ThetaAxisPos 2664;
BA_ "SPN" SG_ 2365446142 Jystck1ThtAxsClckwsPstvPosStatus 2669;
BA_ "SigType" SG_ 2365446142 Jystck1ThtAxsClckwsPstvPosStatus 4;
BA_ "SPN" SG_ 2365446142 Jystck1ThetaAxisNeutralPosStatus 2679;
BA_ "SigType" SG_ 2365446142 Jystck1ThetaAxisNeutralPosStatus 4;
BA_ "SPN" SG_ 2365446142 Joystick1GripYAxisPos 2663;
BA_ "SPN" SG_ 2365446142 Jystck1GrpYAxsLvrFrwrdPstvPsStts 2668;
BA_ "SigType" SG_ 2365446142 Jystck1GrpYAxsLvrFrwrdPstvPsStts 4;
BA_ "SPN" SG_ 2365446142 Jystck1GrpYAxsLvrBckNgtvPsStatus 2673;
BA_ "SigType" SG_ 2365446142 Jystck1GrpYAxsLvrBckNgtvPsStatus 4;
BA_ "SPN" SG_ 2365446142 Aftrtrtmnt1DslExhstFldPrprtsPrlm 2678;
BA_ "SigType" SG_ 2365446142 Aftrtrtmnt1DslExhstFldPrprtsPrlm 4;
BA_ "SPN" SG_ 2365446142 Joystick1GripXAxisPos 2662;
BA_ "SPN" SG_ 2365446142 Jystck1GrpXAxsLvrRghtPstvPsSttus 2667;
BA_ "SigType" SG_ 2365446142 Jystck1GrpXAxsLvrRghtPstvPsSttus 4;
BA_ "SPN" SG_ 2365446142 Jystck1GrpXAxsLvrLftNgtvPsStatus 2672;
BA_ "SigType" SG_ 2365446142 Jystck1GrpXAxsLvrLftNgtvPsStatus 4;
BA_ "SPN" SG_ 2365446142 Jystck1GripXAxisNeutralPosStatus 2677;
BA_ "SigType" SG_ 2365446142 Jystck1GripXAxisNeutralPosStatus 4;
BA_ "SPN" SG_ 2365446142 Jystck1ThtAxsCntrClckwsNgtvPsStt 2674;
BA_ "SigType" SG_ 2365446142 Jystck1ThtAxsCntrClckwsNgtvPsStt 4;
BA_ "SPN" SG_ 2633929470 EngFuelRackPos 1210;
BA_ "SigType" SG_ 2633929470 EngFuelRackPos 1;
BA_ "SPN" SG_ 2633929470 EngGasMassFlowRate1 1241;
BA_ "SigType" SG_ 2633929470 EngGasMassFlowRate1 1;
BA_ "SPN" SG_ 2633929470 InstantaneousEstBrakePower 1242;
BA_ "SigType" SG_ 2633929470 InstantaneousEstBrakePower 1;
BA_ "SPN" SG_ 2633929470 EngExhaustGasPress1 1209;
BA_ "SigType" SG_ 2633929470 EngExhaustGasPress1 1;
BA_ "SPN" SG_ 2633929470 EngPrefilterOilPress 1208;
BA_ "SigType" SG_ 2633929470 EngPrefilterOilPress 1;
BA_ "SPN" SG_ 2633937406 TotalECURunTime 1033;
BA_ "SigType" SG_ 2633937406 TotalECURunTime 1;
BA_ "SPN" SG_ 2633937406 TotalECUDistance 1032;
BA_ "SigType" SG_ 2633937406 TotalECUDistance 1;
BA_ "SPN" SG_ 2364541694 EngExhstGsRcrcltion2MassFlowRate 5257;
BA_ "SigType" SG_ 2364541694 EngExhstGsRcrcltion2MassFlowRate 1;
BA_ "SPN" SG_ 2364541694 EngIntakeAirMassFlowRate 132;
BA_ "SigType" SG_ 2364541694 EngIntakeAirMassFlowRate 1;
BA_ "SPN" SG_ 2364541694 EngExhstGsRcrcltion1MassFlowRate 2659;
BA_ "SigType" SG_ 2364541694 EngExhstGsRcrcltion1MassFlowRate 1;
BA_ "SPN" SG_ 2566810366 EngFuelSupplyPumpIntakePress 7104;
BA_ "SigType" SG_ 2566810366 EngFuelSupplyPumpIntakePress 1;
BA_ "SPN" SG_ 2566810366 FuelPumpPrimerStatus 4083;
BA_ "SigType" SG_ 2566810366 FuelPumpPrimerStatus 5;
BA_ "SPN" SG_ 2566810366 EngVentilationStatus 3554;
BA_ "SPN" SG_ 2566810366 EngCoolantPreheatedState 3553;
BA_ "SigType" SG_ 2566810366 EngCoolantPreheatedState 5;
BA_ "SPN" SG_ 2566810366 EngOilPreHeatedState 3552;
BA_ "SigType" SG_ 2566810366 EngOilPreHeatedState 5;
BA_ "SPN" SG_ 2566810366 EngOilPrimingState 3551;
BA_ "SigType" SG_ 2566810366 EngOilPrimingState 5;
BA_ "SPN" SG_ 2566810366 EngOilPrimingPumpSwitch 3550;
BA_ "SigType" SG_ 2566810366 EngOilPrimingPumpSwitch 4;
BA_ "SPN" SG_ 2566810366 EngOilFilterOutletPress 3549;
BA_ "SigType" SG_ 2566810366 EngOilFilterOutletPress 1;
BA_ "SPN" SG_ 2566810366 EngWasteOilReservoirLevel 3548;
BA_ "SigType" SG_ 2566810366 EngWasteOilReservoirLevel 1;
BA_ "SPN" SG_ 2566810366 EngFuelFilterDiffPress 1382;
BA_ "SigType" SG_ 2566810366 EngFuelFilterDiffPress 1;
BA_ "SPN" SG_ 2566810366 EngFuelSupplyPumpIntakeAbsPress 1381;
BA_ "SigType" SG_ 2566810366 EngFuelSupplyPumpIntakeAbsPress 1;
BA_ "SPN" SG_ 2566810366 EngOilLevelRemoteReservoir 1380;
BA_ "SigType" SG_ 2566810366 EngOilLevelRemoteReservoir 1;
BA_ "SPN" SG_ 2566767102 EngThrottleValve1DiffPress 5631;
BA_ "SigType" SG_ 2566767102 EngThrottleValve1DiffPress 1;
BA_ "SPN" SG_ 2566767102 EngExhstGsRcrclation1OutletPress 5019;
BA_ "SigType" SG_ 2566767102 EngExhstGsRcrclation1OutletPress 1;
BA_ "SPN" SG_ 2566767102 EngExhstVlvActtionSystemOilPress 4287;
BA_ "SigType" SG_ 2566767102 EngExhstVlvActtionSystemOilPress 1;
BA_ "SPN" SG_ 2566767102 EngExhstGsRcrclation1IntakePress 3358;
BA_ "SigType" SG_ 2566767102 EngExhstGsRcrclation1IntakePress 1;
BA_ "SPN" SG_ 2566767102 EngIntkVlvActationSystemOilPress 2948;
BA_ "SigType" SG_ 2566767102 EngIntkVlvActationSystemOilPress 1;
BA_ "SPN" SG_ 2566839294 EngInjectorMeteringRail2Press 1349;
BA_ "SigType" SG_ 2566839294 EngInjectorMeteringRail2Press 1;
BA_ "SPN" SG_ 2566839294 EngInjectorTimingRail1Press 156;
BA_ "SigType" SG_ 2566839294 EngInjectorTimingRail1Press 1;
BA_ "SPN" SG_ 2566839294 EngInjectorMeteringRail1Press 157;
BA_ "SigType" SG_ 2566839294 EngInjectorMeteringRail1Press 1;
BA_ "SPN" SG_ 2566839294 EngInjectionCtrlPress 164;
BA_ "SigType" SG_ 2566839294 EngInjectionCtrlPress 1;
BA_ "SPN" SG_ 2566844414 EngCoolantLevel 111;
BA_ "SigType" SG_ 2566844414 EngCoolantLevel 1;
BA_ "SPN" SG_ 2566844414 EngCoolantPress 109;
BA_ "SigType" SG_ 2566844414 EngCoolantPress 1;
BA_ "SPN" SG_ 2566844414 EngCrankcasePress 101;
BA_ "SigType" SG_ 2566844414 EngCrankcasePress 1;
BA_ "SPN" SG_ 2566844414 EngOilPress 100;
BA_ "SigType" SG_ 2566844414 EngOilPress 1;
BA_ "SPN" SG_ 2566844414 EngOilLevel 98;
BA_ "SigType" SG_ 2566844414 EngOilLevel 1;
BA_ "SPN" SG_ 2566844414 EngExCrankcaseBlowbyPress 22;
BA_ "SigType" SG_ 2566844414 EngExCrankcaseBlowbyPress 1;
BA_ "SPN" SG_ 2566844414 EngFuelDeliveryPress 94;
BA_ "SigType" SG_ 2566844414 EngFuelDeliveryPress 1;
BA_ "SPN" SG_ 2633929726 SafetyWireStatus 1205;
BA_ "SigType" SG_ 2633929726 SafetyWireStatus 5;
BA_ "SPN" SG_ 2633929726 ElectricalLoad 1204;
BA_ "SigType" SG_ 2633929726 ElectricalLoad 1;
BA_ "SPN" SG_ 2566772222 EngVrblGeometryTurbo1ActuatorPos 2795;
BA_ "SigType" SG_ 2566772222 EngVrblGeometryTurbo1ActuatorPos 1;
BA_ "SPN" SG_ 2566772222 EngVriableGeometryTurbo1CtrlMode 5457;
BA_ "SigType" SG_ 2566772222 EngVriableGeometryTurbo1CtrlMode 5;
BA_ "SPN" SG_ 2566772222 EngFuelCtrlCtrlMode 5323;
BA_ "SigType" SG_ 2566772222 EngFuelCtrlCtrlMode 5;
BA_ "SPN" SG_ 2566772222 EngVrblGmtryTrbArCtrlShtoffValve 2792;
BA_ "SigType" SG_ 2566772222 EngVrblGmtryTrbArCtrlShtoffValve 5;
BA_ "SPN" SG_ 2566772222 EngExhstGsRcirculation1ValveCtrl 2791;
BA_ "SigType" SG_ 2566772222 EngExhstGsRcirculation1ValveCtrl 1;
BA_ "SPN" SG_ 2566772222 EngTrb1ClclatedTurbineOutletTemp 2790;
BA_ "SigType" SG_ 2566772222 EngTrb1ClclatedTurbineOutletTemp 1;
BA_ "SPN" SG_ 2566772222 EngTrb1ClclatedTurbineIntakeTemp 2789;
BA_ "SigType" SG_ 2566772222 EngTrb1ClclatedTurbineIntakeTemp 1;
BA_ "SPN" SG_ 2633940734 PrelubeOilLowPressThreshold 8622;
BA_ "SigType" SG_ 2633940734 PrelubeOilLowPressThreshold 1;
BA_ "SPN" SG_ 2633940734 CrnkAttmptCntOnPrsntStartAttempt 3671;
BA_ "SigType" SG_ 2633940734 CrnkAttmptCntOnPrsntStartAttempt 1;
BA_ "SPN" SG_ 2633940734 EngIntakeManifoldPressCtrlMode 5465;
BA_ "SigType" SG_ 2633940734 EngIntakeManifoldPressCtrlMode 5;
BA_ "SPN" SG_ 2633940734 EngRotationDirection 3669;
BA_ "SigType" SG_ 2633940734 EngRotationDirection 4;
BA_ "SPN" SG_ 2633940734 EngRatedSpeed 189;
BA_ "SigType" SG_ 2633940734 EngRatedSpeed 1;
BA_ "SPN" SG_ 2633940734 EngRatedPower 166;
BA_ "SigType" SG_ 2633940734 EngRatedPower 1;
BA_ "SPN" SG_ 2566840318 AFT2ExhDewPoint 3240;
BA_ "SigType" SG_ 2566840318 AFT2ExhDewPoint 5;
BA_ "SPN" SG_ 2566840318 AFT2InDewPoint 3239;
BA_ "SigType" SG_ 2566840318 AFT2InDewPoint 5;
BA_ "SPN" SG_ 2566840318 AFT1ExhDewPoint 3238;
BA_ "SigType" SG_ 2566840318 AFT1ExhDewPoint 5;
BA_ "SPN" SG_ 2566840318 AFT1InDewPoint 3237;
BA_ "SigType" SG_ 2566840318 AFT1InDewPoint 5;
BA_ "SPN" SG_ 2566840318 AFT1ExhGasMFR 3236;
BA_ "SigType" SG_ 2566840318 AFT1ExhGasMFR 1;
BA_ "SPN" SG_ 2566840318 EstEngPrsiticLossesPercentTorque 2978;
BA_ "GenSigStartValue" SG_ 2566840318 EstEngPrsiticLossesPercentTorque 125;
BA_ "SigType" SG_ 2566840318 EstEngPrsiticLossesPercentTorque 1;
BA_ "SPN" SG_ 2566840318 EngnsDsrdOprtngSpdAsymmtryAdjstm 519;
BA_ "SigType" SG_ 2566840318 EngnsDsrdOprtngSpdAsymmtryAdjstm 1;
BA_ "SPN" SG_ 2566840318 EnginesDesiredOperatingSpeed 515;
BA_ "SigType" SG_ 2566840318 EnginesDesiredOperatingSpeed 1;
BA_ "SPN" SG_ 2566840318 NominalFrictionPercentTorque 514;
BA_ "SigType" SG_ 2566840318 NominalFrictionPercentTorque 1;
BA_ "SPN" SG_ 2364539902 EstPumpingPercentTorque 5398;
BA_ "SigType" SG_ 2364539902 EstPumpingPercentTorque 1;
BA_ "SPN" SG_ 2364539902 ActlMaxAvailableEngPercentTorque 3357;
BA_ "SigType" SG_ 2364539902 ActlMaxAvailableEngPercentTorque 1;
BA_ "SPN" SG_ 2364539902 SCRThermalManagementActive 5400;
BA_ "SigType" SG_ 2364539902 SCRThermalManagementActive 5;
BA_ "SPN" SG_ 2364539902 DPFThermalManagementActive 5399;
BA_ "SigType" SG_ 2364539902 DPFThermalManagementActive 5;
BA_ "SPN" SG_ 2364539902 MmntaryEngMaxPowerEnableFeedback 5021;
BA_ "SigType" SG_ 2364539902 MmntaryEngMaxPowerEnableFeedback 5;
BA_ "SPN" SG_ 2364539902 VhcleAccelerationRateLimitStatus 2979;
BA_ "SigType" SG_ 2364539902 VhcleAccelerationRateLimitStatus 5;
BA_ "SPN" SG_ 2364539902 AccelPedalPos2 29;
BA_ "SigType" SG_ 2364539902 AccelPedalPos2 1;
BA_ "SPN" SG_ 2364539902 RemoteAccelPedalPos 974;
BA_ "SigType" SG_ 2364539902 RemoteAccelPedalPos 1;
BA_ "SPN" SG_ 2364539902 EngPercentLoadAtCurrentSpeed 92;
BA_ "SigType" SG_ 2364539902 EngPercentLoadAtCurrentSpeed 1;
BA_ "SPN" SG_ 2364539902 AccelPedalPos1 91;
BA_ "SigType" SG_ 2364539902 AccelPedalPos1 1;
BA_ "SPN" SG_ 2364539902 AccelPedal2LowIdleSwitch 2970;
BA_ "SigType" SG_ 2364539902 AccelPedal2LowIdleSwitch 4;
BA_ "SPN" SG_ 2364539902 RoadSpeedLimitStatus 1437;
BA_ "SigType" SG_ 2364539902 RoadSpeedLimitStatus 5;
BA_ "SPN" SG_ 2364539902 AccelPedalKickdownSwitch 559;
BA_ "SigType" SG_ 2364539902 AccelPedalKickdownSwitch 4;
BA_ "SPN" SG_ 2364539902 AccelPedal1LowIdleSwitch 558;
BA_ "SigType" SG_ 2364539902 AccelPedal1LowIdleSwitch 4;
BA_ "SPN" SG_ 2364540158 EngDemandPercentTorque 2432;
BA_ "SigType" SG_ 2364540158 EngDemandPercentTorque 1;
BA_ "SPN" SG_ 2364540158 EngStarterMode 1675;
BA_ "SPN" SG_ 2364540158 SrcAddrssOfCntrllngDvcForEngCtrl 1483;
BA_ "SPN" SG_ 2364540158 EngSpeed 190;
BA_ "SigType" SG_ 2364540158 EngSpeed 1;
BA_ "SPN" SG_ 2364540158 ActualEngPercentTorque 513;
BA_ "GenSigStartValue" SG_ 2364540158 ActualEngPercentTorque 125;
BA_ "SigType" SG_ 2364540158 ActualEngPercentTorque 1;
BA_ "SPN" SG_ 2364540158 DriversDemandEngPercentTorque 512;
BA_ "GenSigStartValue" SG_ 2364540158 DriversDemandEngPercentTorque 125;
BA_ "SigType" SG_ 2364540158 DriversDemandEngPercentTorque 1;
BA_ "SPN" SG_ 2364540158 ActlEngPrcntTorqueHighResolution 4154;
BA_ "SPN" SG_ 2364540158 EngTorqueMode 899;
BA_ "SPN" SG_ 2566768126 ECUHardwareID 6714;
BA_ "SigType" SG_ 2566768126 ECUHardwareID 8;
BA_ "SPN" SG_ 2566768126 ECUManufacturerName 4304;
BA_ "SigType" SG_ 2566768126 ECUManufacturerName 8;
BA_ "SPN" SG_ 2566768126 ECUType 2904;
BA_ "SigType" SG_ 2566768126 ECUType 8;
BA_ "SPN" SG_ 2566768126 ECULocation 2903;
BA_ "SigType" SG_ 2566768126 ECULocation 8;
BA_ "SPN" SG_ 2566768126 ECUSerialNumber 2902;
BA_ "SigType" SG_ 2566768126 ECUSerialNumber 8;
BA_ "SPN" SG_ 2566768126 ECUPartNumber 2901;
BA_ "SigType" SG_ 2566768126 ECUPartNumber 8;
BA_ "SPN" SG_ 2566804734 EngMinContinuousTorque 1775;
BA_ "SigType" SG_ 2566804734 EngMinContinuousTorque 1;
BA_ "SPN" SG_ 2566804734 EngMaxContinuousTorque 1774;
BA_ "SigType" SG_ 2566804734 EngMaxContinuousTorque 1;
BA_ "SPN" SG_ 2566804734 EngMinContinuousRPM 1773;
BA_ "SigType" SG_ 2566804734 EngMinContinuousRPM 1;
BA_ "SPN" SG_ 2566804734 EngMaxContinuousRPM 1772;
BA_ "SigType" SG_ 2566804734 EngMaxContinuousRPM 1;
BA_ "SPN" SG_ 2566804734 EngHghLmtThrshldFrMnCntnsTrqFrmE 1771;
BA_ "SigType" SG_ 2566804734 EngHghLmtThrshldFrMnCntnsTrqFrmE 1;
BA_ "SPN" SG_ 2566804734 EngLwLmtThrshldFrMxTorqueFromEng 1770;
BA_ "SigType" SG_ 2566804734 EngLwLmtThrshldFrMxTorqueFromEng 1;
BA_ "SPN" SG_ 2566804734 EngHghLmtThrshldFrMnCntnusEngRPM 1769;
BA_ "SigType" SG_ 2566804734 EngHghLmtThrshldFrMnCntnusEngRPM 1;
BA_ "SPN" SG_ 2566804734 EngLwLmtThrsholdForMaxRPMFromEng 1768;
BA_ "SigType" SG_ 2566804734 EngLwLmtThrsholdForMaxRPMFromEng 1;
BA_ "SPN" SG_ 2566841342 DefaultIdleTrqLmt 7828;
BA_ "GenSigStartValue" SG_ 2566841342 DefaultIdleTrqLmt 125;
BA_ "SigType" SG_ 2566841342 DefaultIdleTrqLmt 1;
BA_ "SPN" SG_ 2566841342 SupportTSC1CtrlPurposeGroup4 3348;
BA_ "SPN" SG_ 2566841342 SupportTSC1CtrlPurposeGroup3 3347;
BA_ "SPN" SG_ 2566841342 SupportTSC1CtrlPurposeGroup2 3346;
BA_ "SPN" SG_ 2566841342 SupportTSC1CtrlPurposeGroup1 3345;
BA_ "SPN" SG_ 2566841342 SupportVariableRateTSC1Message 3344;
BA_ "SPN" SG_ 2566841342 EngDefaultTorqueLimit 1846;
BA_ "SigType" SG_ 2566841342 EngDefaultTorqueLimit 1;
BA_ "SPN" SG_ 2566841342 EngMomentOfInertia 1794;
BA_ "SigType" SG_ 2566841342 EngMomentOfInertia 1;
BA_ "SPN" SG_ 2566841342 EngExRngRqstdSpdCtrlRngUpprLimit 1712;
BA_ "SigType" SG_ 2566841342 EngExRngRqstdSpdCtrlRngUpprLimit 1;
BA_ "SPN" SG_ 2566841342 EngRqstdTrqueCtrlRangeUpperLimit 538;
BA_ "GenSigStartValue" SG_ 2566841342 EngRqstdTrqueCtrlRangeUpperLimit 125;
BA_ "SigType" SG_ 2566841342 EngRqstdTrqueCtrlRangeUpperLimit 1;
BA_ "SPN" SG_ 2566841342 EngRqstdTrqueCtrlRangeLowerLimit 537;
BA_ "GenSigStartValue" SG_ 2566841342 EngRqstdTrqueCtrlRangeLowerLimit 125;
BA_ "SigType" SG_ 2566841342 EngRqstdTrqueCtrlRangeLowerLimit 1;
BA_ "SPN" SG_ 2566841342 EngRqstdSpeedCtrlRangeUpperLimit 536;
BA_ "SigType" SG_ 2566841342 EngRqstdSpeedCtrlRangeUpperLimit 1;
BA_ "SPN" SG_ 2566841342 EngRqstdSpeedCtrlRangeLowerLimit 535;
BA_ "SigType" SG_ 2566841342 EngRqstdSpeedCtrlRangeLowerLimit 1;
BA_ "SPN" SG_ 2566841342 EngMaxMomentaryOverrideTimeLimit 534;
BA_ "SigType" SG_ 2566841342 EngMaxMomentaryOverrideTimeLimit 1;
BA_ "SPN" SG_ 2566841342 EngMxMmentaryOverrideSpeedPoint7 533;
BA_ "SigType" SG_ 2566841342 EngMxMmentaryOverrideSpeedPoint7 1;
BA_ "SPN" SG_ 2566841342 EngReferenceTorque 544;
BA_ "SigType" SG_ 2566841342 EngReferenceTorque 1;
BA_ "SPN" SG_ 2566841342 EngGain 545;
BA_ "SigType" SG_ 2566841342 EngGain 1;
BA_ "SPN" SG_ 2566841342 EngSpeedAtHighIdlePoint6 532;
BA_ "SigType" SG_ 2566841342 EngSpeedAtHighIdlePoint6 1;
BA_ "SPN" SG_ 2566841342 EngPercentTorqueAtPoint5 543;
BA_ "GenSigStartValue" SG_ 2566841342 EngPercentTorqueAtPoint5 125;
BA_ "SigType" SG_ 2566841342 EngPercentTorqueAtPoint5 1;
BA_ "SPN" SG_ 2566841342 EngSpeedAtPoint5 531;
BA_ "SigType" SG_ 2566841342 EngSpeedAtPoint5 1;
BA_ "SPN" SG_ 2566841342 EngPercentTorqueAtPoint4 542;
BA_ "GenSigStartValue" SG_ 2566841342 EngPercentTorqueAtPoint4 125;
BA_ "SigType" SG_ 2566841342 EngPercentTorqueAtPoint4 1;
BA_ "SPN" SG_ 2566841342 EngSpeedAtPoint4 530;
BA_ "SigType" SG_ 2566841342 EngSpeedAtPoint4 1;
BA_ "SPN" SG_ 2566841342 EngPercentTorqueAtPoint3 541;
BA_ "GenSigStartValue" SG_ 2566841342 EngPercentTorqueAtPoint3 125;
BA_ "SigType" SG_ 2566841342 EngPercentTorqueAtPoint3 1;
BA_ "SPN" SG_ 2566841342 EngSpeedAtPoint3 529;
BA_ "SigType" SG_ 2566841342 EngSpeedAtPoint3 1;
BA_ "SPN" SG_ 2566841342 EngPercentTorqueAtPoint2 540;
BA_ "GenSigStartValue" SG_ 2566841342 EngPercentTorqueAtPoint2 125;
BA_ "SigType" SG_ 2566841342 EngPercentTorqueAtPoint2 1;
BA_ "SPN" SG_ 2566841342 EngSpeedAtPoint2 528;
BA_ "SigType" SG_ 2566841342 EngSpeedAtPoint2 1;
BA_ "SPN" SG_ 2566841342 EngPercentTorqueAtIdlePoint1 539;
BA_ "GenSigStartValue" SG_ 2566841342 EngPercentTorqueAtIdlePoint1 125;
BA_ "SigType" SG_ 2566841342 EngPercentTorqueAtIdlePoint1 1;
BA_ "SPN" SG_ 2566841342 EngSpeedAtIdlePoint1 188;
BA_ "SigType" SG_ 2566841342 EngSpeedAtIdlePoint1 1;
BA_ "SPN" SG_ 2566767870 RailroadMode 7942;
BA_ "SigType" SG_ 2566767870 RailroadMode 5;
BA_ "SPN" SG_ 2566767870 EmergencyBrakingActive 5847;
BA_ "SigType" SG_ 2566767870 EmergencyBrakingActive 5;
BA_ "SPN" SG_ 2566767870 PrkngBrakeActuatorFullyActivated 5275;
BA_ "SigType" SG_ 2566767870 PrkngBrakeActuatorFullyActivated 4;
BA_ "SPN" SG_ 2566767870 XBRAccelerationLimit 2921;
BA_ "GenSigStartValue" SG_ 2566767870 XBRAccelerationLimit 25;
BA_ "SigType" SG_ 2566767870 XBRAccelerationLimit 1;
BA_ "SPN" SG_ 2566767870 XBRActiveCtrlMode 2918;
BA_ "SPN" SG_ 2566767870 XBRSystemState 2917;
BA_ "SigType" SG_ 2566767870 XBRSystemState 5;
BA_ "SPN" SG_ 2566767870 FoundationBrakeUse 2919;
BA_ "SigType" SG_ 2566767870 FoundationBrakeUse 5;
BA_ "SPN" SG_ 2566767870 HillHolderMode 2912;
BA_ "SPN" SG_ 2566767870 HaltBrakeMode 2913;
BA_ "SPN" SG_ 2566767870 BrakeTempWarning 3839;
BA_ "SigType" SG_ 2566767870 BrakeTempWarning 5;
BA_ "SPN" SG_ 2633936126 BrkLnngRmningRearAxle3RightWheel 1106;
BA_ "SigType" SG_ 2633936126 BrkLnngRmningRearAxle3RightWheel 1;
BA_ "SPN" SG_ 2633936126 BrkLnngRminingRearAxle3LeftWheel 1105;
BA_ "SigType" SG_ 2633936126 BrkLnngRminingRearAxle3LeftWheel 1;
BA_ "SPN" SG_ 2633936126 BrkLnngRmningRearAxle2RightWheel 1104;
BA_ "SigType" SG_ 2633936126 BrkLnngRmningRearAxle2RightWheel 1;
BA_ "SPN" SG_ 2633936126 BrkLnngRminingRearAxle2LeftWheel 1103;
BA_ "SigType" SG_ 2633936126 BrkLnngRminingRearAxle2LeftWheel 1;
BA_ "SPN" SG_ 2633936126 BrkLnngRmningRearAxle1RightWheel 1102;
BA_ "SigType" SG_ 2633936126 BrkLnngRmningRearAxle1RightWheel 1;
BA_ "SPN" SG_ 2633936126 BrkLnngRminingRearAxle1LeftWheel 1101;
BA_ "SigType" SG_ 2633936126 BrkLnngRminingRearAxle1LeftWheel 1;
BA_ "SPN" SG_ 2633936126 BrkLnngRmningFrontAxleRightWheel 1100;
BA_ "SigType" SG_ 2633936126 BrkLnngRmningFrontAxleRightWheel 1;
BA_ "SPN" SG_ 2633936126 BrkLnngRminingFrontAxleLeftWheel 1099;
BA_ "SigType" SG_ 2633936126 BrkLnngRminingFrontAxleLeftWheel 1;
BA_ "SPN" SG_ 2566827518 BrkAppPrssHghRngRrAxl3RightWheel 1098;
BA_ "SigType" SG_ 2566827518 BrkAppPrssHghRngRrAxl3RightWheel 1;
BA_ "SPN" SG_ 2566827518 BrkAppPrssHghRngRrAxle3LeftWheel 1097;
BA_ "SigType" SG_ 2566827518 BrkAppPrssHghRngRrAxle3LeftWheel 1;
BA_ "SPN" SG_ 2566827518 BrkAppPrssHghRngRrAxl2RightWheel 1096;
BA_ "SigType" SG_ 2566827518 BrkAppPrssHghRngRrAxl2RightWheel 1;
BA_ "SPN" SG_ 2566827518 BrkAppPrssHghRngRrAxle2LeftWheel 1095;
BA_ "SigType" SG_ 2566827518 BrkAppPrssHghRngRrAxle2LeftWheel 1;
BA_ "SPN" SG_ 2566827518 BrkAppPrssHghRngRrAxle1LeftWheel 1093;
BA_ "SigType" SG_ 2566827518 BrkAppPrssHghRngRrAxle1LeftWheel 1;
BA_ "SPN" SG_ 2566827518 BrkAppPrssHghRngFrntAxlRghtWheel 1092;
BA_ "SigType" SG_ 2566827518 BrkAppPrssHghRngFrntAxlRghtWheel 1;
BA_ "SPN" SG_ 2566827518 BrkAppPrssHghRngFrntAxlLeftWheel 1091;
BA_ "SigType" SG_ 2566827518 BrkAppPrssHghRngFrntAxlLeftWheel 1;
BA_ "SPN" SG_ 2566827518 BrkAppPrssHghRngRrAxl1RightWheel 1094;
BA_ "SigType" SG_ 2566827518 BrkAppPrssHghRngRrAxl1RightWheel 1;
BA_ "SPN" SG_ 2566832126 RelativeSpeedRearAxle2RightWheel 910;
BA_ "SigType" SG_ 2566832126 RelativeSpeedRearAxle2RightWheel 1;
BA_ "SPN" SG_ 2566832126 RelativeSpeedRearAxle2LeftWheel 909;
BA_ "SigType" SG_ 2566832126 RelativeSpeedRearAxle2LeftWheel 1;
BA_ "SPN" SG_ 2566832126 RelativeSpeedRearAxle1RightWheel 908;
BA_ "SigType" SG_ 2566832126 RelativeSpeedRearAxle1RightWheel 1;
BA_ "SPN" SG_ 2566832126 RelativeSpeedRearAxle1LeftWheel 907;
BA_ "SigType" SG_ 2566832126 RelativeSpeedRearAxle1LeftWheel 1;
BA_ "SPN" SG_ 2566832126 RelativeSpeedFrontAxleRightWheel 906;
BA_ "SigType" SG_ 2566832126 RelativeSpeedFrontAxleRightWheel 1;
BA_ "SPN" SG_ 2566832126 RelativeSpeedFrontAxleLeftWheel 905;
BA_ "SigType" SG_ 2566832126 RelativeSpeedFrontAxleLeftWheel 1;
BA_ "SPN" SG_ 2566832126 FrontAxleSpeed 904;
BA_ "SigType" SG_ 2566832126 FrontAxleSpeed 1;
BA_ "SPN" SG_ 2565865982 RailroadModeSw 7941;
BA_ "SigType" SG_ 2565865982 RailroadModeSw 4;
BA_ "SPN" SG_ 2565865982 TrctrMntdTrailerABSWarningSignal 1792;
BA_ "SigType" SG_ 2565865982 TrctrMntdTrailerABSWarningSignal 5;
BA_ "SPN" SG_ 2565865982 TrailerABSStatus 1836;
BA_ "SigType" SG_ 2565865982 TrailerABSStatus 5;
BA_ "SPN" SG_ 2565865982 HaltBrakeSwitch 2911;
BA_ "SigType" SG_ 2565865982 HaltBrakeSwitch 4;
BA_ "SPN" SG_ 2565865982 SrcAddrssOfCntrllngDvcFrBrkeCtrl 1481;
BA_ "SPN" SG_ 2565865982 ATC_ASRInformationSignal 1793;
BA_ "SigType" SG_ 2565865982 ATC_ASRInformationSignal 5;
BA_ "SPN" SG_ 2565865982 ABS_EBSAmberWarningSignal 1438;
BA_ "SigType" SG_ 2565865982 ABS_EBSAmberWarningSignal 5;
BA_ "SPN" SG_ 2565865982 EBSRedWarningSignal 1439;
BA_ "SigType" SG_ 2565865982 EBSRedWarningSignal 5;
BA_ "SPN" SG_ 2565865982 ABSFullyOperational 1243;
BA_ "SigType" SG_ 2565865982 ABSFullyOperational 5;
BA_ "SPN" SG_ 2565865982 EngRetarderSelection 973;
BA_ "SigType" SG_ 2565865982 EngRetarderSelection 1;
BA_ "SPN" SG_ 2565865982 RemoteAccelEnableSwitch 969;
BA_ "SigType" SG_ 2565865982 RemoteAccelEnableSwitch 4;
BA_ "SPN" SG_ 2565865982 EngAuxShutdownSwitch 970;
BA_ "SigType" SG_ 2565865982 EngAuxShutdownSwitch 4;
BA_ "SPN" SG_ 2565865982 EngDerateSwitch 971;
BA_ "SigType" SG_ 2565865982 EngDerateSwitch 4;
BA_ "SPN" SG_ 2565865982 AccelInterlockSwitch 972;
BA_ "SigType" SG_ 2565865982 AccelInterlockSwitch 4;
BA_ "SPN" SG_ 2565865982 TractionCtrlOverrideSwitch 1238;
BA_ "SigType" SG_ 2565865982 TractionCtrlOverrideSwitch 4;
BA_ "SPN" SG_ 2565865982 ASRHillHolderSwitch 577;
BA_ "SigType" SG_ 2565865982 ASRHillHolderSwitch 4;
BA_ "SPN" SG_ 2565865982 ASROffroadSwitch 576;
BA_ "SigType" SG_ 2565865982 ASROffroadSwitch 4;
BA_ "SPN" SG_ 2565865982 ABSOffroadSwitch 575;
BA_ "SigType" SG_ 2565865982 ABSOffroadSwitch 4;
BA_ "SPN" SG_ 2565865982 BrakePedalPos 521;
BA_ "SigType" SG_ 2565865982 BrakePedalPos 1;
BA_ "SPN" SG_ 2565865982 EBSBrakeSwitch 1121;
BA_ "SigType" SG_ 2565865982 EBSBrakeSwitch 4;
BA_ "SPN" SG_ 2565865982 AntiLockBrakingActive 563;
BA_ "SigType" SG_ 2565865982 AntiLockBrakingActive 5;
BA_ "SPN" SG_ 2565865982 ASRBrakeCtrlActive 562;
BA_ "SigType" SG_ 2565865982 ASRBrakeCtrlActive 5;
BA_ "SPN" SG_ 2565865982 ASREngCtrlActive 561;
BA_ "SigType" SG_ 2565865982 ASREngCtrlActive 5;
BA_ "SPN" SG_ 2565867262 DiffLockStRearAxle3 7716;
BA_ "SigType" SG_ 2565867262 DiffLockStRearAxle3 5;
BA_ "SPN" SG_ 2565867262 RearAxleGroupEngagementStatus 3820;
BA_ "SigType" SG_ 2565867262 RearAxleGroupEngagementStatus 5;
BA_ "SPN" SG_ 2565867262 FrontAxleGroupEngagementStatus 3819;
BA_ "SigType" SG_ 2565867262 FrontAxleGroupEngagementStatus 5;
BA_ "SPN" SG_ 2565867262 DiffLockStateCentralRear 566;
BA_ "SigType" SG_ 2565867262 DiffLockStateCentralRear 5;
BA_ "SPN" SG_ 2565867262 DiffLockStateCentralFront 565;
BA_ "SigType" SG_ 2565867262 DiffLockStateCentralFront 5;
BA_ "SPN" SG_ 2565867262 DiffLockStateCentral 564;
BA_ "SigType" SG_ 2565867262 DiffLockStateCentral 5;
BA_ "SPN" SG_ 2565867262 DiffLockStateRearAxle2 570;
BA_ "SigType" SG_ 2565867262 DiffLockStateRearAxle2 5;
BA_ "SPN" SG_ 2565867262 DiffLockStateRearAxle1 569;
BA_ "SigType" SG_ 2565867262 DiffLockStateRearAxle1 5;
BA_ "SPN" SG_ 2565867262 DiffLockStateFrontAxle2 568;
BA_ "SigType" SG_ 2565867262 DiffLockStateFrontAxle2 5;
BA_ "SPN" SG_ 2565867262 DiffLockStateFrontAxle1 567;
BA_ "SigType" SG_ 2565867262 DiffLockStateFrontAxle1 5;
BA_ "SPN" SG_ 2565867262 Location 927;
BA_ "SPN" SG_ 2566821118 CPCoolantOutPress 8473;
BA_ "SigType" SG_ 2566821118 CPCoolantOutPress 1;
BA_ "SPN" SG_ 2566821118 EngCoolantPress2 7313;
BA_ "SigType" SG_ 2566821118 EngCoolantPress2 1;
BA_ "SPN" SG_ 2566821118 EngExRangeCoolantPress 20;
BA_ "SigType" SG_ 2566821118 EngExRangeCoolantPress 1;
BA_ "SPN" SG_ 2566821118 SeaWaterPumpOutletPress 2435;
BA_ "SigType" SG_ 2566821118 SeaWaterPumpOutletPress 1;
BA_ "SPN" SG_ 2566821118 EngAuxCoolantTemp 1212;
BA_ "SigType" SG_ 2566821118 EngAuxCoolantTemp 1;
BA_ "SPN" SG_ 2566821118 EngAuxCoolantPress 1203;
BA_ "SigType" SG_ 2566821118 EngAuxCoolantPress 1;
BA_ "SPN" SG_ 2566810622 Driver2Identification 1626;
BA_ "SigType" SG_ 2566810622 Driver2Identification 8;
BA_ "SPN" SG_ 2566810622 Driver1Identification 1625;
BA_ "SigType" SG_ 2566810622 Driver1Identification 8;
BA_ "SPN" SG_ 2566847742 EngOilFilterDiffPress7471 7471;
BA_ "SigType" SG_ 2566847742 EngOilFilterDiffPress7471 1;
BA_ "SPN" SG_ 2566847742 FuelLevel2 38;
BA_ "SigType" SG_ 2566847742 FuelLevel2 1;
BA_ "SPN" SG_ 2566847742 CargoAmbientTemp 169;
BA_ "SigType" SG_ 2566847742 CargoAmbientTemp 1;
BA_ "SPN" SG_ 2566847742 EngOilFilterDiffPress 99;
BA_ "SigType" SG_ 2566847742 EngOilFilterDiffPress 1;
BA_ "SPN" SG_ 2566847742 EngFuelFilterDiffPress 95;
BA_ "SigType" SG_ 2566847742 EngFuelFilterDiffPress 1;
BA_ "SPN" SG_ 2566847742 FuelLevel1 96;
BA_ "SigType" SG_ 2566847742 FuelLevel1 1;
BA_ "SPN" SG_ 2566847742 WasherFluidLevel 80;
BA_ "SigType" SG_ 2566847742 WasherFluidLevel 1;
BA_ "SPN" SG_ 2498778622 EngCyl8AverageCombustionDuration 6514;
BA_ "SigType" SG_ 2498778622 EngCyl8AverageCombustionDuration 1;
BA_ "SPN" SG_ 2498778622 EngCyl8AvrgCntrOfCmbustionTiming 6513;
BA_ "SigType" SG_ 2498778622 EngCyl8AvrgCntrOfCmbustionTiming 1;
BA_ "SPN" SG_ 2498778622 EngCyl8AvrgStrtOfCmbustionTiming 6512;
BA_ "SigType" SG_ 2498778622 EngCyl8AvrgStrtOfCmbustionTiming 1;
BA_ "SPN" SG_ 2498778622 EngCyl8IndctedMeanEffectivePress 6511;
BA_ "SigType" SG_ 2498778622 EngCyl8IndctedMeanEffectivePress 1;
BA_ "SPN" SG_ 2498778366 EngCyl7AverageCombustionDuration 6510;
BA_ "SigType" SG_ 2498778366 EngCyl7AverageCombustionDuration 1;
BA_ "SPN" SG_ 2498778366 EngCyl7AvrgCntrOfCmbustionTiming 6509;
BA_ "SigType" SG_ 2498778366 EngCyl7AvrgCntrOfCmbustionTiming 1;
BA_ "SPN" SG_ 2498778366 EngCyl7AvrgStrtOfCmbustionTiming 6508;
BA_ "SigType" SG_ 2498778366 EngCyl7AvrgStrtOfCmbustionTiming 1;
BA_ "SPN" SG_ 2498778366 EngCyl7IndctedMeanEffectivePress 6507;
BA_ "SigType" SG_ 2498778366 EngCyl7IndctedMeanEffectivePress 1;
BA_ "SPN" SG_ 2498778110 EngCyl6AverageCombustionDuration 6506;
BA_ "SigType" SG_ 2498778110 EngCyl6AverageCombustionDuration 1;
BA_ "SPN" SG_ 2498778110 EngCyl6AvrgCntrOfCmbustionTiming 6505;
BA_ "SigType" SG_ 2498778110 EngCyl6AvrgCntrOfCmbustionTiming 1;
BA_ "SPN" SG_ 2498778110 EngCyl6AvrgStrtOfCmbustionTiming 6504;
BA_ "SigType" SG_ 2498778110 EngCyl6AvrgStrtOfCmbustionTiming 1;
BA_ "SPN" SG_ 2498778110 EngCyl6IndctedMeanEffectivePress 6503;
BA_ "SigType" SG_ 2498778110 EngCyl6IndctedMeanEffectivePress 1;
BA_ "SPN" SG_ 2498777854 EngCyl5AverageCombustionDuration 6502;
BA_ "SigType" SG_ 2498777854 EngCyl5AverageCombustionDuration 1;
BA_ "SPN" SG_ 2498777854 EngCyl5AvrgCntrOfCmbustionTiming 6501;
BA_ "SigType" SG_ 2498777854 EngCyl5AvrgCntrOfCmbustionTiming 1;
BA_ "SPN" SG_ 2498777854 EngCyl5AvrgStrtOfCmbustionTiming 6500;
BA_ "SigType" SG_ 2498777854 EngCyl5AvrgStrtOfCmbustionTiming 1;
BA_ "SPN" SG_ 2498777854 EngCyl5IndctedMeanEffectivePress 6499;
BA_ "SigType" SG_ 2498777854 EngCyl5IndctedMeanEffectivePress 1;
BA_ "SPN" SG_ 2498777598 EngCyl4AverageCombustionDuration 6498;
BA_ "SigType" SG_ 2498777598 EngCyl4AverageCombustionDuration 1;
BA_ "SPN" SG_ 2498777598 EngCyl4AvrgCntrOfCmbustionTiming 6497;
BA_ "SigType" SG_ 2498777598 EngCyl4AvrgCntrOfCmbustionTiming 1;
BA_ "SPN" SG_ 2498777598 EngCyl4AvrgStrtOfCmbustionTiming 6496;
BA_ "SigType" SG_ 2498777598 EngCyl4AvrgStrtOfCmbustionTiming 1;
BA_ "SPN" SG_ 2498777598 EngCyl4IndctedMeanEffectivePress 6495;
BA_ "SigType" SG_ 2498777598 EngCyl4IndctedMeanEffectivePress 1;
BA_ "SPN" SG_ 2498777342 EngCyl3AverageCombustionDuration 6494;
BA_ "SigType" SG_ 2498777342 EngCyl3AverageCombustionDuration 1;
BA_ "SPN" SG_ 2498777342 EngCyl3AvrgCntrOfCmbustionTiming 6493;
BA_ "SigType" SG_ 2498777342 EngCyl3AvrgCntrOfCmbustionTiming 1;
BA_ "SPN" SG_ 2498777342 EngCyl3AvrgStrtOfCmbustionTiming 6492;
BA_ "SigType" SG_ 2498777342 EngCyl3AvrgStrtOfCmbustionTiming 1;
BA_ "SPN" SG_ 2498777342 EngCyl3IndctedMeanEffectivePress 6491;
BA_ "SigType" SG_ 2498777342 EngCyl3IndctedMeanEffectivePress 1;
BA_ "SPN" SG_ 2566768382 EngCldStrtFlIgniterRelayFeedback 5550;
BA_ "SigType" SG_ 2566768382 EngCldStrtFlIgniterRelayFeedback 4;
BA_ "SPN" SG_ 2566768382 EngColdStartFuelIgniterRelay 5549;
BA_ "SigType" SG_ 2566768382 EngColdStartFuelIgniterRelay 5;
BA_ "SPN" SG_ 2566768382 EngColdStartFuelIgniterCmd 5548;
BA_ "SigType" SG_ 2566768382 EngColdStartFuelIgniterCmd 1;
BA_ "SPN" SG_ 2566768382 EngStartEnableDevice2Config 2898;
BA_ "SPN" SG_ 2566768382 EngStartEnableDevice1Config 2899;
BA_ "SPN" SG_ 2566768382 EngStartEnableDevice2 1804;
BA_ "SigType" SG_ 2566768382 EngStartEnableDevice2 5;
BA_ "SPN" SG_ 2566768382 EngStartEnableDevice1 626;
BA_ "SigType" SG_ 2566768382 EngStartEnableDevice1 5;
BA_ "SPN" SG_ 2566811902 PoweredVehicleWeight 1585;
BA_ "SigType" SG_ 2566811902 PoweredVehicleWeight 1;
BA_ "SPN" SG_ 2566811902 GrossCombinationVehicleWeight 1760;
BA_ "SigType" SG_ 2566811902 GrossCombinationVehicleWeight 1;
BA_ "SPN" SG_ 2563768062 MxCntinuousRetarderTorqueLimitRq 1791;
BA_ "SigType" SG_ 2563768062 MxCntinuousRetarderTorqueLimitRq 1;
BA_ "SPN" SG_ 2563768062 MnCntinuousRetarderTorqueLimitRq 1790;
BA_ "SigType" SG_ 2563768062 MnCntinuousRetarderTorqueLimitRq 1;
BA_ "SPN" SG_ 2563768062 MxContinuousRetarderSpeedLimitRq 1789;
BA_ "SigType" SG_ 2563768062 MxContinuousRetarderSpeedLimitRq 1;
BA_ "SPN" SG_ 2563768062 MnContinuousRetarderSpeedLimitRq 1788;
BA_ "SigType" SG_ 2563768062 MnContinuousRetarderSpeedLimitRq 1;
BA_ "SPN" SG_ 2563768062 EngTorqueLimitRqMaxContinuous 1787;
BA_ "GenSigStartValue" SG_ 2563768062 EngTorqueLimitRqMaxContinuous 125;
BA_ "SigType" SG_ 2563768062 EngTorqueLimitRqMaxContinuous 1;
BA_ "SPN" SG_ 2563768062 EngTorqueLimitRqMinContinuous 1786;
BA_ "GenSigStartValue" SG_ 2563768062 EngTorqueLimitRqMinContinuous 125;
BA_ "SigType" SG_ 2563768062 EngTorqueLimitRqMinContinuous 1;
BA_ "SPN" SG_ 2563768062 EngSpeedLimitRqMaxContinuous 1785;
BA_ "SigType" SG_ 2563768062 EngSpeedLimitRqMaxContinuous 1;
BA_ "SPN" SG_ 2563768062 EngSpeedLimitRqMinContinuous 1784;
BA_ "SigType" SG_ 2563768062 EngSpeedLimitRqMinContinuous 1;
BA_ "SPN" SG_ 2633924862 EngAverageCombustionTime 1465;
BA_ "SigType" SG_ 2633924862 EngAverageCombustionTime 1;
BA_ "SPN" SG_ 2633924862 EngDesiredCombustionTime 1464;
BA_ "SigType" SG_ 2633924862 EngDesiredCombustionTime 1;
BA_ "SPN" SG_ 2633924606 EngCyl20CombustionTime 1463;
BA_ "SigType" SG_ 2633924606 EngCyl20CombustionTime 1;
BA_ "SPN" SG_ 2633924606 EngCyl19CombustionTime 1462;
BA_ "SigType" SG_ 2633924606 EngCyl19CombustionTime 1;
BA_ "SPN" SG_ 2633924606 EngCyl18CombustionTime 1461;
BA_ "SigType" SG_ 2633924606 EngCyl18CombustionTime 1;
BA_ "SPN" SG_ 2633924606 EngCyl17CombustionTime 1460;
BA_ "SigType" SG_ 2633924606 EngCyl17CombustionTime 1;
BA_ "SPN" SG_ 2633924350 EngCyl16CombustionTime 1459;
BA_ "SigType" SG_ 2633924350 EngCyl16CombustionTime 1;
BA_ "SPN" SG_ 2633924350 EngCyl15CombustionTime 1458;
BA_ "SigType" SG_ 2633924350 EngCyl15CombustionTime 1;
BA_ "SPN" SG_ 2633924350 EngCyl14CombustionTime 1457;
BA_ "SigType" SG_ 2633924350 EngCyl14CombustionTime 1;
BA_ "SPN" SG_ 2633924350 EngCyl13CombustionTime 1456;
BA_ "SigType" SG_ 2633924350 EngCyl13CombustionTime 1;
BA_ "SPN" SG_ 2633924094 EngCyl12CombustionTime 1455;
BA_ "SigType" SG_ 2633924094 EngCyl12CombustionTime 1;
BA_ "SPN" SG_ 2633924094 EngCyl11CombustionTime 1454;
BA_ "SigType" SG_ 2633924094 EngCyl11CombustionTime 1;
BA_ "SPN" SG_ 2633924094 EngCyl10CombustionTime 1453;
BA_ "SigType" SG_ 2633924094 EngCyl10CombustionTime 1;
BA_ "SPN" SG_ 2633924094 EngCyl9CombustionTime 1452;
BA_ "SigType" SG_ 2633924094 EngCyl9CombustionTime 1;
BA_ "SPN" SG_ 2633923838 EngCyl8CombustionTime 1451;
BA_ "SigType" SG_ 2633923838 EngCyl8CombustionTime 1;
BA_ "SPN" SG_ 2633923838 EngCyl7CombustionTime 1450;
BA_ "SigType" SG_ 2633923838 EngCyl7CombustionTime 1;
BA_ "SPN" SG_ 2633923838 EngCyl6CombustionTime 1449;
BA_ "SigType" SG_ 2633923838 EngCyl6CombustionTime 1;
BA_ "SPN" SG_ 2633923838 EngCyl5CombustionTime 1448;
BA_ "SigType" SG_ 2633923838 EngCyl5CombustionTime 1;
BA_ "SPN" SG_ 2633923582 EngCyl4CombustionTime 1447;
BA_ "SigType" SG_ 2633923582 EngCyl4CombustionTime 1;
BA_ "SPN" SG_ 2633923582 EngCyl3CombustionTime 1446;
BA_ "SigType" SG_ 2633923582 EngCyl3CombustionTime 1;
BA_ "SPN" SG_ 2633923582 EngCyl2CombustionTime 1445;
BA_ "SigType" SG_ 2633923582 EngCyl2CombustionTime 1;
BA_ "SPN" SG_ 2633923582 EngCyl1CombustionTime 1444;
BA_ "SigType" SG_ 2633923582 EngCyl1CombustionTime 1;
BA_ "SPN" SG_ 2633878014 TotalCountOfConfigChangesMade 2887;
BA_ "SigType" SG_ 2633878014 TotalCountOfConfigChangesMade 1;
BA_ "SPN" SG_ 2566771966 AFTDEFDosingModeCmd 9175;
BA_ "SPN" SG_ 2566771966 VehTrailerStatus 7711;
BA_ "SigType" SG_ 2566771966 VehTrailerStatus 4;
BA_ "SPN" SG_ 2566771966 TransOilLevelRq 3809;
BA_ "SigType" SG_ 2566771966 TransOilLevelRq 5;
BA_ "SPN" SG_ 2566771966 FifthWheelReleaseCtrl 3314;
BA_ "SigType" SG_ 2566771966 FifthWheelReleaseCtrl 4;
BA_ "SPN" SG_ 2566771966 FfthWhlRleaseCtrlSecurityLockout 3315;
BA_ "SigType" SG_ 2566771966 FfthWhlRleaseCtrlSecurityLockout 4;
BA_ "SPN" SG_ 2566771966 TransferCaseSelectorSwitch 2796;
VAL_ 2565868542 TypeOfSteerTrans 15 "Not available" 3 "Hybrid steering transmission" 2 "Purely electric steering transmission" 1 "Purely hydraulic steering transmission" 0 "Purely mechanical steering transmission" ;
VAL_ 2565868542 TypeOfSteerForces 15 "Not Available" 3 "Self tracking steering equipment" 2 "Full power steering equipment" 1 "Power assisted steering equipment" 0 "Manual steering equipment" ;
VAL_ 2565868542 SteerType 15 "Not Available" 1 "Auxiliary steering equipment" 0 "Main steering system" ;
VAL_ 2565868542 SteerableLiftAxleLoweringInhibit 1 "Lowering inhibited" 0 "Lowering allowed" 3 "Not available" 2 "Reserved" ;
VAL_ 2565868542 StatusOfSteerAxle 15 "Not available" 5 "Axle steering in special mode" 4 "Axle not active because of an error" 3 "Axle centered,  because of an error" 2 "Axle centered" 1 "Axle steering active" 0 "Axle steering not active" ;
VAL_ 2633941758 TransOutputRetarder 3 "Not available" 2 "Error" 1 "On" 0 "Off" ;
VAL_ 2565865726 RetarderRoadSpeedExceededStatus 3 "Don't care/Take no action" 2 "Reserved" 1 "Road speed is above threshold and retarder is allowed to be activated" 0 "Road speed is below threshold" ;
VAL_ 2565865726 RetarderRoadSpeedLimitSwitch 3 "Not Available" 2 "Error Indicator" 1 "Road speed limiting by retarder is enabled" 0 "Road speed limiting by retarder is disabled" ;
VAL_ 2565865726 RetarderRequestingBrakeLight 0 "Retarder is not requesting that the brake lights are illuminated" 3 "Not available/Take no action" 2 "Reserved" 1 "Retarder is requesting that the brake lights are illuminated" ;
VAL_ 2565865726 EngCoolantLoadIncrease 3 "Not available" 2 "Error" 1 "Coolant load increase possible" 0 "No coolant load increase" ;
VAL_ 2565865726 RetarderEnableShiftAssistSwitch 3 "Not available" 2 "Error" 1 "Retarder, shift assist enabled" 0 "Retarder, shift assist disabled" ;
VAL_ 2565865726 RetarderEnableBrakeAssistSwitch 3 "Not available" 2 "Error" 1 "Retarder, brake assist enabled" 0 "Retarder, brake assist disabled" ;
VAL_ 2633935358 EngExhstGsOxygnSnsrClsdLpOprtion 3 "Don't Care/take no action" 2 "Reserved" 1 "Engine using the exhaust oxygen sensor for a closed loop operation" 0 "Engine not using the exhaust oxygen sensor" ;
VAL_ 2365447166 Joystick3Button13PressedStatus 3 "Not Available" 2 "Error Indicator" 1 "Button pressed" 0 "Button not pressed" ;
VAL_ 2365447166 Joystick3Button14PressedStatus 3 "Not Available" 2 "Error Indicator" 1 "Button pressed" 0 "Button not pressed" ;
VAL_ 2365447166 Joystick3Button15PressedStatus 3 "Not Available" 2 "Error Indicator" 1 "Button pressed" 0 "Button not pressed" ;
VAL_ 2365447166 Joystick3Button16PressedStatus 3 "Not Available" 2 "Error Indicator" 1 "Button pressed" 0 "Button not pressed" ;
VAL_ 2365447166 Jystick3GripXAxisDetentPosStatus 3 "Not Available" 2 "Error Indicator" 1 "In the Detent Position" 0 "Not in the Detent Position" ;
VAL_ 2365447166 Jystick3GripYAxisDetentPosStatus 3 "Not Available" 2 "Error Indicator" 1 "In the Detent Position" 0 "Not in the Detent Position" ;
VAL_ 2365447166 Jystick3ThetaAxisDetentPosStatus 3 "Not Available" 2 "Error Indicator" 1 "In the Detent Position" 0 "Not in the Detent Position" ;
VAL_ 2365447166 Jystck3ThtAxsClckwsPstvPosStatus 3 "Not Available" 2 "Error Indicator" 1 "On positive side of Neutral" 0 "Not on Positive side of Neutral" ;
VAL_ 2365447166 Jystck3ThetaAxisNeutralPosStatus 3 "Not Available" 2 "Error Indicator" 1 "In Neutral Position" 0 "Not in Neutral Position" ;
VAL_ 2365447166 Jystck3GrpYAxsLvrFrwrdPstvPsStts 3 "Not Available" 2 "Error Indicator" 1 "On positive side of Neutral" 0 "Not on Positive side of Neutral" ;
VAL_ 2365447166 Jystck3GrpYAxsLvrBckNgtvPsStatus 3 "Not Available" 2 "Error Indicator" 1 "On negative side of Neutral" 0 "Not on negative side of Neutral" ;
VAL_ 2365447166 Jystck3GripYAxisNeutralPosStatus 3 "Not Available" 2 "Error Indicator" 1 "In Neutral Position" 0 "Not in Neutral Position" ;
VAL_ 2365447166 Jystck3GrpXAxsLvrRghtPstvPsSttus 3 "Not Available" 2 "Error Indicator" 1 "On positive side of Neutral" 0 "Not on Positive side of Neutral" ;
VAL_ 2365447166 Jystck3GrpXAxsLvrLftNgtvPsStatus 3 "Not Available" 2 "Error Indicator" 1 "On negative side of Neutral" 0 "Not on negative side of Neutral" ;
VAL_ 2365447166 Jystck3GripXAxisNeutralPosStatus 3 "Not Available" 2 "Error Indicator" 1 "On negative side of Neutral" 0 "Not on negative side of Neutral" ;
VAL_ 2365447166 Jystck3ThtAxsCntrClckwsNgtvPsStt 3 "Not Available" 2 "Error Indicator" 1 "On negative side of Neutral" 0 "Not on negative side of Neutral" ;
VAL_ 2365446654 Joystick2Button13PressedStatus 3 "Not Available" 2 "Error Indicator" 1 "Button pressed" 0 "Button not pressed" ;
VAL_ 2365446654 Joystick2Button14PressedStatus 3 "Not Available" 2 "Error Indicator" 1 "Button pressed" 0 "Button not pressed" ;
VAL_ 2365446654 Joystick2Button15PressedStatus 3 "Not Available" 2 "Error Indicator" 1 "Button pressed" 0 "Button not pressed" ;
VAL_ 2365446654 Joystick2Button16PressedStatus 3 "Not Available" 2 "Error Indicator" 1 "Button pressed" 0 "Button not pressed" ;
VAL_ 2365446654 Jystick2GripXAxisDetentPosStatus 3 "Not Available" 2 "Error Indicator" 1 "In the Detent Position" 0 "Not in the Detent Position" ;
VAL_ 2365446654 Jystick2GripYAxisDetentPosStatus 3 "Not Available" 2 "Error Indicator" 1 "In the Detent Position" 0 "Not in the Detent Position" ;
VAL_ 2365446654 Jystick2ThetaAxisDetentPosStatus 3 "Not Available" 2 "Error Indicator" 1 "In the Detent Position" 0 "Not in the Detent Position" ;
VAL_ 2365446654 Jystck2ThtAxsClckwsPstvPosStatus 3 "Not Available" 2 "Error Indicator" 1 "On positive side of Neutral" 0 "Not on Positive side of Neutral" ;
VAL_ 2365446654 Jystck2ThetaAxisNeutralPosStatus 3 "Not Available" 2 "Error Indicator" 1 "In Neutral Position" 0 "Not in Neutral Position" ;
VAL_ 2365446654 Jystck2GrpYAxsLvrFrwrdPstvPsStts 3 "Not Available" 2 "Error Indicator" 1 "On positive side of Neutral" 0 "Not on Positive side of Neutral" ;
VAL_ 2365446654 Jystck2GrpYAxsLvrBckNgtvPsStatus 3 "Not Available" 2 "Error Indicator" 1 "On negative side of Neutral" 0 "Not on negative side of Neutral" ;
VAL_ 2365446654 Jystck2GripYAxisNeutralPosStatus 3 "Not Available" 2 "Error Indicator" 1 "In Neutral Position" 0 "Not in Neutral Position" ;
VAL_ 2365446654 Jystck2GrpXAxsLvrRghtPstvPsSttus 3 "Not Available" 2 "Error Indicator" 1 "On positive side of Neutral" 0 "Not on Positive side of Neutral" ;
VAL_ 2365446654 Jystck2GrpXAxsLvrLftNgtvPsStatus 3 "Not Available" 2 "Error Indicator" 1 "On negative side of Neutral" 0 "Not on negative side of Neutral" ;
VAL_ 2365446654 Jystck2GripXAxisNeutralPosStatus 3 "Not Available" 2 "Error Indicator" 1 "On negative side of Neutral" 0 "Not on negative side of Neutral" ;
VAL_ 2365446654 Jystck2ThtAxsCntrClckwsNgtvPsStt 3 "Not Available" 2 "Error Indicator" 1 "On negative side of Neutral" 0 "Not on negative side of Neutral" ;
VAL_ 2365446142 Joystick1Button13PressedStatus 3 "Not Available" 2 "Error Indicator" 1 "Button pressed" 0 "Button not pressed" ;
VAL_ 2365446142 Joystick1Button14PressedStatus 3 "Not Available" 2 "Error Indicator" 1 "Button pressed" 0 "Button not pressed" ;
VAL_ 2365446142 Joystick1Button15PressedStatus 3 "Not Available" 2 "Error Indicator" 1 "Button pressed" 0 "Button not pressed" ;
VAL_ 2365446142 Joystick1Button16PressedStatus 3 "Not Available" 2 "Error Indicator" 1 "Button pressed" 0 "Button not pressed" ;
VAL_ 2365446142 Jystick1GripXAxisDetentPosStatus 3 "Not Available" 2 "Error Indicator" 1 "In the Detent Position" 0 "Not in the Detent Position" ;
VAL_ 2365446142 Jystick1GripYAxisDetentPosStatus 3 "Not Available" 2 "Error Indicator" 1 "In the Detent Position" 0 "Not in the Detent Position" ;
VAL_ 2365446142 Jystick1ThetaAxisDetentPosStatus 3 "Not Available" 2 "Error Indicator" 1 "In the Detent Position" 0 "Not in the Detent Position" ;
VAL_ 2365446142 Jystck1ThtAxsClckwsPstvPosStatus 3 "Not Available" 2 "Error Indicator" 1 "On positive side of Neutral" 0 "Not on Positive side of Neutral" ;
VAL_ 2365446142 Jystck1ThetaAxisNeutralPosStatus 3 "Not Available" 2 "Error Indicator" 1 "In Neutral Position" 0 "Not in Neutral Position" ;
VAL_ 2365446142 Jystck1GrpYAxsLvrFrwrdPstvPsStts 3 "Not Available" 2 "Error Indicator" 1 "On positive side of Neutral" 0 "Not on Positive side of Neutral" ;
VAL_ 2365446142 Jystck1GrpYAxsLvrBckNgtvPsStatus 3 "Not Available" 2 "Error Indicator" 1 "On negative side of Neutral" 0 "Not on negative side of Neutral" ;
VAL_ 2365446142 Aftrtrtmnt1DslExhstFldPrprtsPrlm 3 "Not Available" 2 "Error Indicator" 1 "In Neutral Position" 0 "Not in Neutral Position" ;
VAL_ 2365446142 Jystck1GrpXAxsLvrRghtPstvPsSttus 3 "Not Available" 2 "Error Indicator" 1 "On positive side of Neutral" 0 "Not on Positive side of Neutral" ;
VAL_ 2365446142 Jystck1GrpXAxsLvrLftNgtvPsStatus 3 "Not Available" 2 "Error Indicator" 1 "On negative side of Neutral" 0 "Not on negative side of Neutral" ;
VAL_ 2365446142 Jystck1GripXAxisNeutralPosStatus 3 "Not Available" 2 "Error Indicator" 1 "In Neutral Position" 0 "Not in Neutral Position" ;
VAL_ 2365446142 Jystck1ThtAxsCntrClckwsNgtvPsStt 3 "Not Available" 2 "Error Indicator" 1 "On negative side of Neutral" 0 "Not on negative side of Neutral" ;
VAL_ 2566810366 FuelPumpPrimerStatus 3 "Unavailable" 2 "Error" 1 "On" 0 "Off" ;
VAL_ 2566810366 EngVentilationStatus 7 "Not available or not installe" 6 "Not able to determine if sufficiently vented" 5 "Reserved for SAE assignment" 4 "Reserved for SAE assignment" 3 "Currently venting" 2 "Ventilation delay" 1 "Ventilation needed" 0 "Sufficiently vented" ;
VAL_ 2566810366 EngCoolantPreheatedState 3 "Not available or not installed" 2 "Unable to determine  engine coolant pre-heated sufficiently" 1 "Sufficiently pre-heated" 0 "Not sufficiently pre-heated" ;
VAL_ 2566810366 EngOilPreHeatedState 1 "Sufficiently pre-heated" 3 "Not available or not installed" 2 "Unable to determine if engine oil is pre-heated sufficiently" 0 "Not sufficiently pre-heated" ;
VAL_ 2566810366 EngOilPrimingState 3 "Not available or not installed" 2 "Unable to determine if sufficiently lubricated" 1 "Sufficiently lubricated" 0 "Not sufficiently lubricated" ;
VAL_ 2566810366 EngOilPrimingPumpSwitch 3 "Not available or not installed" 2 "Error" 1 "On" 0 "Off" ;
VAL_ 2633929726 SafetyWireStatus 3 "Not available" 2 "Error" 1 "Safety wire has been activated" 0 "Safety wire has not been activated" ;
VAL_ 2566772222 EngVriableGeometryTurbo1CtrlMode 3 "not available" 2 "SAE reserved" 1 "closed loop" 0 "open loop" ;
VAL_ 2566772222 EngFuelCtrlCtrlMode 3 "Not available" 2 "SAE reserved" 1 "Closed loop" 0 "Open loop" ;
VAL_ 2566772222 EngVrblGmtryTrbArCtrlShtoffValve 3 "Not available" 2 "Reserved" 1 "VGT Air Control Shutoff Valve is On" 0 "VGT Air Control Shutoff Valve is Off" ;
VAL_ 2633940734 EngIntakeManifoldPressCtrlMode 3 "Not available" 2 "SAE reserved" 1 "Closed loop" 0 "Open loop" ;
VAL_ 2633940734 EngRotationDirection 3 "Not Available" 2 "Unknown " 1 "ClockWise" 0 "CounterClockWise" ;
VAL_ 2566840318 AFT2ExhDewPoint 3 "Not available" 2 "Error" 1 "Exceeded the dew point" 0 "Not exceeded the dew point" ;
VAL_ 2566840318 AFT2InDewPoint 3 "Not available" 2 "Error" 1 "Exceeded the dew point" 0 "Not exceeded the dew point" ;
VAL_ 2566840318 AFT1ExhDewPoint 3 "Not available" 2 "Error" 1 "Exceeded the dew point" 0 "Not exceeded the dew point" ;
VAL_ 2566840318 AFT1InDewPoint 3 "Not available" 2 "Error" 1 "Exceeded the dew point" 0 "Not exceeded the dew point" ;
VAL_ 2364539902 SCRThermalManagementActive 3 "Don't care" 2 "Reserved" 1 "SCR Thermal Management is active" 0 "SCR Thermal Management is not active" ;
VAL_ 2364539902 DPFThermalManagementActive 3 "Don't care" 2 "Reserved" 1 "DPF Thermal Management is active" 0 "DPF Thermal Management is not active" ;
VAL_ 2364539902 MmntaryEngMaxPowerEnableFeedback 3 "don't care" 2 "reserved" 1 "supported" 0 "disabled" ;
VAL_ 2364539902 VhcleAccelerationRateLimitStatus 3 "Not available" 2 "Reserved" 1 "Limit active" 0 "Limit not active" ;
VAL_ 2364539902 AccelPedal2LowIdleSwitch 3 "Not available" 2 "Error" 1 "Accelerator pedal 2 in low idle condition" 0 "Accelerator pedal 2 not in low idle condition" ;
VAL_ 2364539902 RoadSpeedLimitStatus 3 "Not available" 2 "Error" 1 "Not Active" 0 "Active" ;
VAL_ 2364539902 AccelPedalKickdownSwitch 3 "Not available" 2 "Error" 1 "Kickdown active" 0 "Kickdown passive" ;
VAL_ 2364539902 AccelPedal1LowIdleSwitch 3 "Not available" 2 "Error" 1 "Accelerator pedal 1 in low idle condition" 0 "Accelerator pedal 1 not in low idle condition" ;
VAL_ 2364540158 EngStarterMode 15 "not available" 14 "error" 13 "error, legacy implementation only" 12 "starter inhibited" 11 "starter inhibited due to ignition key cycle required" 10 "starter inhibited due to active emissions control system condition" 9 "starter inhibited due to intake air shutoff valve being active" 8 "starter inhibited due to starter over-temp" 7 "starter inhibited due to active immobilizer" 6 "starter inhibited due to driveline engaged or other transmission inhibit" 5 "starter inhibited due to engine not ready for start" 4 "starter inhibited due to engine already running" 3 "start finished" 2 "starter active and engaged" 1 "starter active but not engaged" 0 "start not requested" ;
VAL_ 2364540158 ActlEngPrcntTorqueHighResolution 7 "+0.875%" 1 "+0.125%" 0 "+0.000%" ;
VAL_ 2566767870 RailroadMode 3 "Not available" 2 "Error" 1 "Active" 0 "Inactive" ;
VAL_ 2566767870 EmergencyBrakingActive 3 "not available" 2 "reserved" 1 "active" 0 "inactive" ;
VAL_ 2566767870 PrkngBrakeActuatorFullyActivated 3 "Not available" 2 "Error" 1 "Parking Brake Actuator fully activated" 0 "Parking Brake Actuator not fully activated" ;
VAL_ 2566767870 XBRActiveCtrlMode 15 "Not available" 3 "Maximum mode of XBR acceleration control being executed" 2 "Addition mode of XBR acceleration control being executed" 1 "Driver's brake demand being executed" 0 "No brake demand being executed" ;
VAL_ 2566767870 XBRSystemState 3 "not available" 2 "No external brake demand will be accepted" 1 "Only external brake demand of highest XBR Priority" 0 "Any external brake demand will be accepted" ;
VAL_ 2566767870 FoundationBrakeUse 3 "Not available" 2 "Reserved" 1 "Foundation brakes in use" 0 "Foundation brakes not in use" ;
VAL_ 2566767870 HillHolderMode 7 "Not available" 6 "Hill holder not functional" 5 "Reserved" 4 "Reserved" 3 "Active,  but may activate parking brake if needed." 2 "Active,  but will change to inactive in a short time" 1 "Active" 0 "Inactive" ;
VAL_ 2566767870 HaltBrakeMode 7 "Not available" 6 "Halt brake not functional" 2 "Active,  but not functioning properly" 1 "Active" 0 "Inactive" ;
VAL_ 2566767870 BrakeTempWarning 3 "not available" 2 "Reserved" 1 "Active" 0 "Not Active" ;
VAL_ 2565865982 RailroadModeSw 3 "Not available" 2 "Error" 1 "Railroad mode switch active" 0 "Railroad mode switch passive" ;
VAL_ 2565865982 TrctrMntdTrailerABSWarningSignal 3 "Take no action" 2 "Reserved" 1 "On" 0 "Off" ;
VAL_ 2565865982 TrailerABSStatus 3 "Trailer ABS Status Information Not Available or Parameter Not Supported" 2 "Reserved" 1 "Trailer ABS Active" 0 "Trailer ABS Status Information Available But Not Active" ;
VAL_ 2565865982 HaltBrakeSwitch 3 "Not available" 2 "Error" 1 "Halt brake switch active" 0 "Halt brake switch passive" ;
VAL_ 2565865982 ATC_ASRInformationSignal 3 "Take no action" 2 "Reserved" 1 "On" 0 "Off" ;
VAL_ 2565865982 ABS_EBSAmberWarningSignal 3 "Take no action" 2 "Reserved" 1 "On" 0 "Off" ;
VAL_ 2565865982 EBSRedWarningSignal 3 "Take no action" 2 "Reserved" 1 "On" 0 "Off" ;
VAL_ 2565865982 ABSFullyOperational 3 "Not available" 2 "Reserved" 1 "Fully Operational" 0 "Not Fully Operational" ;
VAL_ 2565865982 RemoteAccelEnableSwitch 3 "Not available" 2 "Error" 1 "On" 0 "Off" ;
VAL_ 2565865982 EngAuxShutdownSwitch 3 "Not available" 2 "Error" 1 "On" 0 "Off" ;
VAL_ 2565865982 EngDerateSwitch 3 "Not available" 2 "Error" 1 "On" 0 "Off" ;
VAL_ 2565865982 AccelInterlockSwitch 3 "Not available" 2 "Error" 1 "On" 0 "Off" ;
VAL_ 2565865982 TractionCtrlOverrideSwitch 3 "Not available or not installed" 2 "Error" 1 "On" 0 "Off" ;
VAL_ 2565865982 ASRHillHolderSwitch 3 "Not available" 2 "Error" 1 "ASR 밾ill holder� switch active" 0 "ASR 밾ill holder� switch passive" ;
VAL_ 2565865982 ASROffroadSwitch 3 "Not available" 2 "Error" 1 "ASR off-road switch active" 0 "ASR off-road switch passive" ;
VAL_ 2565865982 ABSOffroadSwitch 3 "Not available" 2 "Error" 1 "ABS off-road switch active" 0 "ABS off-road switch passive" ;
VAL_ 2565865982 EBSBrakeSwitch 3 "Not available" 2 "Error" 1 "Brake pedal is being pressed" 0 "Brake pedal is not being pressed" ;
VAL_ 2565865982 AntiLockBrakingActive 3 "Not available" 2 "Reserved" 1 "ABS active" 0 "ABS passive but installed" ;
VAL_ 2565865982 ASRBrakeCtrlActive 3 "Not available" 2 "Reserved" 1 "ASR brake control active" 0 "ASR brake control passive but installed" ;
VAL_ 2565865982 ASREngCtrlActive 3 "Not available" 2 "Reserved" 1 "ASR engine control active" 0 "ASR engine control passive but installed" ;
VAL_ 2565867262 DiffLockStRearAxle3 1 "Differential lock engaged" 0 "Differential lock disengaged" 3 "Not available" 2 "Error" ;
VAL_ 2565867262 RearAxleGroupEngagementStatus 3 "not available" 2 "error" 1 "rear axle group engaged" 0 "rear axle group disengaged" ;
VAL_ 2565867262 FrontAxleGroupEngagementStatus 3 "not available" 2 "error" 1 "front axle group engaged" 0 "front axle group disengaged" ;
VAL_ 2565867262 DiffLockStateCentralRear 3 "Not available" 2 "Error" 1 "Differential lock engaged" 0 "Differential lock disengaged" ;
VAL_ 2565867262 DiffLockStateCentralFront 3 "Not available" 2 "Error" 1 "Differential lock engaged" 0 "Differential lock disengaged" ;
VAL_ 2565867262 DiffLockStateCentral 3 "Not available" 2 "Error" 1 "Differential lock engaged" 0 "Differential lock disengaged" ;
VAL_ 2565867262 DiffLockStateRearAxle2 3 "Not available" 2 "Error" 1 "Differential lock engaged" 0 "Differential lock disengaged" ;
VAL_ 2565867262 DiffLockStateRearAxle1 3 "Not available" 2 "Error" 1 "Differential lock engaged" 0 "Differential lock disengaged" ;
VAL_ 2565867262 DiffLockStateFrontAxle2 3 "Not available" 2 "Error" 1 "Differential lock engaged" 0 "Differential lock disengaged" ;
VAL_ 2565867262 DiffLockStateFrontAxle1 3 "Not available" 2 "Error" 1 "Differential lock engaged" 0 "Differential lock disengaged" ;
VAL_ 2566768382 EngCldStrtFlIgniterRelayFeedback 3 "Not available" 2 "Error" 1 "On" 0 "Off" ;
VAL_ 2566768382 EngColdStartFuelIgniterRelay 3 "Don't care/take no action" 2 "Reserved" 1 "On" 0 "Off" ;
VAL_ 2566768382 EngStartEnableDevice2Config 15 "not available" 4 "electric intake air heater installed" 3 "ether injection installed" 2 "fuelled start installed" 1 "glow plugs installed" 0 "no start enable device 2 installed" ;
VAL_ 2566768382 EngStartEnableDevice1Config 15 "not available" 4 "electric intake air heater installed" 3 "ether injection installed" 2 "fuelled start installed" 1 "glow plugs installed" 0 "no start enable device 1 installed" ;
VAL_ 2566768382 EngStartEnableDevice2 3 "not available" 2 "reserved" 1 "start enable ON" 0 "start enable OFF" ;
VAL_ 2566768382 EngStartEnableDevice1 3 "not available" 2 "reserved" 1 "start enable ON" 0 "start enable OFF" ;
VAL_ 2566771966 AFTDEFDosingModeCmd 7 "Don뭪 care/Take no Action" 6 "Reserved for status error value" 5 "Reserved" 4 "Reserved" 3 "Reserved" 2 "Reserved" 1 "Reduced DEF Dosing Mode" 0 "Standard DEF Dosing Mode" ;
VAL_ 2566771966 VehTrailerStatus 3 "Not available" 2 "Error" 1 "Trailer is detected" 0 "Trailer is not detected" ;
VAL_ 2566771966 TransOilLevelRq 3 "Don't care / take no action" 2 "Reserved" 1 "Transmission oil level reading desired" 0 "No transmission oil level reading desired" ;
VAL_ 2566771966 FifthWheelReleaseCtrl 3 "Not Available" 2 "Error" 1 "Coupler Unlocked" 0 "Coupler Locked" ;
VAL_ 2566771966 FfthWhlRleaseCtrlSecurityLockout 3 "Not Available" 2 "Error" 1 "Fifth wheel release Enabled" 0 "Fifth wheel release Disabled" ;
VAL_ 2566771966 TransferCaseSelectorSwitch 7 "Not available" 6 "Error indicator" 5 "Reserved for SAE assignment" 4 "4 wheel low" 3 "2 wheel low" 2 "Neutral" 1 "4 wheel high" 0 "2 wheel high" ;
